VERSION ""

NS_ :

BS_:

BU_: HCM IPMA_ADAS PSCM ABS_ESC PCM ECM_HEV VDM CMR_DSMC SOBDMC_HPCM GWM _delete AWD_DLCM GENERIC TSTR

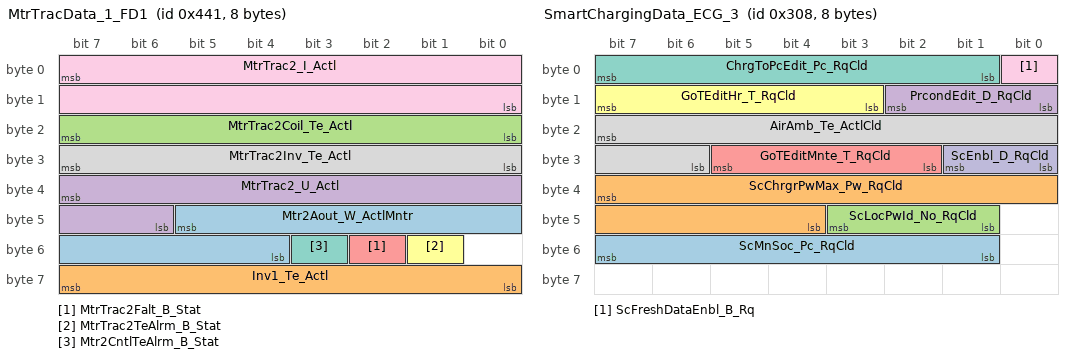
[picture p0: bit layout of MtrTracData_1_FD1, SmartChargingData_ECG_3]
BO_ 1089 MtrTracData_1_FD1: 8 SOBDMC_HPCM
 SG_ Mtr2Aout_W_ActlMntr : 45|10@0+ (6.28,-3209) [-3209|3209.16] "radians/sec"  GWM
 SG_ Inv1_Te_Actl : 63|8@0+ (1,-40) [-40|213] "degC"  GWM
 SG_ MtrTrac2Coil_Te_Actl : 23|8@0+ (1,-40) [-40|213] "degC"  GWM
 SG_ MtrTrac2_U_Actl : 39|10@0+ (1,0) [0|1023] "volt"  GWM
 SG_ MtrTrac2Falt_B_Stat : 50|1@0+ (1,0) [0|1] "SED"  GWM
 SG_ MtrTrac2TeAlrm_B_Stat : 49|1@0+ (1,0) [0|1] "SED"  GWM
 SG_ Mtr2CntlTeAlrm_B_Stat : 51|1@0+ (1,0) [0|1] "SED"  GWM
 SG_ MtrTrac2Inv_Te_Actl : 31|8@0+ (1,-40) [-40|213] "degC"  GWM
 SG_ MtrTrac2_I_Actl : 7|16@0+ (0.1,-1000) [-1000|5553.4] "ampere"  GWM

BO_ 1778 TesterPhysicalReqSODCMC: 64 TSTR
 SG_ TesterPhysicalReqSODCMC : 7|64@0+ (1,0) [0|1.84467E+019] "unitless"  IPMA_ADAS

BO_ 776 SmartChargingData_ECG_3: 8 GWM
 SG_ ScMnSoc_Pc_RqCld : 55|7@0+ (1,0) [0|127] "percent"  SOBDMC_HPCM
 SG_ ScChrgrPwMax_Pw_RqCld : 39|12@0+ (50,0) [0|204700] "watts"  SOBDMC_HPCM
 SG_ ScLocPwId_No_RqCld : 43|3@0+ (1,0) [0|7] "unitless"  SOBDMC_HPCM
 SG_ PrcondEdit_D_RqCld : 10|3@0+ (1,0) [0|7] "SED"  SOBDMC_HPCM
 SG_ GoTEditMnte_T_RqCld : 29|4@0+ (1,0) [0|15] "SED"  SOBDMC_HPCM
 SG_ GoTEditHr_T_RqCld : 15|5@0+ (1,0) [0|29] "SED"  SOBDMC_HPCM
 SG_ ChrgToPcEdit_Pc_RqCld : 7|7@0+ (1,0) [0|125] "percent"  SOBDMC_HPCM
 SG_ AirAmb_Te_ActlCld : 23|10@0+ (0.25,-128) [-128|127.75] "degC"  SOBDMC_HPCM
 SG_ ScFreshDataEnbl_B_Rq : 0|1@0+ (1,0) [0|1] "SED"  SOBDMC_HPCM
 SG_ ScEnbl_D_RqCld : 25|2@0+ (1,0) [0|3] "SED"  SOBDMC_HPCM

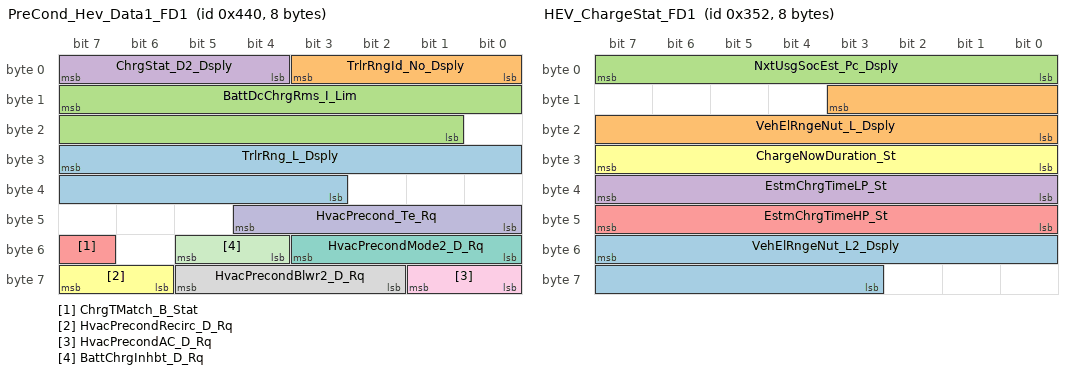
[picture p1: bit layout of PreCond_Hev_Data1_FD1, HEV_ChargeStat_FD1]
BO_ 1088 PreCond_Hev_Data1_FD1: 8 SOBDMC_HPCM
 SG_ TrlrRng_L_Dsply : 31|13@0+ (0.1,0) [0|818.9] "kilometer"  GWM
 SG_ TrlrRngId_No_Dsply : 3|4@0+ (1,0) [0|15] "unitless"  GWM
 SG_ BattDcChrgRms_I_Lim : 15|15@0+ (0.05,0) [0|1638.25] "ampere"  GWM
 SG_ ChrgStat_D2_Dsply : 7|4@0+ (1,0) [0|15] "SED"  GWM
 SG_ ChrgTMatch_B_Stat : 55|1@0+ (1,0) [0|1] "SED"  GWM,GENERIC
 SG_ HvacPrecondRecirc_D_Rq : 63|2@0+ (1,0) [0|3] "SED"  GWM,GENERIC
 SG_ HvacPrecondMode2_D_Rq : 51|4@0+ (1,0) [0|15] "SED"  GWM,GENERIC
 SG_ HvacPrecondBlwr2_D_Rq : 61|4@0+ (1,0) [0|15] "SED"  GWM,GENERIC
 SG_ HvacPrecondAC_D_Rq : 57|2@0+ (1,0) [0|3] "SED"  GWM,GENERIC
 SG_ HvacPrecond_Te_Rq : 44|5@0+ (0.5,14.5) [14.5|30] "deg C"  GWM,GENERIC
 SG_ BattChrgInhbt_D_Rq : 53|2@0+ (1,0) [0|3] "SED"  GWM,GENERIC

BO_ 850 HEV_ChargeStat_FD1: 8 SOBDMC_HPCM
 SG_ VehElRngeNut_L2_Dsply : 55|13@0+ (0.1,0) [0|818.9] "km"  GWM
 SG_ VehElRngeNut_L_Dsply : 11|12@0+ (0.1,0) [0|409.3] "km"  GWM
 SG_ NxtUsgSocEst_Pc_Dsply : 7|8@0+ (0.5,0) [0|126.5] "unitless"  GWM
 SG_ EstmChrgTimeLP_St : 39|8@0+ (0.1,0) [0|25.4] "hour"  GWM
 SG_ EstmChrgTimeHP_St : 47|8@0+ (0.1,0) [0|25.4] "hour"  GWM
 SG_ ChargeNowDuration_St : 31|8@0+ (0.1,0) [0|25.4] "hour"  GWM

BO_ 1795 TesterPhysicalReqAWD: 64 TSTR
 SG_ TesterPhysicalReqAWD : 7|64@0+ (1,0) [0|1.84467E+019] "unitless"  AWD_DLCM

BO_ 1803 TesterPhysicalResAWD: 64 AWD_DLCM
 SG_ TesterPhysicalResAWD : 7|64@0+ (1,0) [0|1.84467E+019] "unitless"  TSTR

BO_ 2611026136 PARSEDPhysGWM_ECGtoSODCMD: 64 GWM
 SG_ PARSEDPhysGWM_ECGtoSODCMD : 7|29@0+ (1,0) [0|536870911] "unitless"  IPMA_ADAS

BO_ 2611175494 PARSEDPhysSODCMDtoGWM_ECG: 64 IPMA_ADAS
 SG_ PARSEDPhysSODCMDtoGWM_ECG : 7|29@0+ (1,0) [0|536870911] "unitless"  GWM

BO_ 2612224070 PARSEDPushSODCMDtoGWM: 8 IPMA_ADAS
 SG_ PARSEDPushSODCMDtoGWM : 7|29@0+ (1,0) [0|536870911] "unitless"  GWM

BO_ 2611054808 PARSEDPhysGWM_ECGtoSODL: 64 GWM
 SG_ PARSEDPhysGWM_ECGtoSODL : 7|29@0+ (1,0) [0|536870911] "unitless"  IPMA_ADAS

BO_ 2611175523 PARSEDPhysSODRtoGWM_ECG: 64 IPMA_ADAS
 SG_ PARSEDPhysSODRtoGWM_ECG : 7|29@0+ (1,0) [0|536870911] "unitless"  GWM

BO_ 2612224099 PARSEDPushSODRtoGWM_ECG: 8 IPMA_ADAS
 SG_ PARSEDPushSODRtoGWM_ECG : 7|29@0+ (1,0) [0|536870911] "unitless"  GWM

BO_ 2611055832 PARSEDPhysGWM_ECGtoSODR: 64 GWM
 SG_ PARSEDPhysGWM_ECGtoSODR : 7|29@0+ (1,0) [0|536870911] "unitless"  IPMA_ADAS

BO_ 2611175522 PARSEDPhysSODLtoGWM_ECG: 64 IPMA_ADAS
 SG_ PARSEDPhysSODLtoGWM_ECG : 7|29@0+ (1,0) [0|536870911] "unitless"  GWM

BO_ 2612224098 PARSEDPushSODLtoGWM_ECG: 8 IPMA_ADAS
 SG_ PARSEDPushSODLtoGWM_ECG : 7|29@0+ (1,0) [0|536870911] "unitless"  GWM

BO_ 2609927384 OTAPhysGWM_ECGtoCCM: 64 GWM
 SG_ OTAPhysGWM_ECGtoCCM : 7|29@0+ (1,0) [0|536870911] "unitless"  IPMA_ADAS

BO_ 2610126869 OTAPhysCCMtoGWM_ECG: 64 IPMA_ADAS
 SG_ OTAPhysCCMtoGWM_ECG : 7|29@0+ (1,0) [0|536870911] "unitless"  GWM

BO_ 2609976536 OTAPhysGWM_ECGtoSODCMC: 64 GWM
 SG_ OTAPhysGWM_ECGtoSODCMC : 7|29@0+ (1,0) [0|536870911] "unitless"  IPMA_ADAS

BO_ 2610126917 OTAPhysSODCMCtoGWM_ECG: 64 IPMA_ADAS
 SG_ OTAPhysSODCMCtoGWM_ECG : 7|29@0+ (1,0) [0|536870911] "unitless"  GWM

BO_ 2609977560 OTAPhysGWM_ECGtoSODCMD: 64 GWM
 SG_ OTAPhysGWM_ECGtoSODCMD : 7|29@0+ (1,0) [0|536870911] "unitless"  IPMA_ADAS

BO_ 2610126918 OTAPhysSODCMDtoGWM_ECG: 64 IPMA_ADAS
 SG_ OTAPhysSODCMDtoGWM_ECG : 7|29@0+ (1,0) [0|536870911] "unitless"  GWM

BO_ 2610007256 OTAPhysGWM_ECGtoSODR: 64 GWM
 SG_ OTAPhysGWM_ECGtoSODR : 7|29@0+ (1,0) [0|536870911] "unitless"  IPMA_ADAS

BO_ 2610126947 OTAPhysSODRtoGWM_ECG: 64 IPMA_ADAS
 SG_ OTAPhysSODRtoGWM_ECG : 7|29@0+ (1,0) [0|536870911] "unitless"  GWM

BO_ 2612224017 PARSEDPushSOBDMCtoGWM_FD1: 8 SOBDMC_HPCM
 SG_ PARSEDPushSOBDMCtoGWM_ECG : 7|29@0+ (1,0) [0|536870911] "unitless"  GWM

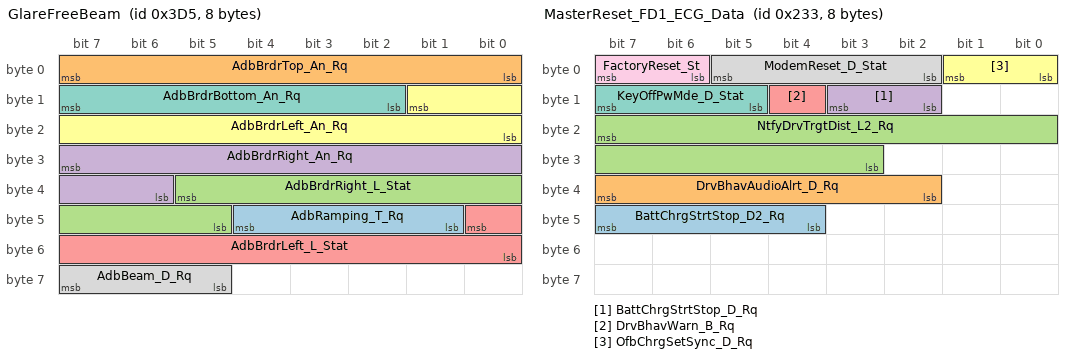
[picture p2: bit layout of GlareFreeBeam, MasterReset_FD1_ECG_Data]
BO_ 981 GlareFreeBeam: 8 IPMA_ADAS
 SG_ AdbRamping_T_Rq : 44|4@0+ (200,0) [0|3000] "millisecond"  HCM,GWM
 SG_ AdbBrdrTop_An_Rq : 7|8@0+ (0.04,-9.54) [-9.54|0.58] "degrees"  HCM,GWM
 SG_ AdbBrdrRight_L_Stat : 37|9@0+ (2,0) [0|1018] "meter"  HCM,GWM
 SG_ AdbBrdrRight_An_Rq : 31|10@0+ (0.04,-20.4) [-20.4|20.44] "degrees"  HCM,GWM
 SG_ AdbBrdrLeft_L_Stat : 40|9@0+ (2,0) [0|1018] "meter"  HCM,GWM
 SG_ AdbBrdrLeft_An_Rq : 9|10@0+ (0.04,-20.4) [-20.4|20.44] "degrees"  HCM,GWM
 SG_ AdbBrdrBottom_An_Rq : 15|6@0+ (0.04,-1.86) [-1.86|0.58] "degrees"  HCM,GWM
 SG_ AdbBeam_D_Rq : 63|3@0+ (1,0) [0|7] "SED"  HCM,GWM

BO_ 810 ECG_Data_FD1: 8 GWM
 SG_ VehHorn_B_RqOccAlrt : 58|1@0+ (1,0) [0|1] "SED"  GENERIC
 SG_ RmtViewMde_B_Rq : 59|1@0+ (1,0) [0|1] "SED"  GENERIC
 SG_ DteCldAcceptData_B_Rq : 60|1@0+ (1,0) [0|1] "SED"  SOBDMC_HPCM
 SG_ DteCldCnclRoute_B_Rq : 61|1@0+ (1,0) [0|1] "SED"  SOBDMC_HPCM
 SG_ NtfyDrvTrgtDist_L_Rq : 23|12@0+ (0.1,0) [0|409.5] "Km"  SOBDMC_HPCM
 SG_ NtfyDrvSocLvl1_Pc_Rq : 39|7@0+ (1,0) [0|127] "%"  SOBDMC_HPCM
 SG_ PtRmtRprt_D_Stat : 27|4@0+ (1,0) [0|15] "SED"  SOBDMC_HPCM
 SG_ ChrgrPncEnbl_D_Rq : 9|2@0+ (1,0) [0|3] "SED"  GENERIC
 SG_ OneTEditActv_B_RqCld : 32|1@0+ (1,0) [0|1] "SED"  SOBDMC_HPCM
 SG_ GoTElementEdit_No_RqCld : 43|4@0+ (1,0) [0|15] "unitless"  SOBDMC_HPCM
 SG_ OBCCSerial_D_Rq : 45|2@0+ (1,0) [0|3] "SED"  GENERIC
 SG_ ExtLghtDsply_B_StatArb : 7|1@0+ (1,0) [0|1] "SED"  GENERIC
 SG_ ExtLghtRight_D_RqOta : 12|3@0+ (1,0) [0|7] "SED"  GENERIC
 SG_ ExtLghtRear_D_RqOta : 15|3@0+ (1,0) [0|7] "SED"  GENERIC
 SG_ ExtLghtLeft_D_RqOta : 3|3@0+ (1,0) [0|7] "SED"  GENERIC
 SG_ ExtLghtFront_D_RqOta : 6|3@0+ (1,0) [0|7] "SED"  GENERIC
 SG_ TlghtTest_D_RqArb : 47|2@0+ (1,0) [0|3] "SED"  GENERIC
 SG_ ChrgrPncSustn_B_Rq : 0|1@0+ (1,0) [0|1] "SED"  GENERIC
 SG_ GoTAirAmb_Te_ActlCld : 55|10@0+ (0.25,-128) [-128|127.75] "degC"  SOBDMC_HPCM

BO_ 563 MasterReset_FD1_ECG_Data: 8 GWM
 SG_ BattChrgStrtStop_D2_Rq : 47|4@0+ (1,0) [0|15] "SED"  SOBDMC_HPCM
 SG_ DrvBhavAudioAlrt_D_Rq : 39|6@0+ (1,0) [0|63] "SED"  GENERIC
 SG_ NtfyDrvTrgtDist_L2_Rq : 23|13@0+ (0.1,0) [0|818.9] "Km" Vector__XXX
 SG_ BattChrgStrtStop_D_Rq : 11|2@0+ (1,0) [0|3] "SED" Vector__XXX
 SG_ DrvBhavWarn_B_Rq : 12|1@0+ (1,0) [0|1] "SED"  GENERIC
 SG_ OfbChrgSetSync_D_Rq : 1|2@0+ (1,0) [0|3] "SED"  SOBDMC_HPCM
 SG_ KeyOffPwMde_D_Stat : 15|3@0+ (1,0) [0|7] "SED"  GENERIC
 SG_ ModemReset_D_Stat : 5|4@0+ (1,0) [0|15] "SED"  GENERIC
 SG_ FactoryReset_St : 7|2@0+ (1,0) [0|3] "SED"  GENERIC

BO_ 2609923288 OTAPhysGWM_ECGtoSOBDMC_FD1: 64 GWM
 SG_ OTAPhysGWM_ECGtoSOBDMC : 7|29@0+ (1,0) [0|536870911] "unitless"  SOBDMC_HPCM

BO_ 2610126865 OTAPhysSOBDMCtoGWM_FD1: 64 SOBDMC_HPCM
 SG_ OTAPhysSOBDMCtoGWM_ECG : 7|29@0+ (1,0) [0|536870911] "unitless"  GWM

BO_ 2610971864 PARSEDPhysGWMtoSOBDMC_FD1: 64 GWM
 SG_ PARSEDPhysGWM_ECGtoSOBDMC : 7|29@0+ (1,0) [0|536870911] "unitless"  SOBDMC_HPCM

BO_ 2611175441 PARSEDPhysSOBDMCtoGWM_FD1: 64 SOBDMC_HPCM
 SG_ PARSEDPhysSOBDMCtoGWM_ECG : 7|29@0+ (1,0) [0|536870911] "unitless"  GWM

BO_ 2610126946 OTAPhysSODLtoGWM_ECG: 64 IPMA_ADAS
 SG_ OTAPhysSODLtoGWM_ECG : 7|29@0+ (1,0) [0|536870911] "unitless"  GWM

BO_ 2610006232 OTAPhysGWM_ECGtoSODL: 64 GWM
 SG_ OTAPhysGWM_ECGtoSODL : 7|29@0+ (1,0) [0|536870911] "unitless"  IPMA_ADAS

BO_ 1993 TesterPhysicalResCMR_DSMC: 64 CMR_DSMC
 SG_ TesterPhysicalResCMR_DSMC : 7|64@0+ (1,0) [0|1.84467E+019] "unitless"  TSTR

BO_ 1985 TesterPhysicalReqCMR_DSMC: 64 TSTR
 SG_ TesterPhysicalReqCMR_DSMC : 7|64@0+ (1,0) [0|1.84467E+019] "unitless"  CMR_DSMC

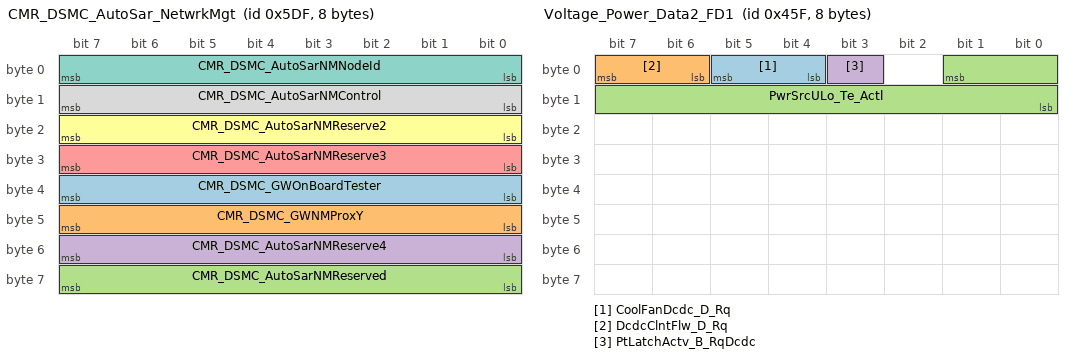
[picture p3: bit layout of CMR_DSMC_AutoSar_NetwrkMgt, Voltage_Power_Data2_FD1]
BO_ 1503 CMR_DSMC_AutoSar_NetwrkMgt: 8 CMR_DSMC
 SG_ CMR_DSMC_GWOnBoardTester : 39|8@0+ (1,0) [0|255] "unitless"  GENERIC
 SG_ CMR_DSMC_GWNMProxY : 47|8@0+ (1,0) [0|255] "unitless"  GENERIC
 SG_ CMR_DSMC_AutoSarNMReserved : 63|8@0+ (1,0) [0|255] "unitless"  GENERIC
 SG_ CMR_DSMC_AutoSarNMReserve4 : 55|8@0+ (1,0) [0|255] "unitless"  GENERIC
 SG_ CMR_DSMC_AutoSarNMReserve3 : 31|8@0+ (1,0) [0|255] "unitless"  GENERIC
 SG_ CMR_DSMC_AutoSarNMReserve2 : 23|8@0+ (1,0) [0|255] "unitless"  GENERIC
 SG_ CMR_DSMC_AutoSarNMNodeId : 7|8@0+ (1,0) [0|255] "unitless"  GENERIC
 SG_ CMR_DSMC_AutoSarNMControl : 15|8@0+ (1,0) [0|255] "unitless"  GENERIC

BO_ 1119 Voltage_Power_Data2_FD1: 8 GWM
 SG_ CoolFanDcdc_D_Rq : 5|2@0+ (1,0) [0|3] "SED"  SOBDMC_HPCM
 SG_ DcdcClntFlw_D_Rq : 7|2@0+ (1,0) [0|3] "SED"  SOBDMC_HPCM
 SG_ PwrSrcULo_Te_Actl : 1|10@0+ (0.5,-50) [-50|460.5] "degC" Vector__XXX
 SG_ PtLatchActv_B_RqDcdc : 3|1@0+ (1,0) [0|1] "SED" Vector__XXX

BO_ 2022 TesterPhysicalReqSOBDMC_FD: 64 TSTR
 SG_ TesterPhysicalReqSOBDMC : 7|64@0+ (1,0) [0|1.84467E+019] "unitless"  SOBDMC_HPCM

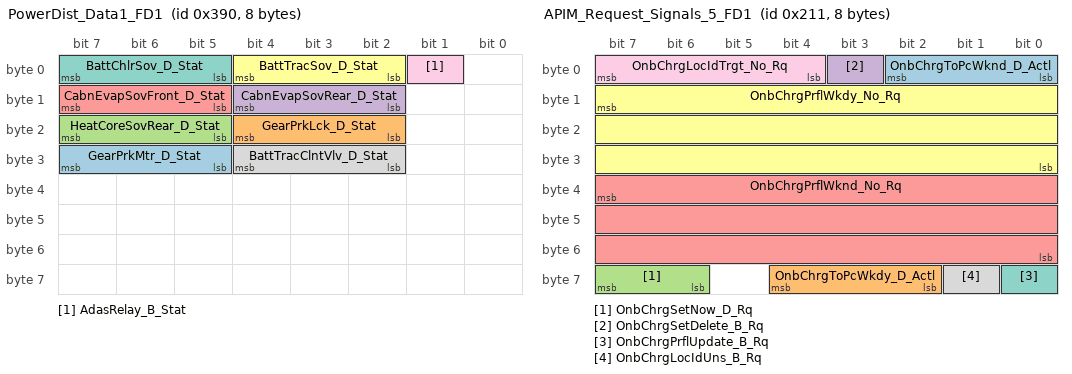
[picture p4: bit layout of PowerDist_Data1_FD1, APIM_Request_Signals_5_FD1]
BO_ 912 PowerDist_Data1_FD1: 8 GWM
 SG_ GearPrkMtr_D_Stat : 31|3@0+ (1,0) [0|7] "SED"  SOBDMC_HPCM
 SG_ GearPrkLck_D_Stat : 20|3@0+ (1,0) [0|7] "SED"  SOBDMC_HPCM
 SG_ HeatCoreSovRear_D_Stat : 23|3@0+ (1,0) [0|7] "SED" Vector__XXX
 SG_ CabnEvapSovRear_D_Stat : 12|3@0+ (1,0) [0|7] "SED" Vector__XXX
 SG_ CabnEvapSovFront_D_Stat : 15|3@0+ (1,0) [0|7] "SED"  SOBDMC_HPCM
 SG_ BattTracSov_D_Stat : 4|3@0+ (1,0) [0|7] "SED" Vector__XXX
 SG_ BattChlrSov_D_Stat : 7|3@0+ (1,0) [0|7] "SED"  SOBDMC_HPCM
 SG_ BattTracClntVlv_D_Stat : 28|3@0+ (1,0) [0|7] "SED"  SOBDMC_HPCM
 SG_ AdasRelay_B_Stat : 1|1@0+ (1,0) [0|1] "SED"  GENERIC

BO_ 651 TCU_Send_Signals_FD1: 8 GWM
 SG_ TelematicsSrvc_D_St : 47|3@0+ (1,0) [0|7] "SED" Vector__XXX
 SG_ EmgcyCallMute_D_Stat : 39|3@0+ (1,0) [0|7] "SED"  GENERIC

BO_ 2609955032 OTAPhysGWM_ECGtoPSCM: 64 GWM
 SG_ OTAPhysGWM_ECGtoPSCM : 7|29@0+ (1,0) [0|536870911] "unitless"  PSCM

BO_ 2610126896 OTAPhysPSCMtoGWM_ECG: 64 PSCM
 SG_ OTAPhysPSCMtoGWM_ECG : 7|29@0+ (1,0) [0|536870911] "unitless"  GWM

BO_ 2611003608 PARSEDPhysGWM_ECGtoPSCM: 64 GWM
 SG_ PARSEDPhysGWM_ECGtoPSCM : 7|29@0+ (1,0) [0|536870911] "unitless"  PSCM

BO_ 2612224048 PARSEDPushPSCMtoGWM_ECG: 8 PSCM
 SG_ PARSEDPushPSCMtoGWM_ECG : 7|29@0+ (1,0) [0|536870911] "unitless"  GWM

BO_ 2611175472 PARSEDPhysPSCMtoGWM_ECG: 64 PSCM
 SG_ PARSEDPhysPSCMtoGWM_ECG : 7|29@0+ (1,0) [0|536870911] "unitless"  GWM

BO_ 1150 LocationServices_Data1_FD1: 8 GWM
 SG_ LocationServices_1 : 7|64@0+ (1,0) [0|1.84467440737096E+019] "unitless"  SOBDMC_HPCM,HCM,IPMA_ADAS

BO_ 2612224033 PARSEDPushIPMAtoGWM_ECG: 8 IPMA_ADAS
 SG_ PARSEDPushIPMAtoGWM_ECG : 7|29@0+ (1,0) [0|536870911] "unitless"  GWM

BO_ 2609939672 OTAPhysGWM_ECGtoIPMA: 64 GWM
 SG_ OTAPhysGWM_ECGtoIPMA : 7|29@0+ (1,0) [0|536870911] "unitless"  IPMA_ADAS

BO_ 2610126881 OTAPhysIPMAtoGWM_ECG: 64 IPMA_ADAS
 SG_ OTAPhysIPMAtoGWM_ECG : 7|29@0+ (1,0) [0|536870911] "unitless"  GWM

BO_ 2612043992 PARSEDPushFcGWM_ECGtoABS: 8 GWM
 SG_ PARSEDPushFcGWM_ECGtoABS : 7|29@0+ (1,0) [0|536870911] "unitless"  ABS_ESC

BO_ 2610995416 PARSEDPhysGWM_ECGtoABS: 64 GWM
 SG_ PARSEDPhysGWM_ECGtoABS : 7|29@0+ (1,0) [0|536870911] "unitless"  ABS_ESC

BO_ 2612224040 PARSEDPushABStoGWM_ECG: 8 ABS_ESC
 SG_ PARSEDPushABStoGWM_ECG : 7|29@0+ (1,0) [0|536870911] "unitless"  GWM

BO_ 2611175464 PARSEDPhysABStoGWM_ECG: 64 ABS_ESC
 SG_ PARSEDPhysABStoGWM_ECG : 7|29@0+ (1,0) [0|536870911] "Unitless"  GWM

BO_ 529 APIM_Request_Signals_5_FD1: 8 GWM
 SG_ OnbChrgToPcWknd_D_Actl : 2|3@0+ (1,0) [0|7] "percent"  SOBDMC_HPCM
 SG_ OnbChrgToPcWkdy_D_Actl : 60|3@0+ (1,0) [0|7] "percent"  SOBDMC_HPCM
 SG_ OnbChrgSetNow_D_Rq : 63|2@0+ (1,0) [0|3] "SED"  SOBDMC_HPCM
 SG_ OnbChrgSetDelete_B_Rq : 3|1@0+ (1,0) [0|1] "SED"  SOBDMC_HPCM
 SG_ OnbChrgPrflWknd_No_Rq : 39|24@0+ (1,0) [0|16777215] "unitless"  SOBDMC_HPCM
 SG_ OnbChrgPrflWkdy_No_Rq : 15|24@0+ (1,0) [0|16777215] "unitless"  SOBDMC_HPCM
 SG_ OnbChrgPrflUpdate_B_Rq : 56|1@0+ (1,0) [0|1] "SED"  SOBDMC_HPCM
 SG_ OnbChrgLocIdUns_B_Rq : 57|1@0+ (1,0) [0|1] "SED"  SOBDMC_HPCM
 SG_ OnbChrgLocIdTrgt_No_Rq : 7|4@0+ (1,0) [0|15] "Unitless"  SOBDMC_HPCM

BO_ 1679 SOBDMC_RapidData_Resp4_FD1: 8 SOBDMC_HPCM
 SG_ UUDTSOBDMCResponse4 : 7|64@0+ (1,0) [0|1.84467440737096E+019] "unitless"  TSTR

BO_ 1678 SOBDMC_RapidData_Resp3_FD1: 8 SOBDMC_HPCM
 SG_ UUDTSOBDMCResponse3 : 7|64@0+ (1,0) [0|1.84467440737096E+019] "unitless"  TSTR

BO_ 1677 SOBDMC_RapidData_Resp2_FD1: 8 SOBDMC_HPCM
 SG_ UUDTSOBDMCResponse2 : 7|64@0+ (1,0) [0|1.84467440737096E+019] "unitless"  TSTR

BO_ 1676 SOBDMC_RapidData_Resp1_FD1: 8 SOBDMC_HPCM
 SG_ UUDTSOBDMCResponse1 : 7|64@0+ (1,0) [0|1.84467440737096E+019] "unitless"  TSTR

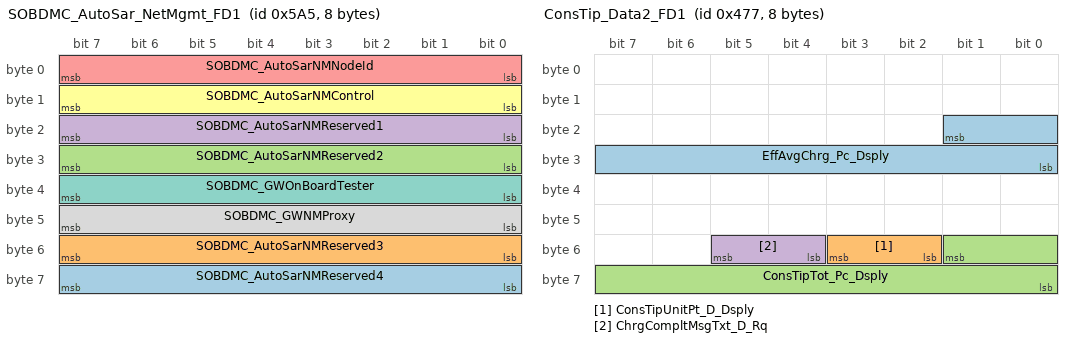
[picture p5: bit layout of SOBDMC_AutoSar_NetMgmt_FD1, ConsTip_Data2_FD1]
BO_ 1445 SOBDMC_AutoSar_NetMgmt_FD1: 8 SOBDMC_HPCM
 SG_ SOBDMC_AutoSarNMReserved4 : 63|8@0+ (1,0) [0|255] "unitless"  GWM,ECM_HEV
 SG_ SOBDMC_AutoSarNMReserved3 : 55|8@0+ (1,0) [0|255] "unitless"  GWM,ECM_HEV
 SG_ SOBDMC_AutoSarNMReserved2 : 31|8@0+ (1,0) [0|255] "unitless"  GWM,ECM_HEV
 SG_ SOBDMC_AutoSarNMReserved1 : 23|8@0+ (1,0) [0|255] "unitless"  GWM,ECM_HEV
 SG_ SOBDMC_AutoSarNMNodeId : 7|8@0+ (1,0) [0|255] "unitless"  GWM,ECM_HEV
 SG_ SOBDMC_AutoSarNMControl : 15|8@0+ (1,0) [0|255] "unitless"  GWM,ECM_HEV
 SG_ SOBDMC_GWOnBoardTester : 39|8@0+ (1,0) [0|255] "unitless"  GWM,ECM_HEV
 SG_ SOBDMC_GWNMProxy : 47|8@0+ (1,0) [0|255] "unitless"  GWM,ECM_HEV

BO_ 1143 ConsTip_Data2_FD1: 8 SOBDMC_HPCM
 SG_ EffAvgChrg_Pc_Dsply : 17|10@0+ (0.1,0) [0|102.3] "percent"  GWM
 SG_ ConsTipUnitPt_D_Dsply : 51|2@0+ (1,0) [0|3] "SED"  GWM
 SG_ ConsTipTot_Pc_Dsply : 49|10@0+ (0.1,0) [0|102.1] "percent"  GWM
 SG_ ChrgCompltMsgTxt_D_Rq : 53|2@0+ (1,0) [0|3] "SED"  GWM

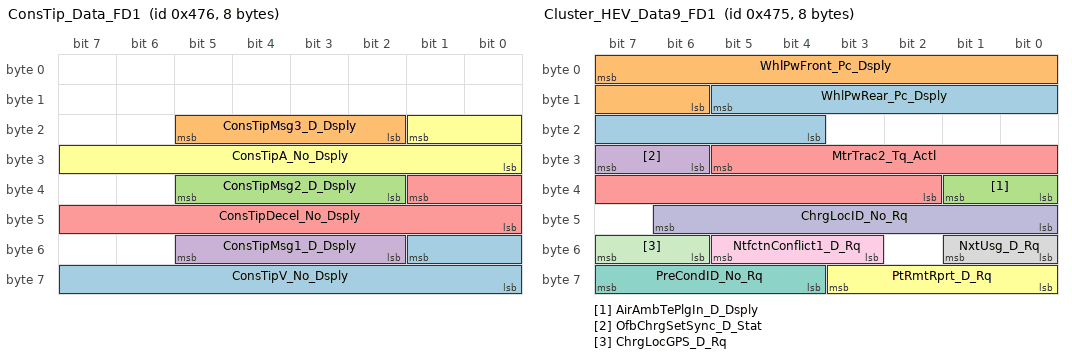
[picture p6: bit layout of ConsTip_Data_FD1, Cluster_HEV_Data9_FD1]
BO_ 1142 ConsTip_Data_FD1: 8 SOBDMC_HPCM
 SG_ ConsTipV_No_Dsply : 49|10@0+ (0.1,0) [0|102.1] "percent"  GWM
 SG_ ConsTipMsg3_D_Dsply : 21|4@0+ (1,0) [0|15] "SED"  GWM
 SG_ ConsTipMsg2_D_Dsply : 37|4@0+ (1,0) [0|15] "SED"  GWM
 SG_ ConsTipMsg1_D_Dsply : 53|4@0+ (1,0) [0|15] "SED"  GWM
 SG_ ConsTipDecel_No_Dsply : 33|10@0+ (0.1,0) [0|102.1] "percent"  GWM
 SG_ ConsTipA_No_Dsply : 17|10@0+ (0.1,0) [0|102.1] "percent"  GWM

BO_ 1141 Cluster_HEV_Data9_FD1: 8 SOBDMC_HPCM
 SG_ WhlPwRear_Pc_Dsply : 13|10@0+ (0.2,-102.2) [-102.2|102.4] "percent"  GWM
 SG_ WhlPwFront_Pc_Dsply : 7|10@0+ (0.2,-102.2) [-102.2|102.4] "percent"  GWM
 SG_ AirAmbTePlgIn_D_Dsply : 33|2@0+ (1,0) [0|3] "SED"  GWM
 SG_ OfbChrgSetSync_D_Stat : 31|2@0+ (1,0) [0|3] "SED"  GWM
 SG_ MtrTrac2_Tq_Actl : 29|12@0+ (1,-2047) [-2047|2048] "Nm"  GWM
 SG_ PtRmtRprt_D_Rq : 59|4@0+ (1,0) [0|15] "SED"  GWM
 SG_ PreCondID_No_Rq : 63|4@0+ (1,0) [0|15] "unitless"  GWM
 SG_ NxtUsg_D_Rq : 49|2@0+ (1,0) [0|3] "SED"  GWM
 SG_ NtfctnConflict1_D_Rq : 53|3@0+ (1,0) [0|7] "SED"  GWM
 SG_ ChrgLocID_No_Rq : 46|7@0+ (1,0) [0|127] "unitless"  GWM
 SG_ ChrgLocGPS_D_Rq : 55|2@0+ (1,0) [0|3] "SED"  GWM

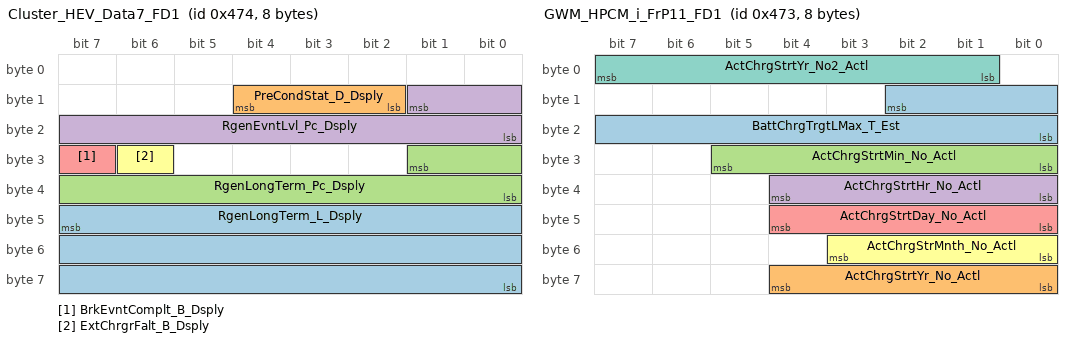
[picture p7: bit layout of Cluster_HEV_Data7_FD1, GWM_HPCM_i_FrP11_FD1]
BO_ 1140 Cluster_HEV_Data7_FD1: 8 SOBDMC_HPCM
 SG_ RgenLongTerm_L_Dsply : 47|24@0+ (0.1,0) [0|1677721.3] "km"  GWM
 SG_ PreCondStat_D_Dsply : 12|3@0+ (1,0) [0|7] "SED"  GWM
 SG_ RgenLongTerm_Pc_Dsply : 25|10@0+ (0.1,0) [0|102.3] "percent"  GWM
 SG_ RgenEvntLvl_Pc_Dsply : 9|10@0+ (0.1,0) [0|102.1] "percent"  GWM
 SG_ BrkEvntComplt_B_Dsply : 31|1@0+ (1,0) [0|1] "SED"  GWM
 SG_ ExtChrgrFalt_B_Dsply : 30|1@0+ (1,0) [0|1] "SED"  GWM

BO_ 1139 GWM_HPCM_i_FrP11_FD1: 8 SOBDMC_HPCM
 SG_ BattChrgTrgtLMax_T_Est : 10|11@0+ (1,0) [0|2045] "minute"  GWM
 SG_ ActChrgStrtYr_No_Actl : 60|5@0+ (1,2010) [2010|2040] "year"  GWM
 SG_ ActChrgStrtMin_No_Actl : 29|6@0+ (1,0) [0|61] "minute"  GWM
 SG_ ActChrgStrtHr_No_Actl : 36|5@0+ (1,0) [0|29] "hour"  GWM
 SG_ ActChrgStrtDay_No_Actl : 44|5@0+ (1,1) [1|31] "days"  GWM
 SG_ ActChrgStrMnth_No_Actl : 51|4@0+ (1,1) [1|15] "month"  GWM
 SG_ ActChrgStrtYr_No2_Actl : 7|7@0+ (1,2017) [2017|2144] "year"  GWM

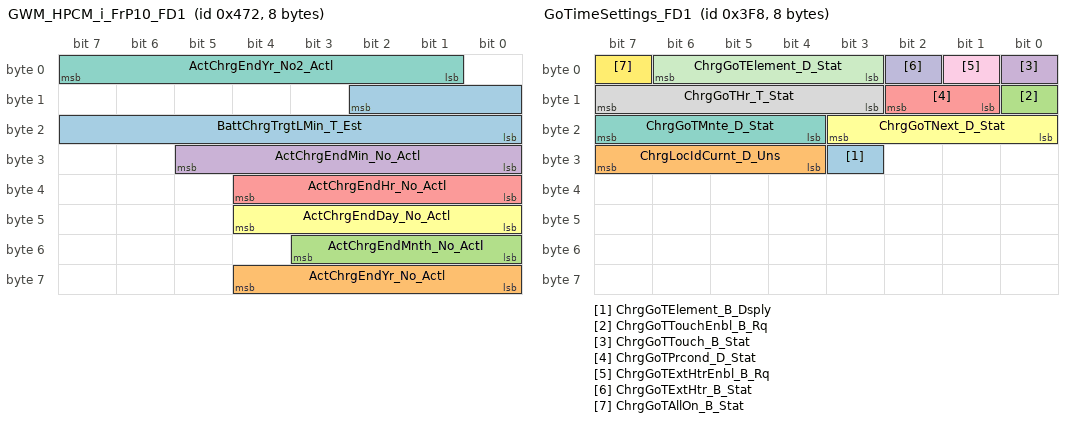
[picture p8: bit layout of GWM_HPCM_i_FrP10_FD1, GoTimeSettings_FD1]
BO_ 1138 GWM_HPCM_i_FrP10_FD1: 8 SOBDMC_HPCM
 SG_ BattChrgTrgtLMin_T_Est : 10|11@0+ (1,0) [0|2045] "minute"  GWM
 SG_ ActChrgEndYr_No_Actl : 60|5@0+ (1,2010) [2010|2040] "year"  GWM
 SG_ ActChrgEndMnth_No_Actl : 51|4@0+ (1,1) [1|15] "month"  GWM
 SG_ ActChrgEndMin_No_Actl : 29|6@0+ (1,0) [0|61] "minute"  GWM
 SG_ ActChrgEndHr_No_Actl : 36|5@0+ (1,0) [0|29] "hour"  GWM
 SG_ ActChrgEndDay_No_Actl : 44|5@0+ (1,1) [1|31] "days"  GWM
 SG_ ActChrgEndYr_No2_Actl : 7|7@0+ (1,2017) [2017|2144] "year"  GWM

BO_ 1016 GoTimeSettings_FD1: 8 SOBDMC_HPCM
 SG_ ChrgGoTElement_B_Dsply : 27|1@0+ (1,0) [0|1] "SED"  GWM
 SG_ ChrgLocIdCurnt_D_Uns : 31|4@0+ (1,0) [0|15] "unitless"  GWM
 SG_ ChrgGoTTouchEnbl_B_Rq : 8|1@0+ (1,0) [0|1] "SED"  GWM
 SG_ ChrgGoTTouch_B_Stat : 0|1@0+ (1,0) [0|1] "SED"  GWM
 SG_ ChrgGoTPrcond_D_Stat : 10|2@0+ (1,0) [0|3] "SED"  GWM
 SG_ ChrgGoTNext_D_Stat : 19|4@0+ (1,0) [0|15] "Unitless"  GWM
 SG_ ChrgGoTMnte_D_Stat : 23|4@0+ (1,0) [0|15] "SED"  GWM
 SG_ ChrgGoTHr_T_Stat : 15|5@0+ (1,0) [0|29] "hour"  GWM
 SG_ ChrgGoTExtHtrEnbl_B_Rq : 1|1@0+ (1,0) [0|1] "SED"  GWM
 SG_ ChrgGoTExtHtr_B_Stat : 2|1@0+ (1,0) [0|1] "SED"  GWM
 SG_ ChrgGoTElement_D_Stat : 6|4@0+ (1,0) [0|15] "Unitless"  GWM
 SG_ ChrgGoTAllOn_B_Stat : 7|1@0+ (1,0) [0|1] "SED"  GWM

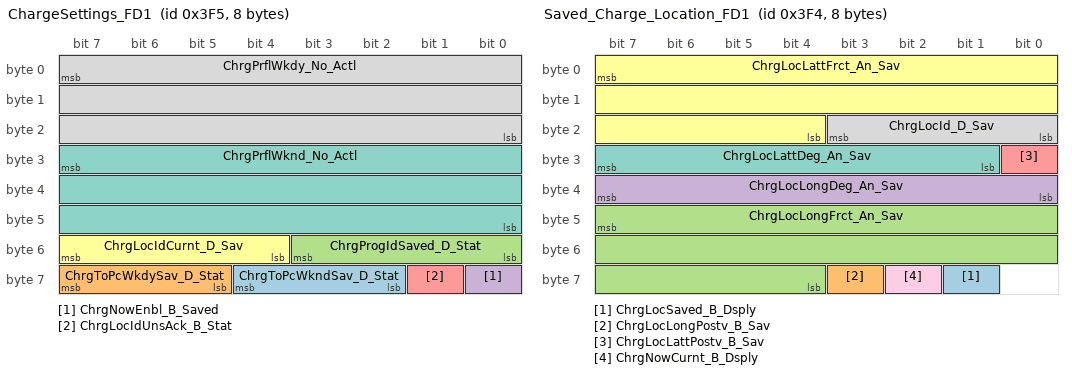
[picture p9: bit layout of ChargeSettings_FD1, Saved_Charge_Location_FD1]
BO_ 1013 ChargeSettings_FD1: 8 SOBDMC_HPCM
 SG_ ChrgToPcWkndSav_D_Stat : 60|3@0+ (1,0) [0|7] "SED"  GWM
 SG_ ChrgToPcWkdySav_D_Stat : 63|3@0+ (1,0) [0|7] "SED"  GWM
 SG_ ChrgProgIdSaved_D_Stat : 51|4@0+ (1,0) [0|15] "Unitless"  GWM
 SG_ ChrgNowEnbl_B_Saved : 56|1@0+ (1,0) [0|1] "SED"  GWM
 SG_ ChrgLocIdUnsAck_B_Stat : 57|1@0+ (1,0) [0|1] "SED"  GWM
 SG_ ChrgLocIdCurnt_D_Sav : 55|4@0+ (1,0) [0|15] "unitless"  GWM
 SG_ ChrgPrflWknd_No_Actl : 31|24@0+ (1,0) [0|16777215] "unitless"  GWM
 SG_ ChrgPrflWkdy_No_Actl : 7|24@0+ (1,0) [0|16777215] "unitless"  GWM

BO_ 1012 Saved_Charge_Location_FD1: 8 SOBDMC_HPCM
 SG_ ChrgLocSaved_B_Dsply : 57|1@0+ (1,0) [0|1] "SED"  GWM
 SG_ ChrgLocLongPostv_B_Sav : 59|1@0+ (1,0) [0|1] "SED"  GWM
 SG_ ChrgLocLongFrct_An_Sav : 47|20@0+ (1E-006,0) [0|1.048575] "degrees"  GWM
 SG_ ChrgLocLongDeg_An_Sav : 39|8@0+ (1,0) [0|255] "degrees"  GWM
 SG_ ChrgLocLattPostv_B_Sav : 24|1@0+ (1,0) [0|1] "SED"  GWM
 SG_ ChrgLocLattFrct_An_Sav : 7|20@0+ (1E-006,0) [0|1.048575] "degrees"  GWM
 SG_ ChrgLocLattDeg_An_Sav : 31|7@0+ (1,0) [0|127] "unitless"  GWM
 SG_ ChrgLocId_D_Sav : 19|4@0+ (1,0) [0|15] "unitless"  GWM
 SG_ ChrgNowCurnt_B_Dsply : 58|1@0+ (1,0) [0|1] "SED"  GWM

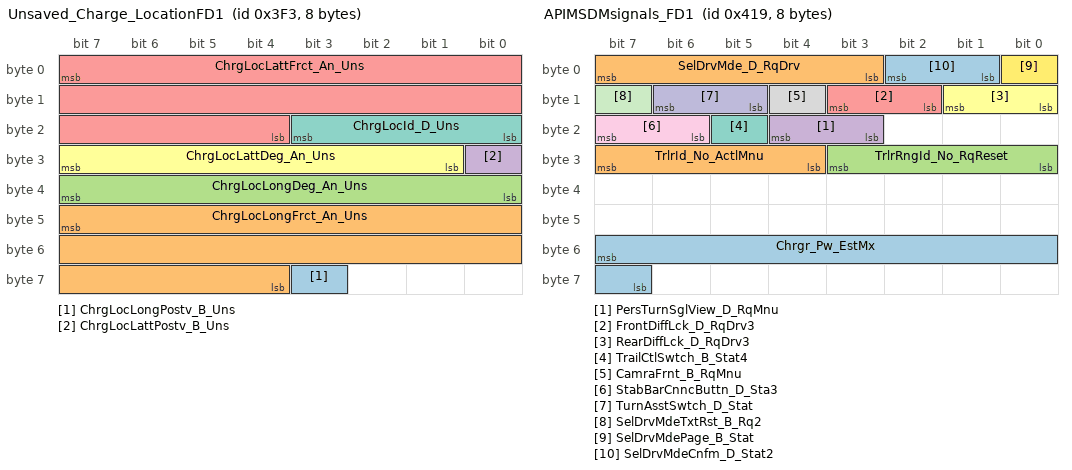
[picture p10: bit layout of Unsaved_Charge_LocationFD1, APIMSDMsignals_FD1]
BO_ 1011 Unsaved_Charge_LocationFD1: 8 SOBDMC_HPCM
 SG_ ChrgLocLongPostv_B_Uns : 59|1@0+ (1,0) [0|1] "SED"  GWM
 SG_ ChrgLocLongFrct_An_Uns : 47|20@0+ (1E-006,0) [0|1.048575] "degrees"  GWM
 SG_ ChrgLocLongDeg_An_Uns : 39|8@0+ (1,0) [0|255] "degrees"  GWM
 SG_ ChrgLocLattPostv_B_Uns : 24|1@0+ (1,0) [0|1] "SED"  GWM
 SG_ ChrgLocLattFrct_An_Uns : 7|20@0+ (1E-006,0) [0|1.048575] "degrees"  GWM
 SG_ ChrgLocLattDeg_An_Uns : 31|7@0+ (1,0) [0|127] "unitless"  GWM
 SG_ ChrgLocId_D_Uns : 19|4@0+ (1,0) [0|15] "unitless"  GWM

BO_ 1049 APIMSDMsignals_FD1: 8 GWM
 SG_ Chrgr_Pw_EstMx : 55|9@0+ (2,0) [0|1018] "kilowatt"  SOBDMC_HPCM
 SG_ TrlrId_No_ActlMnu : 31|4@0+ (1,0) [0|15] "unitless" Vector__XXX
 SG_ TrlrRngId_No_RqReset : 27|4@0+ (1,0) [0|15] "unitless" Vector__XXX
 SG_ PersTurnSglView_D_RqMnu : 20|2@0+ (1,0) [0|3] "SED"  IPMA_ADAS
 SG_ FrontDiffLck_D_RqDrv3 : 11|2@0+ (1,0) [0|3] "SED"  GENERIC
 SG_ RearDiffLck_D_RqDrv3 : 9|2@0+ (1,0) [0|3] "SED" Vector__XXX
 SG_ TrailCtlSwtch_B_Stat4 : 21|1@0+ (1,0) [0|1] "SED" Vector__XXX
 SG_ CamraFrnt_B_RqMnu : 12|1@0+ (1,0) [0|1] "SED"  IPMA_ADAS
 SG_ StabBarCnncButtn_D_Sta3 : 23|2@0+ (1,0) [0|3] "SED"  GENERIC
 SG_ TurnAsstSwtch_D_Stat : 14|2@0+ (1,0) [0|3] "SED" Vector__XXX
 SG_ SelDrvMdeTxtRst_B_Rq2 : 15|1@0+ (1,0) [0|1] "SED"  ABS_ESC
 SG_ SelDrvMdePage_B_Stat : 0|1@0+ (1,0) [0|1] "SED"  ABS_ESC
 SG_ SelDrvMdeCnfm_D_Stat2 : 2|2@0+ (1,0) [0|3] "SED"  ABS_ESC
 SG_ SelDrvMde_D_RqDrv : 7|5@0+ (1,0) [0|31] "SED"  ABS_ESC

BO_ 2611175457 PARSEDPhysIPMAtoGWM_ECG: 64 IPMA_ADAS
 SG_ PARSEDPhysIPMAtoGWM_ECG : 7|29@0+ (1,0) [0|536870911] "unitless"  GWM

BO_ 2609946840 OTAPhysGWM_ECGtoABS: 64 GWM
 SG_ OTAPhysGWM_ECGtoABS : 7|29@0+ (1,0) [0|536870911] "unitless"  ABS_ESC

BO_ 2610126888 OTAPhysABStoGWM_ECG: 64 ABS_ESC
 SG_ OTAPhysABStoGWM_ECG : 7|29@0+ (1,0) [0|536870911] "unitless"  GWM

BO_ 2611175440 PARSEDPhysPCMtoGWM_ECG: 64 PCM
 SG_ PARSEDPhysPCMtoGWM_ECG : 7|29@0+ (1,0) [0|536870911] "unitless"  GWM

BO_ 2609922264 OTAPhysGWM_ECGtoPCM: 64 GWM
 SG_ OTAPhysGWM_ECGtoPCM : 7|29@0+ (1,0) [0|536870911] "unitless"  ECM_HEV,PCM

BO_ 2610953432 OTAFuncGWM_ECG_FD1: 64 GWM
 SG_ OTAFuncGWM_ECG : 7|29@0+ (1,0) [0|536870911] "unitless"  SOBDMC_HPCM,VDM,ABS_ESC,IPMA_ADAS,PSCM,ECM_HEV,PCM,CMR_DSMC

BO_ 2610126864 OTAPhysPCMtoGWM_ECG: 64 PCM
 SG_ OTAPhysPCMtoGWM_ECG : 7|29@0+ (1,0) [0|536870911] "unitless"  GWM

BO_ 2612002008 PARSEDFuncGWM_ECG_FD1: 64 GWM
 SG_ PARSEDFuncGWM_ECG : 7|29@0+ (1,0) [0|536870911] "unitless"  SOBDMC_HPCM,VDM,ABS_ESC,IPMA_ADAS,PSCM,ECM_HEV,PCM,CMR_DSMC

BO_ 2610970840 PARSEDPhysGWM_ECGtoPCM: 64 GWM
 SG_ PARSEDPhysGWM_ECGtoPCM : 7|29@0+ (1,0) [0|536870911] "unitless"  ECM_HEV,PCM

BO_ 2612224016 PARSEDPushPCMtoGWM_ECG: 8 PCM
 SG_ PARSEDPushPCMtoGWM_ECG : 7|29@0+ (1,0) [0|536870911] "unitless"  GWM

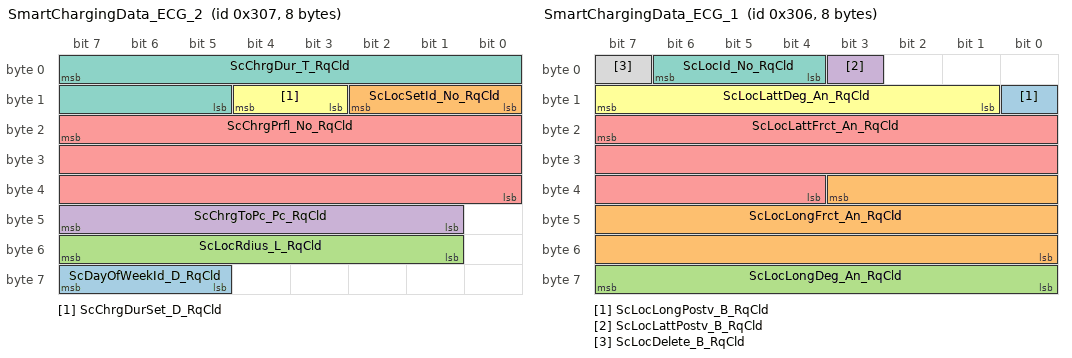
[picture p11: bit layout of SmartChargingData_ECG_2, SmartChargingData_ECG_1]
BO_ 775 SmartChargingData_ECG_2: 8 GWM
 SG_ ScDayOfWeekId_D_RqCld : 63|3@0+ (1,0) [0|7] "SED"  SOBDMC_HPCM
 SG_ ScLocSetId_No_RqCld : 10|3@0+ (1,0) [0|7] "unitless"  SOBDMC_HPCM
 SG_ ScLocRdius_L_RqCld : 55|7@0+ (100,0) [0|12700] "meter"  SOBDMC_HPCM
 SG_ ScChrgToPc_Pc_RqCld : 47|7@0+ (1,0) [0|127] "percent"  SOBDMC_HPCM
 SG_ ScChrgPrfl_No_RqCld : 23|24@0+ (1,0) [0|16777215] "unitless"  SOBDMC_HPCM
 SG_ ScChrgDurSet_D_RqCld : 12|2@0+ (1,0) [0|3] "SED"  SOBDMC_HPCM
 SG_ ScChrgDur_T_RqCld : 7|11@0+ (1,0) [0|2045] "minute"  SOBDMC_HPCM

BO_ 774 SmartChargingData_ECG_1: 8 GWM
 SG_ ScLocLongPostv_B_RqCld : 8|1@0+ (1,0) [0|1] "SED"  SOBDMC_HPCM
 SG_ ScLocLongFrct_An_RqCld : 35|20@0+ (1E-006,0) [0|1.048575] "degrees"  SOBDMC_HPCM
 SG_ ScLocLongDeg_An_RqCld : 63|8@0+ (1,0) [0|255] "degrees"  SOBDMC_HPCM
 SG_ ScLocLattPostv_B_RqCld : 3|1@0+ (1,0) [0|1] "SED"  SOBDMC_HPCM
 SG_ ScLocLattFrct_An_RqCld : 23|20@0+ (1E-006,0) [0|1.048575] "degrees"  SOBDMC_HPCM
 SG_ ScLocLattDeg_An_RqCld : 15|7@0+ (1,0) [0|127] "percent"  SOBDMC_HPCM
 SG_ ScLocId_No_RqCld : 6|3@0+ (1,0) [0|7] "unitless"  SOBDMC_HPCM
 SG_ ScLocDelete_B_RqCld : 7|1@0+ (1,0) [0|1] "SED"  SOBDMC_HPCM

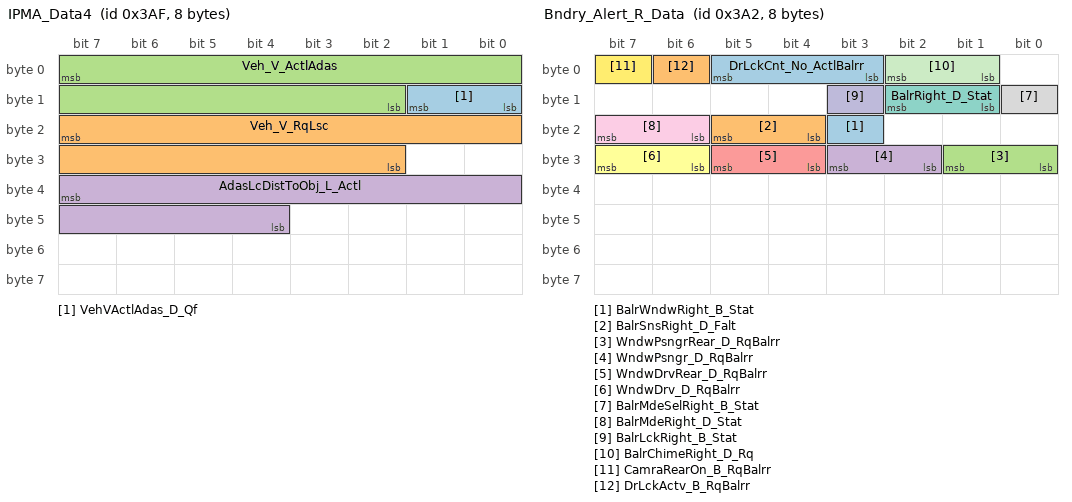
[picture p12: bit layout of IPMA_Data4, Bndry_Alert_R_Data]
BO_ 943 IPMA_Data4: 8 IPMA_ADAS
 SG_ VehVActlAdas_D_Qf : 9|2@0+ (1,0) [0|3] "SED"  ECM_HEV,PCM
 SG_ Veh_V_RqLsc : 23|14@0+ (0.01,0) [0|163.83] "kph"  ECM_HEV,PCM
 SG_ Veh_V_ActlAdas : 7|14@0+ (0.01,0) [0|163.83] "kph"  ECM_HEV,PCM
 SG_ AdasLcDistToObj_L_Actl : 39|12@0+ (0.002,0) [0|8.186] "meter"  ECM_HEV,PCM

BO_ 930 Bndry_Alert_R_Data: 8 IPMA_ADAS
 SG_ BalrWndwRight_B_Stat : 19|1@0+ (1,0) [0|1] "SED"  GWM
 SG_ BalrSnsRight_D_Falt : 21|2@0+ (1,0) [0|3] "SED"  GWM
 SG_ WndwPsngrRear_D_RqBalrr : 25|2@0+ (1,0) [0|3] "SED"  GWM
 SG_ WndwPsngr_D_RqBalrr : 27|2@0+ (1,0) [0|3] "SED"  GWM
 SG_ WndwDrvRear_D_RqBalrr : 29|2@0+ (1,0) [0|3] "SED"  GWM
 SG_ WndwDrv_D_RqBalrr : 31|2@0+ (1,0) [0|3] "SED"  GWM
 SG_ BalrRight_D_Stat : 10|2@0+ (1,0) [0|3] "SED"  GWM
 SG_ BalrMdeSelRight_B_Stat : 8|1@0+ (1,0) [0|1] "SED"  GWM
 SG_ BalrMdeRight_D_Stat : 23|2@0+ (1,0) [0|3] "SED"  GWM
 SG_ BalrLckRight_B_Stat : 11|1@0+ (1,0) [0|1] "SED"  GWM
 SG_ BalrChimeRight_D_Rq : 2|2@0+ (1,0) [0|3] "SED"  GWM
 SG_ CamraRearOn_B_RqBalrr : 7|1@0+ (1,0) [0|1] "SED"  GWM
 SG_ DrLckCnt_No_ActlBalrr : 5|3@0+ (1,0) [0|7] "unitless"  GWM
 SG_ DrLckActv_B_RqBalrr : 6|1@0+ (1,0) [0|1] "SED"  GWM

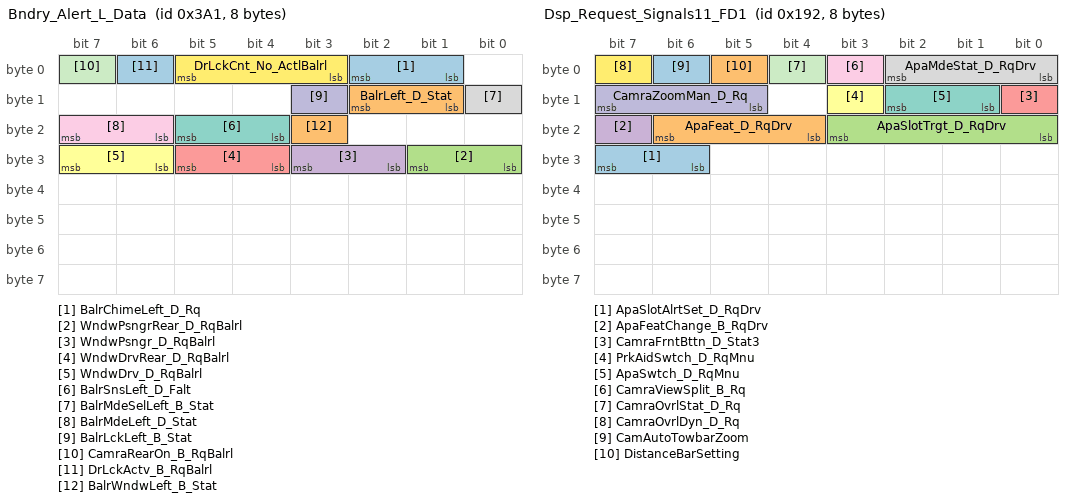
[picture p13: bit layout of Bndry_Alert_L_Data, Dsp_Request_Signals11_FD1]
BO_ 929 Bndry_Alert_L_Data: 8 IPMA_ADAS
 SG_ BalrChimeLeft_D_Rq : 2|2@0+ (1,0) [0|3] "SED"  GWM
 SG_ BalrLeft_D_Stat : 10|2@0+ (1,0) [0|3] "SED"  GWM
 SG_ WndwPsngrRear_D_RqBalrl : 25|2@0+ (1,0) [0|3] "SED"  GWM
 SG_ WndwPsngr_D_RqBalrl : 27|2@0+ (1,0) [0|3] "SED"  GWM
 SG_ WndwDrvRear_D_RqBalrl : 29|2@0+ (1,0) [0|3] "SED"  GWM
 SG_ WndwDrv_D_RqBalrl : 31|2@0+ (1,0) [0|3] "SED"  GWM
 SG_ BalrSnsLeft_D_Falt : 21|2@0+ (1,0) [0|3] "SED"  GWM
 SG_ BalrMdeSelLeft_B_Stat : 8|1@0+ (1,0) [0|1] "SED"  GWM
 SG_ BalrMdeLeft_D_Stat : 23|2@0+ (1,0) [0|3] "SED"  GWM
 SG_ BalrLckLeft_B_Stat : 11|1@0+ (1,0) [0|1] "SED"  GWM
 SG_ CamraRearOn_B_RqBalrl : 7|1@0+ (1,0) [0|1] "SED"  GWM
 SG_ DrLckCnt_No_ActlBalrl : 5|3@0+ (1,0) [0|7] "unitless"  GWM
 SG_ DrLckActv_B_RqBalrl : 6|1@0+ (1,0) [0|1] "SED"  GWM
 SG_ BalrWndwLeft_B_Stat : 19|1@0+ (1,0) [0|1] "SED"  GWM

BO_ 1783 TesterPhysicalReqLDCMB: 64 TSTR
 SG_ TesterPhysicalReqLDCMB : 7|64@0+ (1,0) [0|1.84467E+019] "unitless"  HCM

BO_ 2612194520 PARSEDPushFcGWM_ECGtoCMR: 8 GWM
 SG_ PARSEDPushFcGWM_ECGtoCMR : 7|29@0+ (1,0) [0|536870911] "unitless"  CMR_DSMC

BO_ 2610127035 OTAPhysCMRtoGWM_ECG: 64 CMR_DSMC
 SG_ OTAPhysCMRtoGWM_ECG : 7|29@0+ (1,0) [0|536870911] "unitless"  GWM

BO_ 2610097368 OTAPhysGWM_ECGtoCMR: 64 GWM
 SG_ OTAPhysGWM_ECGtoCMR : 7|29@0+ (1,0) [0|536870911] "unitless"  CMR_DSMC

BO_ 402 Dsp_Request_Signals11_FD1: 8 GWM
 SG_ ApaSlotAlrtSet_D_RqDrv : 31|2@0+ (1,0) [0|3] "SED"  IPMA_ADAS
 SG_ ApaFeat_D_RqDrv : 22|3@0+ (1,0) [0|7] "SED"  IPMA_ADAS
 SG_ ApaSlotTrgt_D_RqDrv : 19|4@0+ (1,0) [0|15] "SED"  IPMA_ADAS
 SG_ ApaFeatChange_B_RqDrv : 23|1@0+ (1,0) [0|1] "SED"  IPMA_ADAS
 SG_ CamraFrntBttn_D_Stat3 : 8|1@0+ (1,0) [0|1] "SED"  IPMA_ADAS
 SG_ PrkAidSwtch_D_RqMnu : 11|1@0+ (1,0) [0|1] "SED"  IPMA_ADAS
 SG_ ApaSwtch_D_RqMnu : 10|2@0+ (1,0) [0|3] "SED"  IPMA_ADAS
 SG_ ApaMdeStat_D_RqDrv : 2|3@0+ (1,0) [0|7] "SED"  IPMA_ADAS
 SG_ CamraViewSplit_B_Rq : 3|1@0+ (1,0) [0|1] "SED"  GENERIC
 SG_ CamraZoomMan_D_Rq : 15|3@0+ (1,0) [0|7] "SED"  GENERIC
 SG_ CamraOvrlStat_D_Rq : 4|1@0+ (1,0) [0|1] "SED"  GENERIC
 SG_ CamraOvrlDyn_D_Rq : 7|1@0+ (1,0) [0|1] "SED"  GENERIC
 SG_ CamAutoTowbarZoom : 6|1@0+ (1,0) [0|1] "SED"  GENERIC
 SG_ DistanceBarSetting : 5|1@0+ (1,0) [0|1] "SED"  GENERIC

BO_ 2611145944 PARSEDPhyGWM_ECGtoCMR: 64 GWM
 SG_ PARSEDPhysGWM_ECGtoCMR : 7|29@0+ (1,0) [0|536870911] "unitless"  CMR_DSMC

BO_ 2611175611 PARSEDPhysCMRtoGWM_ECG: 64 CMR_DSMC
 SG_ PARSEDPhysCMRtoGWM_ECG : 7|29@0+ (1,0) [0|536870911] "unitless"  GWM

BO_ 1782 TesterPhysicalReqLDCMA: 64 TSTR
 SG_ TesterPhysicalReqLDCMA : 7|64@0+ (1,0) [0|1.84467E+019] "unitless"  HCM

BO_ 1791 TesterPhysicalResLDCMB: 64 HCM
 SG_ TesterPhysicalResLDCMB : 7|64@0+ (1,0) [0|1.84467E+019] "unitless"  TSTR

BO_ 1790 TesterPhysicalResLDCMA: 64 HCM
 SG_ TesterPhysicalResLDCMA : 7|64@0+ (1,0) [0|1.84467E+019] "unitless"  TSTR

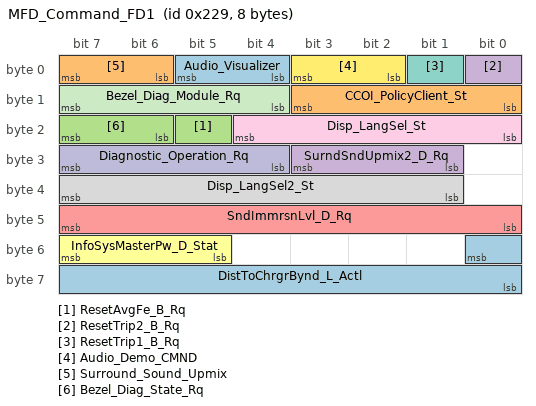
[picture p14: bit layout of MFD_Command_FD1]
BO_ 553 MFD_Command_FD1: 8 GWM
 SG_ DistToChrgrBynd_L_Actl : 48|9@0+ (1,0) [0|509] "kilometer"  SOBDMC_HPCM
 SG_ CCOI_PolicyClient_St : 11|4@0+ (1,0) [0|15] "SED"  GENERIC
 SG_ ResetAvgFe_B_Rq : 21|1@0+ (1,0) [0|1] "SED"  GENERIC
 SG_ ResetTrip2_B_Rq : 0|1@0+ (1,0) [0|1] "SED"  SOBDMC_HPCM,ECM_HEV,PCM
 SG_ SndImmrsnLvl_D_Rq : 47|8@0+ (1,0) [0|255] "SED"  GENERIC
 SG_ InfoSysMasterPw_D_Stat : 55|3@0+ (1,0) [0|7] "SED"  GENERIC
 SG_ ResetTrip1_B_Rq : 1|1@0+ (1,0) [0|1] "SED"  SOBDMC_HPCM,ECM_HEV,PCM
 SG_ Disp_LangSel2_St : 39|7@0+ (1,0) [0|127] "SED"  GENERIC
 SG_ Disp_LangSel_St : 20|5@0+ (1,0) [0|31] "SED"  GENERIC
 SG_ Diagnostic_Operation_Rq : 31|4@0+ (1,0) [0|15] "SED"  GENERIC
 SG_ Bezel_Diag_Module_Rq : 15|4@0+ (1,0) [0|15] "SED"  GENERIC
 SG_ Audio_Demo_CMND : 3|2@0+ (1,0) [0|3] "SED"  GENERIC
 SG_ Audio_Visualizer : 5|2@0+ (1,0) [0|3] "SED"  GENERIC
 SG_ Surround_Sound_Upmix : 7|2@0+ (1,0) [0|3] "SED"  GENERIC
 SG_ Bezel_Diag_State_Rq : 23|2@0+ (1,0) [0|3] "SED"  GENERIC
 SG_ SurndSndUpmix2_D_Rq : 27|3@0+ (1,0) [0|7] "SED"  GENERIC

BO_ 1998 TesterPhysicalResSODR: 64 IPMA_ADAS
 SG_ TesterPhysicalResSODR : 7|64@0+ (1,0) [0|1.84467E+019] "unitless"  TSTR

BO_ 1990 TesterPhysicalReqSODR: 64 TSTR
 SG_ TesterPhysicalReqSODR : 7|64@0+ (1,0) [0|1.84467E+019] "unitless"  IPMA_ADAS

BO_ 1996 TesterPhysicalResSODL: 64 IPMA_ADAS
 SG_ TesterPhysicalResSODL : 7|64@0+ (1,0) [0|1.84467E+019] "unitless"  TSTR

BO_ 1988 TesterPhysicalReqSODL: 64 TSTR
 SG_ TesterPhysicalReqSODL : 7|64@0+ (1,0) [0|1.84467E+019] "unitless"  IPMA_ADAS

BO_TX_BU_ 2611175440 : ECM_HEV,PCM;
BO_TX_BU_ 2610126864 : ECM_HEV,PCM;
BO_TX_BU_ 2612224016 : ECM_HEV,PCM;
CM_ SG_ 1088 HvacPrecondMode2_D_Rq "Signal not transmitted on vehicles that do not have the Fuel operated heater feature.";
CM_ SG_ 1088 HvacPrecondBlwr2_D_Rq "Signal not transmitted on vehicles that do not have the Fuel operated heater feature.";
CM_ SG_ 810 NtfyDrvTrgtDist_L_Rq "Object.SetTripRangeAlert_Rq
This signal is meant to provide the customer settings for the target distance remote notification";
CM_ SG_ 810 NtfyDrvSocLvl1_Pc_Rq "Object.SetCustomerLevelAlert_Rq
This signal is meant to provide the customer settings for the SOC remote notification.";
CM_ SG_ 810 PtRmtRprt_D_Stat "Object.RemoteDataReport_St
";
CM_ SG_ 563 NtfyDrvTrgtDist_L2_Rq "Object.SetTripRangeAlert_Rq
This signal is meant to provide the customer settings for the target distance remote notification";
CM_ BO_ 651 "TCU CPPM Tx";
CM_ SG_ 1150 LocationServices_1 "Tx by HS3 APIM";
CM_ SG_ 1445 SOBDMC_AutoSarNMReserved4 "Signal not transmitted on gas and diesel variants.";
CM_ SG_ 1445 SOBDMC_AutoSarNMReserved3 "Signal not transmitted on gas and diesel variants.";
CM_ SG_ 1445 SOBDMC_AutoSarNMReserved2 "Signal not transmitted on gas and diesel variants.";
CM_ SG_ 1445 SOBDMC_AutoSarNMReserved1 "Signal not transmitted on gas and diesel variants.";
CM_ SG_ 1445 SOBDMC_AutoSarNMNodeId "Signal not transmitted on gas and diesel variants.";
CM_ SG_ 1445 SOBDMC_AutoSarNMControl "Signal not transmitted on gas and diesel variants.";
CM_ BO_ 402 "FCDIM,APIM Tx";
CM_ BO_ 553 "FCDIM, APIM Tx";
CM_ SG_ 553 SndImmrsnLvl_D_Rq "ImmersionLevel_D_Rq";
CM_ SG_ 553 Disp_LangSel2_St "Reference GSDB for encoding: 009522/B;2-ZZ_LangSel";
CM_ SG_ 553 Disp_LangSel_St "Object.VehicleSettings.Disp_LangSel.St.Language";
CM_ SG_ 553 Diagnostic_Operation_Rq "Object:BezelDiagnostics.MFD_Bezel_Diagnostic.St";
CM_ SG_ 553 Bezel_Diag_Module_Rq "Object:BezelDiagnostics.MFD_Bezel_Diagnostic.St";
CM_ SG_ 553 Audio_Demo_CMND "Object. AudioSettings.Audio Demo_CMND";
CM_ SG_ 553 Audio_Visualizer "Object.AudioSettings.Audio_Visualizer
";
CM_ SG_ 553 Surround_Sound_Upmix "Object.AudioSettings.Surround_Sound_Upmix

";
CM_ SG_ 553 Bezel_Diag_State_Rq "Object:BezelDiagnostics.MFD_Bezel_Diagnostic.Rq";
CM_ SG_ 553 SurndSndUpmix2_D_Rq "Object:Surround_Sound_Upmix2_Rq";
BA_DEF_ SG_  "U_CDX706_MY2023_Tx" ENUM  "No","Yes";
BA_DEF_ SG_  "U_CDX706_MY2023_Rx" ENUM  "No","Yes";
BA_DEF_ BO_  "AuthFreshnessCounterSyncAttempt" INT 0 2;
BA_DEF_ BO_  "VFrameFormat" ENUM  "StandardCAN","ExtendedCAN","reserved","reserved","reserved","reserved","reserved","reserved","reserved","reserved","reserved","reserved","reserved","reserved","StandardCAN_FD","ExtendedCAN_FD";
BA_DEF_ SG_  "GenSigSendType" ENUM  "Cyclic","OnWrite","vector_leerstring","OnChange","vector_leerstring","IfActive","vector_leerstring","NoSigSendType";
BA_DEF_ SG_  "GenSigInactiveValue" INT 0 100000;
BA_DEF_ SG_  "WakeupSignal" ENUM  "No","Yes";
BA_DEF_ SG_  "UsedOnPgmDBC" ENUM  "No","Yes";
BA_DEF_ SG_  "GenSigStartValueInteger" INT 0 1000000000;
BA_DEF_ SG_  "ContentDependant" ENUM  "No","Yes";
BA_DEF_ SG_  "MetaData" ENUM  "No","Yes";
BA_DEF_ SG_  "GenSigStartValue" HEX 0 268435455;
BA_DEF_ SG_  "U_CX727_MY2021_Rx" ENUM  "No","Yes";
BA_DEF_ SG_  "U_P702_MY2021_Rx" ENUM  "No","Yes";
BA_DEF_ SG_  "U_T6_MCA_MY2020_Rx" ENUM  "No","Yes";
BA_DEF_ SG_  "ECGUsedRxSignal" ENUM  "No","Yes";
BA_DEF_ SG_  "U_CD542_MY2021_Rx" ENUM  "No","Yes";
BA_DEF_ SG_  "U_U55X_MY2022_Rx" ENUM  "No","Yes";
BA_DEF_ SG_  "U_CD764_MY2022_Rx" ENUM  "No","Yes";
BA_DEF_ SG_  "U_CX727_MY2021_Tx" ENUM  "No","Yes";
BA_DEF_ SG_  "U_P702_MY2021_Tx" ENUM  "No","Yes";
BA_DEF_ SG_  "U_T6_MCA_MY2020_Tx" ENUM  "No","Yes";
BA_DEF_ SG_  "ECGUsedTxSignal" ENUM  "No","Yes";
BA_DEF_ SG_  "U_CD542_MY2021_Tx" ENUM  "No","Yes";
BA_DEF_ SG_  "U_U55X_MY2022_Tx" ENUM  "No","Yes";
BA_DEF_ SG_  "U_CD764_MY2022_Tx" ENUM  "No","Yes";
BA_DEF_ BO_  "GenMsgILSupport" ENUM  "No","Yes";
BA_DEF_ BO_  "DiagResponse" ENUM  "No","Yes";
BA_DEF_ BO_  "DiagRequest" ENUM  "No","Yes";
BA_DEF_ BO_  "TpTxIndex" INT 0 536870911;
BA_DEF_ BO_  "DiagState" ENUM  "No","Yes";
BA_DEF_ BO_  "TpApplType" STRING ;
BA_DEF_ BO_  "NmAsrMessage" ENUM  "No","Yes";
BA_DEF_ BO_  "SCP_AuthInfoTxLength" INT 0 512;
BA_DEF_ BO_  "SCP_FreshnessValueTxLength" INT 0 512;
BA_DEF_ BO_  "SCP_FreshnessValueLength" INT 0 512;
BA_DEF_ BO_  "OvtpPushApplication" ENUM  "FALSE","TRUE";
BA_DEF_ BO_  "GenMsgSendType" ENUM  "FixedPeriodic","Event","EnabledPeriodic","NotUsed","NotUsed","EventPeriodic","NotUsed","NotUsed","NoMsgSendType";
BA_DEF_ BO_  "GenMsgCycleTime" INT 0 100000;
BA_DEF_ BO_  "GenMsgDelayTime" INT 0 1000;
BA_DEF_ BO_  "GenMsgNrOfRepetition" INT 0 100;
BA_DEF_ BO_  "GenMsgStartDelayTime" INT 0 10000;
BA_DEF_ BO_  "EventRateOfChange" INT 10 10000;
BA_DEF_ BO_  "FrameGatewayId" HEX 0 1407;
BA_DEF_ BO_  "NetworkInitialization" ENUM  "No","Yes";
BA_DEF_ BO_  "FrameGatewayNetwork" STRING ;
BA_DEF_ BO_  "FrameRouting" STRING ;
BA_DEF_DEF_  "U_CDX706_MY2023_Tx" "No";
BA_DEF_DEF_  "U_CDX706_MY2023_Rx" "No";
BA_DEF_DEF_  "AuthFreshnessCounterSyncAttempt" 2;
BA_DEF_DEF_  "VFrameFormat" "ExtendedCAN_FD";
BA_DEF_DEF_  "GenSigSendType" "NoSigSendType";
BA_DEF_DEF_  "GenSigInactiveValue" 0;
BA_DEF_DEF_  "WakeupSignal" "No";
BA_DEF_DEF_  "UsedOnPgmDBC" "Yes";
BA_DEF_DEF_  "GenSigStartValueInteger" 0;
BA_DEF_DEF_  "ContentDependant" "No";
BA_DEF_DEF_  "MetaData" "No";
BA_DEF_DEF_  "GenSigStartValue" 0;
BA_DEF_DEF_  "U_CX727_MY2021_Rx" "No";
BA_DEF_DEF_  "U_P702_MY2021_Rx" "No";
BA_DEF_DEF_  "U_T6_MCA_MY2020_Rx" "No";
BA_DEF_DEF_  "ECGUsedRxSignal" "No";
BA_DEF_DEF_  "U_CD542_MY2021_Rx" "No";
BA_DEF_DEF_  "U_U55X_MY2022_Rx" "No";
BA_DEF_DEF_  "U_CD764_MY2022_Rx" "No";
BA_DEF_DEF_  "U_CX727_MY2021_Tx" "No";
BA_DEF_DEF_  "U_P702_MY2021_Tx" "No";
BA_DEF_DEF_  "U_T6_MCA_MY2020_Tx" "No";
BA_DEF_DEF_  "ECGUsedTxSignal" "No";
BA_DEF_DEF_  "U_CD542_MY2021_Tx" "No";
BA_DEF_DEF_  "U_U55X_MY2022_Tx" "No";
BA_DEF_DEF_  "U_CD764_MY2022_Tx" "No";
BA_DEF_DEF_  "GenMsgILSupport" "Yes";
BA_DEF_DEF_  "DiagResponse" "No";
BA_DEF_DEF_  "DiagRequest" "No";
BA_DEF_DEF_  "TpTxIndex" 0;
BA_DEF_DEF_  "DiagState" "No";
BA_DEF_DEF_  "TpApplType" "";
BA_DEF_DEF_  "NmAsrMessage" "No";
BA_DEF_DEF_  "SCP_AuthInfoTxLength" 53;
BA_DEF_DEF_  "SCP_FreshnessValueTxLength" 11;
BA_DEF_DEF_  "SCP_FreshnessValueLength" 64;
BA_DEF_DEF_  "OvtpPushApplication" "FALSE";
BA_DEF_DEF_  "GenMsgSendType" "NoMsgSendType";
BA_DEF_DEF_  "GenMsgCycleTime" 0;
BA_DEF_DEF_  "GenMsgDelayTime" 20;
BA_DEF_DEF_  "GenMsgNrOfRepetition" 1;
BA_DEF_DEF_  "GenMsgStartDelayTime" 0;
BA_DEF_DEF_  "EventRateOfChange" 10000;
BA_DEF_DEF_  "FrameGatewayId" 0;
BA_DEF_DEF_  "NetworkInitialization" "Yes";
BA_DEF_DEF_  "FrameGatewayNetwork" "NONE";
BA_DEF_DEF_  "FrameRouting" "";
BA_ "GenMsgSendType" BO_ 1089 0;
BA_ "GenMsgCycleTime" BO_ 1089 1000;
BA_ "VFrameFormat" BO_ 1089 14;
BA_ "GenMsgILSupport" BO_ 1778 0;
BA_ "DiagRequest" BO_ 1778 1;
BA_ "GenMsgSendType" BO_ 1778 1;
BA_ "GenMsgDelayTime" BO_ 1778 0;
BA_ "NetworkInitialization" BO_ 1778 0;
BA_ "VFrameFormat" BO_ 1778 14;
BA_ "GenMsgSendType" BO_ 776 5;
BA_ "GenMsgCycleTime" BO_ 776 1000;
BA_ "VFrameFormat" BO_ 776 14;
BA_ "GenMsgSendType" BO_ 1088 0;
BA_ "GenMsgCycleTime" BO_ 1088 1000;
BA_ "VFrameFormat" BO_ 1088 14;
BA_ "GenMsgSendType" BO_ 850 0;
BA_ "GenMsgCycleTime" BO_ 850 150;
BA_ "VFrameFormat" BO_ 850 14;
BA_ "GenMsgILSupport" BO_ 1795 0;
BA_ "DiagRequest" BO_ 1795 1;
BA_ "GenMsgSendType" BO_ 1795 1;
BA_ "GenMsgDelayTime" BO_ 1795 0;
BA_ "NetworkInitialization" BO_ 1795 0;
BA_ "VFrameFormat" BO_ 1795 14;
BA_ "GenMsgILSupport" BO_ 1803 0;
BA_ "DiagResponse" BO_ 1803 1;
BA_ "GenMsgSendType" BO_ 1803 1;
BA_ "GenMsgDelayTime" BO_ 1803 0;
BA_ "NetworkInitialization" BO_ 1803 0;
BA_ "VFrameFormat" BO_ 1803 14;
BA_ "TpTxIndex" BO_ 2611026136 463542488;
BA_ "GenMsgSendType" BO_ 2611026136 1;
BA_ "GenMsgDelayTime" BO_ 2611026136 0;
BA_ "NetworkInitialization" BO_ 2611026136 0;
BA_ "TpTxIndex" BO_ 2611175494 463542488;
BA_ "GenMsgSendType" BO_ 2611175494 1;
BA_ "GenMsgDelayTime" BO_ 2611175494 0;
BA_ "NetworkInitialization" BO_ 2611175494 0;
BA_ "TpTxIndex" BO_ 2612224070 464591064;
BA_ "OvtpPushApplication" BO_ 2612224070 1;
BA_ "GenMsgSendType" BO_ 2612224070 1;
BA_ "GenMsgDelayTime" BO_ 2612224070 0;
BA_ "NetworkInitialization" BO_ 2612224070 0;
BA_ "TpTxIndex" BO_ 2611054808 463571160;
BA_ "GenMsgSendType" BO_ 2611054808 1;
BA_ "GenMsgDelayTime" BO_ 2611054808 0;
BA_ "NetworkInitialization" BO_ 2611054808 0;
BA_ "TpTxIndex" BO_ 2611175523 463572184;
BA_ "GenMsgSendType" BO_ 2611175523 1;
BA_ "GenMsgDelayTime" BO_ 2611175523 0;
BA_ "NetworkInitialization" BO_ 2611175523 0;
BA_ "TpTxIndex" BO_ 2612224099 464620760;
BA_ "OvtpPushApplication" BO_ 2612224099 1;
BA_ "GenMsgSendType" BO_ 2612224099 1;
BA_ "GenMsgDelayTime" BO_ 2612224099 0;
BA_ "NetworkInitialization" BO_ 2612224099 0;
BA_ "TpTxIndex" BO_ 2611055832 463572184;
BA_ "GenMsgSendType" BO_ 2611055832 1;
BA_ "GenMsgDelayTime" BO_ 2611055832 0;
BA_ "NetworkInitialization" BO_ 2611055832 0;
BA_ "TpTxIndex" BO_ 2611175522 463571160;
BA_ "GenMsgSendType" BO_ 2611175522 1;
BA_ "GenMsgDelayTime" BO_ 2611175522 0;
BA_ "NetworkInitialization" BO_ 2611175522 0;
BA_ "TpTxIndex" BO_ 2612224098 464619736;
BA_ "OvtpPushApplication" BO_ 2612224098 1;
BA_ "GenMsgSendType" BO_ 2612224098 1;
BA_ "GenMsgDelayTime" BO_ 2612224098 0;
BA_ "NetworkInitialization" BO_ 2612224098 0;
BA_ "TpTxIndex" BO_ 2609927384 462443736;
BA_ "GenMsgSendType" BO_ 2609927384 1;
BA_ "GenMsgDelayTime" BO_ 2609927384 0;
BA_ "NetworkInitialization" BO_ 2609927384 0;
BA_ "TpTxIndex" BO_ 2610126869 462443736;
BA_ "GenMsgSendType" BO_ 2610126869 1;
BA_ "GenMsgDelayTime" BO_ 2610126869 0;
BA_ "NetworkInitialization" BO_ 2610126869 0;
BA_ "TpTxIndex" BO_ 2609976536 462492888;
BA_ "GenMsgSendType" BO_ 2609976536 1;
BA_ "GenMsgDelayTime" BO_ 2609976536 0;
BA_ "NetworkInitialization" BO_ 2609976536 0;
BA_ "TpTxIndex" BO_ 2610126917 462492888;
BA_ "GenMsgSendType" BO_ 2610126917 1;
BA_ "GenMsgDelayTime" BO_ 2610126917 0;
BA_ "NetworkInitialization" BO_ 2610126917 0;
BA_ "TpTxIndex" BO_ 2609977560 462493912;
BA_ "GenMsgSendType" BO_ 2609977560 1;
BA_ "GenMsgDelayTime" BO_ 2609977560 0;
BA_ "NetworkInitialization" BO_ 2609977560 0;
BA_ "TpTxIndex" BO_ 2610126918 462493912;
BA_ "GenMsgSendType" BO_ 2610126918 1;
BA_ "GenMsgDelayTime" BO_ 2610126918 0;
BA_ "NetworkInitialization" BO_ 2610126918 0;
BA_ "TpTxIndex" BO_ 2610007256 462523608;
BA_ "GenMsgSendType" BO_ 2610007256 1;
BA_ "GenMsgDelayTime" BO_ 2610007256 0;
BA_ "NetworkInitialization" BO_ 2610007256 0;
BA_ "TpTxIndex" BO_ 2610126947 462523608;
BA_ "GenMsgSendType" BO_ 2610126947 1;
BA_ "GenMsgDelayTime" BO_ 2610126947 0;
BA_ "NetworkInitialization" BO_ 2610126947 0;
BA_ "TpTxIndex" BO_ 2612224017 464536792;
BA_ "OvtpPushApplication" BO_ 2612224017 1;
BA_ "GenMsgSendType" BO_ 2612224017 1;
BA_ "GenMsgDelayTime" BO_ 2612224017 0;
BA_ "NetworkInitialization" BO_ 2612224017 0;
BA_ "GenMsgSendType" BO_ 981 0;
BA_ "GenMsgCycleTime" BO_ 981 20;
BA_ "GenMsgDelayTime" BO_ 981 10;
BA_ "VFrameFormat" BO_ 981 14;
BA_ "GenMsgSendType" BO_ 810 5;
BA_ "GenMsgCycleTime" BO_ 810 1000;
BA_ "VFrameFormat" BO_ 810 14;
BA_ "GenMsgSendType" BO_ 563 5;
BA_ "GenMsgCycleTime" BO_ 563 1000;
BA_ "VFrameFormat" BO_ 563 14;
BA_ "TpTxIndex" BO_ 2609923288 462439640;
BA_ "GenMsgSendType" BO_ 2609923288 1;
BA_ "GenMsgDelayTime" BO_ 2609923288 0;
BA_ "NetworkInitialization" BO_ 2609923288 0;
BA_ "TpTxIndex" BO_ 2610126865 462439640;
BA_ "GenMsgSendType" BO_ 2610126865 1;
BA_ "GenMsgDelayTime" BO_ 2610126865 0;
BA_ "NetworkInitialization" BO_ 2610126865 0;
BA_ "TpTxIndex" BO_ 2610971864 463488216;
BA_ "GenMsgSendType" BO_ 2610971864 1;
BA_ "GenMsgDelayTime" BO_ 2610971864 0;
BA_ "NetworkInitialization" BO_ 2610971864 0;
BA_ "TpTxIndex" BO_ 2611175441 463488216;
BA_ "GenMsgSendType" BO_ 2611175441 1;
BA_ "GenMsgDelayTime" BO_ 2611175441 0;
BA_ "NetworkInitialization" BO_ 2611175441 0;
BA_ "TpTxIndex" BO_ 2610126946 462522584;
BA_ "GenMsgSendType" BO_ 2610126946 1;
BA_ "GenMsgDelayTime" BO_ 2610126946 0;
BA_ "NetworkInitialization" BO_ 2610126946 0;
BA_ "TpTxIndex" BO_ 2610006232 462522584;
BA_ "GenMsgSendType" BO_ 2610006232 1;
BA_ "GenMsgDelayTime" BO_ 2610006232 0;
BA_ "NetworkInitialization" BO_ 2610006232 0;
BA_ "GenMsgILSupport" BO_ 1993 0;
BA_ "DiagResponse" BO_ 1993 1;
BA_ "GenMsgSendType" BO_ 1993 1;
BA_ "GenMsgDelayTime" BO_ 1993 0;
BA_ "NetworkInitialization" BO_ 1993 0;
BA_ "VFrameFormat" BO_ 1993 14;
BA_ "GenMsgILSupport" BO_ 1985 0;
BA_ "DiagRequest" BO_ 1985 1;
BA_ "GenMsgSendType" BO_ 1985 1;
BA_ "GenMsgDelayTime" BO_ 1985 0;
BA_ "NetworkInitialization" BO_ 1985 0;
BA_ "VFrameFormat" BO_ 1985 14;
BA_ "GenMsgILSupport" BO_ 1503 0;
BA_ "NmAsrMessage" BO_ 1503 1;
BA_ "GenMsgSendType" BO_ 1503 0;
BA_ "GenMsgCycleTime" BO_ 1503 1000;
BA_ "NetworkInitialization" BO_ 1503 0;
BA_ "VFrameFormat" BO_ 1503 14;
BA_ "FrameGatewayId" BO_ 1119 1119;
BA_ "FrameGatewayNetwork" BO_ 1119 "HS1_CAN";
BA_ "FrameRouting" BO_ 1119 "HS1_CAN,0x45F;";
BA_ "VFrameFormat" BO_ 1119 14;
BA_ "GenMsgILSupport" BO_ 2022 0;
BA_ "DiagRequest" BO_ 2022 1;
BA_ "GenMsgSendType" BO_ 2022 1;
BA_ "GenMsgDelayTime" BO_ 2022 0;
BA_ "NetworkInitialization" BO_ 2022 0;
BA_ "VFrameFormat" BO_ 2022 14;
BA_ "FrameGatewayId" BO_ 912 912;
BA_ "FrameGatewayNetwork" BO_ 912 "HS1_CAN";
BA_ "FrameRouting" BO_ 912 "HS1_CAN,0x390;";
BA_ "VFrameFormat" BO_ 912 14;
BA_ "FrameGatewayId" BO_ 651 651;
BA_ "FrameGatewayNetwork" BO_ 651 "HS4_CAN";
BA_ "FrameRouting" BO_ 651 "HS4_CAN,0x28B;";
BA_ "VFrameFormat" BO_ 651 14;
BA_ "TpTxIndex" BO_ 2609955032 462471384;
BA_ "GenMsgSendType" BO_ 2609955032 1;
BA_ "GenMsgDelayTime" BO_ 2609955032 0;
BA_ "NetworkInitialization" BO_ 2609955032 0;
BA_ "TpTxIndex" BO_ 2610126896 462471384;
BA_ "GenMsgSendType" BO_ 2610126896 1;
BA_ "GenMsgDelayTime" BO_ 2610126896 0;
BA_ "NetworkInitialization" BO_ 2610126896 0;
BA_ "TpTxIndex" BO_ 2611003608 463519960;
BA_ "GenMsgSendType" BO_ 2611003608 1;
BA_ "GenMsgDelayTime" BO_ 2611003608 0;
BA_ "NetworkInitialization" BO_ 2611003608 0;
BA_ "TpTxIndex" BO_ 2612224048 464568536;
BA_ "OvtpPushApplication" BO_ 2612224048 1;
BA_ "GenMsgSendType" BO_ 2612224048 1;
BA_ "GenMsgDelayTime" BO_ 2612224048 0;
BA_ "NetworkInitialization" BO_ 2612224048 0;
BA_ "TpTxIndex" BO_ 2611175472 463519960;
BA_ "GenMsgSendType" BO_ 2611175472 1;
BA_ "GenMsgDelayTime" BO_ 2611175472 0;
BA_ "NetworkInitialization" BO_ 2611175472 0;
BA_ "FrameGatewayId" BO_ 1150 1118;
BA_ "FrameGatewayNetwork" BO_ 1150 "HS3_CAN";
BA_ "FrameRouting" BO_ 1150 "HS3_CAN,0x45E;";
BA_ "VFrameFormat" BO_ 1150 14;
BA_ "TpTxIndex" BO_ 2612224033 464553176;
BA_ "OvtpPushApplication" BO_ 2612224033 1;
BA_ "GenMsgSendType" BO_ 2612224033 1;
BA_ "GenMsgDelayTime" BO_ 2612224033 0;
BA_ "NetworkInitialization" BO_ 2612224033 0;
BA_ "TpTxIndex" BO_ 2609939672 462456024;
BA_ "GenMsgSendType" BO_ 2609939672 1;
BA_ "GenMsgDelayTime" BO_ 2609939672 0;
BA_ "NetworkInitialization" BO_ 2609939672 0;
BA_ "TpTxIndex" BO_ 2610126881 462456024;
BA_ "GenMsgSendType" BO_ 2610126881 1;
BA_ "GenMsgDelayTime" BO_ 2610126881 0;
BA_ "NetworkInitialization" BO_ 2610126881 0;
BA_ "TpTxIndex" BO_ 2612043992 464560344;
BA_ "OvtpPushApplication" BO_ 2612043992 1;
BA_ "GenMsgSendType" BO_ 2612043992 1;
BA_ "GenMsgDelayTime" BO_ 2612043992 0;
BA_ "NetworkInitialization" BO_ 2612043992 0;
BA_ "TpTxIndex" BO_ 2610995416 463511768;
BA_ "GenMsgSendType" BO_ 2610995416 1;
BA_ "GenMsgDelayTime" BO_ 2610995416 0;
BA_ "NetworkInitialization" BO_ 2610995416 0;
BA_ "TpTxIndex" BO_ 2612224040 464560344;
BA_ "OvtpPushApplication" BO_ 2612224040 1;
BA_ "GenMsgSendType" BO_ 2612224040 1;
BA_ "GenMsgDelayTime" BO_ 2612224040 0;
BA_ "NetworkInitialization" BO_ 2612224040 0;
BA_ "TpTxIndex" BO_ 2611175464 463511768;
BA_ "GenMsgSendType" BO_ 2611175464 1;
BA_ "GenMsgDelayTime" BO_ 2611175464 0;
BA_ "NetworkInitialization" BO_ 2611175464 0;
BA_ "FrameGatewayId" BO_ 529 529;
BA_ "FrameGatewayNetwork" BO_ 529 "HS3_CAN";
BA_ "FrameRouting" BO_ 529 "HS3_CAN,0x211;";
BA_ "VFrameFormat" BO_ 529 14;
BA_ "GenMsgILSupport" BO_ 1679 0;
BA_ "TpApplType" BO_ 1679 "DiagUUDTResponse";
BA_ "GenMsgSendType" BO_ 1679 1;
BA_ "NetworkInitialization" BO_ 1679 0;
BA_ "VFrameFormat" BO_ 1679 14;
BA_ "GenMsgILSupport" BO_ 1678 0;
BA_ "TpApplType" BO_ 1678 "DiagUUDTResponse";
BA_ "GenMsgSendType" BO_ 1678 1;
BA_ "NetworkInitialization" BO_ 1678 0;
BA_ "VFrameFormat" BO_ 1678 14;
BA_ "GenMsgILSupport" BO_ 1677 0;
BA_ "TpApplType" BO_ 1677 "DiagUUDTResponse";
BA_ "GenMsgSendType" BO_ 1677 1;
BA_ "NetworkInitialization" BO_ 1677 0;
BA_ "VFrameFormat" BO_ 1677 14;
BA_ "GenMsgILSupport" BO_ 1676 0;
BA_ "TpApplType" BO_ 1676 "DiagUUDTResponse";
BA_ "GenMsgSendType" BO_ 1676 1;
BA_ "NetworkInitialization" BO_ 1676 0;
BA_ "VFrameFormat" BO_ 1676 14;
BA_ "GenMsgILSupport" BO_ 1445 0;
BA_ "NmAsrMessage" BO_ 1445 1;
BA_ "GenMsgSendType" BO_ 1445 0;
BA_ "GenMsgCycleTime" BO_ 1445 1000;
BA_ "NetworkInitialization" BO_ 1445 0;
BA_ "VFrameFormat" BO_ 1445 14;
BA_ "GenMsgSendType" BO_ 1143 0;
BA_ "GenMsgCycleTime" BO_ 1143 500;
BA_ "VFrameFormat" BO_ 1143 14;
BA_ "GenMsgSendType" BO_ 1142 0;
BA_ "GenMsgCycleTime" BO_ 1142 500;
BA_ "VFrameFormat" BO_ 1142 14;
BA_ "GenMsgSendType" BO_ 1141 0;
BA_ "GenMsgCycleTime" BO_ 1141 100;
BA_ "VFrameFormat" BO_ 1141 14;
BA_ "GenMsgSendType" BO_ 1140 0;
BA_ "GenMsgCycleTime" BO_ 1140 1000;
BA_ "VFrameFormat" BO_ 1140 14;
BA_ "GenMsgSendType" BO_ 1139 0;
BA_ "GenMsgCycleTime" BO_ 1139 1500;
BA_ "VFrameFormat" BO_ 1139 14;
BA_ "GenMsgSendType" BO_ 1138 0;
BA_ "GenMsgCycleTime" BO_ 1138 1500;
BA_ "VFrameFormat" BO_ 1138 14;
BA_ "GenMsgSendType" BO_ 1016 5;
BA_ "GenMsgCycleTime" BO_ 1016 1000;
BA_ "VFrameFormat" BO_ 1016 14;
BA_ "GenMsgSendType" BO_ 1013 5;
BA_ "GenMsgCycleTime" BO_ 1013 1000;
BA_ "VFrameFormat" BO_ 1013 14;
BA_ "GenMsgSendType" BO_ 1012 5;
BA_ "GenMsgCycleTime" BO_ 1012 1000;
BA_ "VFrameFormat" BO_ 1012 14;
BA_ "GenMsgSendType" BO_ 1011 5;
BA_ "GenMsgCycleTime" BO_ 1011 1000;
BA_ "VFrameFormat" BO_ 1011 14;
BA_ "FrameGatewayId" BO_ 1049 1049;
BA_ "FrameGatewayNetwork" BO_ 1049 "HS3_CAN";
BA_ "FrameRouting" BO_ 1049 "HS3_CAN,0x419;";
BA_ "VFrameFormat" BO_ 1049 14;
BA_ "TpTxIndex" BO_ 2611175457 463504600;
BA_ "GenMsgSendType" BO_ 2611175457 1;
BA_ "GenMsgDelayTime" BO_ 2611175457 0;
BA_ "NetworkInitialization" BO_ 2611175457 0;
BA_ "TpTxIndex" BO_ 2609946840 462463192;
BA_ "GenMsgSendType" BO_ 2609946840 1;
BA_ "GenMsgDelayTime" BO_ 2609946840 0;
BA_ "NetworkInitialization" BO_ 2609946840 0;
BA_ "TpTxIndex" BO_ 2610126888 462463192;
BA_ "GenMsgSendType" BO_ 2610126888 1;
BA_ "GenMsgDelayTime" BO_ 2610126888 0;
BA_ "NetworkInitialization" BO_ 2610126888 0;
BA_ "TpTxIndex" BO_ 2611175440 463487192;
BA_ "GenMsgSendType" BO_ 2611175440 1;
BA_ "GenMsgDelayTime" BO_ 2611175440 0;
BA_ "NetworkInitialization" BO_ 2611175440 0;
BA_ "TpTxIndex" BO_ 2609922264 462438616;
BA_ "GenMsgSendType" BO_ 2609922264 1;
BA_ "GenMsgDelayTime" BO_ 2609922264 0;
BA_ "NetworkInitialization" BO_ 2609922264 0;
BA_ "TpTxIndex" BO_ 2610953432 463469784;
BA_ "GenMsgSendType" BO_ 2610953432 1;
BA_ "GenMsgDelayTime" BO_ 2610953432 0;
BA_ "NetworkInitialization" BO_ 2610953432 0;
BA_ "TpTxIndex" BO_ 2610126864 462438616;
BA_ "GenMsgSendType" BO_ 2610126864 1;
BA_ "GenMsgDelayTime" BO_ 2610126864 0;
BA_ "NetworkInitialization" BO_ 2610126864 0;
BA_ "TpTxIndex" BO_ 2612002008 464518360;
BA_ "GenMsgSendType" BO_ 2612002008 1;
BA_ "GenMsgDelayTime" BO_ 2612002008 0;
BA_ "NetworkInitialization" BO_ 2612002008 0;
BA_ "TpTxIndex" BO_ 2610970840 463487192;
BA_ "GenMsgSendType" BO_ 2610970840 1;
BA_ "GenMsgDelayTime" BO_ 2610970840 0;
BA_ "NetworkInitialization" BO_ 2610970840 0;
BA_ "TpTxIndex" BO_ 2612224016 464535768;
BA_ "OvtpPushApplication" BO_ 2612224016 1;
BA_ "GenMsgSendType" BO_ 2612224016 1;
BA_ "GenMsgDelayTime" BO_ 2612224016 0;
BA_ "NetworkInitialization" BO_ 2612224016 0;
BA_ "GenMsgSendType" BO_ 775 5;
BA_ "GenMsgCycleTime" BO_ 775 1000;
BA_ "VFrameFormat" BO_ 775 14;
BA_ "GenMsgSendType" BO_ 774 5;
BA_ "GenMsgCycleTime" BO_ 774 1000;
BA_ "VFrameFormat" BO_ 774 14;
BA_ "GenMsgSendType" BO_ 943 0;
BA_ "GenMsgCycleTime" BO_ 943 20;
BA_ "GenMsgDelayTime" BO_ 943 10;
BA_ "VFrameFormat" BO_ 943 14;
BA_ "GenMsgSendType" BO_ 930 5;
BA_ "GenMsgCycleTime" BO_ 930 1000;
BA_ "VFrameFormat" BO_ 930 14;
BA_ "GenMsgSendType" BO_ 929 5;
BA_ "GenMsgCycleTime" BO_ 929 1000;
BA_ "VFrameFormat" BO_ 929 14;
BA_ "GenMsgILSupport" BO_ 1783 0;
BA_ "DiagRequest" BO_ 1783 1;
BA_ "GenMsgSendType" BO_ 1783 1;
BA_ "GenMsgDelayTime" BO_ 1783 0;
BA_ "VFrameFormat" BO_ 1783 14;
BA_ "TpTxIndex" BO_ 2612194520 464710872;
BA_ "OvtpPushApplication" BO_ 2612194520 1;
BA_ "GenMsgSendType" BO_ 2612194520 1;
BA_ "GenMsgDelayTime" BO_ 2612194520 0;
BA_ "NetworkInitialization" BO_ 2612194520 0;
BA_ "TpTxIndex" BO_ 2610127035 462613720;
BA_ "GenMsgSendType" BO_ 2610127035 1;
BA_ "GenMsgDelayTime" BO_ 2610127035 0;
BA_ "NetworkInitialization" BO_ 2610127035 0;
BA_ "TpTxIndex" BO_ 2610097368 462613720;
BA_ "GenMsgSendType" BO_ 2610097368 1;
BA_ "GenMsgDelayTime" BO_ 2610097368 0;
BA_ "NetworkInitialization" BO_ 2610097368 0;
BA_ "FrameGatewayId" BO_ 402 402;
BA_ "FrameGatewayNetwork" BO_ 402 "HS3_CAN";
BA_ "FrameRouting" BO_ 402 "HS3_CAN,0x192;";
BA_ "VFrameFormat" BO_ 402 14;
BA_ "TpTxIndex" BO_ 2611145944 463662296;
BA_ "GenMsgSendType" BO_ 2611145944 1;
BA_ "GenMsgDelayTime" BO_ 2611145944 0;
BA_ "NetworkInitialization" BO_ 2611145944 0;
BA_ "TpTxIndex" BO_ 2611175611 463662296;
BA_ "GenMsgSendType" BO_ 2611175611 1;
BA_ "GenMsgDelayTime" BO_ 2611175611 0;
BA_ "NetworkInitialization" BO_ 2611175611 0;
BA_ "GenMsgILSupport" BO_ 1782 0;
BA_ "DiagRequest" BO_ 1782 1;
BA_ "GenMsgSendType" BO_ 1782 1;
BA_ "GenMsgDelayTime" BO_ 1782 0;
BA_ "VFrameFormat" BO_ 1782 14;
BA_ "GenMsgILSupport" BO_ 1791 0;
BA_ "DiagResponse" BO_ 1791 1;
BA_ "GenMsgSendType" BO_ 1791 1;
BA_ "GenMsgDelayTime" BO_ 1791 0;
BA_ "VFrameFormat" BO_ 1791 14;
BA_ "GenMsgILSupport" BO_ 1790 0;
BA_ "DiagResponse" BO_ 1790 1;
BA_ "GenMsgSendType" BO_ 1790 1;
BA_ "GenMsgDelayTime" BO_ 1790 0;
BA_ "VFrameFormat" BO_ 1790 14;
BA_ "FrameGatewayId" BO_ 553 553;
BA_ "FrameGatewayNetwork" BO_ 553 "HS3_CAN";
BA_ "FrameRouting" BO_ 553 "HS3_CAN,0x229;";
BA_ "VFrameFormat" BO_ 553 14;
BA_ "GenMsgILSupport" BO_ 1998 0;
BA_ "DiagResponse" BO_ 1998 1;
BA_ "GenMsgSendType" BO_ 1998 1;
BA_ "GenMsgDelayTime" BO_ 1998 0;
BA_ "NetworkInitialization" BO_ 1998 0;
BA_ "VFrameFormat" BO_ 1998 14;
BA_ "GenMsgILSupport" BO_ 1990 0;
BA_ "DiagRequest" BO_ 1990 1;
BA_ "GenMsgSendType" BO_ 1990 1;
BA_ "GenMsgDelayTime" BO_ 1990 0;
BA_ "NetworkInitialization" BO_ 1990 0;
BA_ "VFrameFormat" BO_ 1990 14;
BA_ "GenMsgILSupport" BO_ 1996 0;
BA_ "DiagResponse" BO_ 1996 1;
BA_ "GenMsgSendType" BO_ 1996 1;
BA_ "GenMsgDelayTime" BO_ 1996 0;
BA_ "NetworkInitialization" BO_ 1996 0;
BA_ "VFrameFormat" BO_ 1996 14;
BA_ "GenMsgILSupport" BO_ 1988 0;
BA_ "DiagRequest" BO_ 1988 1;
BA_ "GenMsgSendType" BO_ 1988 1;
BA_ "GenMsgDelayTime" BO_ 1988 0;
BA_ "NetworkInitialization" BO_ 1988 0;
BA_ "VFrameFormat" BO_ 1988 14;
BA_ "GenSigStartValueInteger" SG_ 1089 Mtr2Aout_W_ActlMntr 1023;
BA_ "GenSigStartValue" SG_ 1089 Mtr2Aout_W_ActlMntr 1023;
BA_ "ECGUsedRxSignal" SG_ 1089 Mtr2Aout_W_ActlMntr 1;
BA_ "U_CD542_MY2021_Rx" SG_ 1089 Mtr2Aout_W_ActlMntr 1;
BA_ "U_U55X_MY2022_Rx" SG_ 1089 Mtr2Aout_W_ActlMntr 1;
BA_ "U_CX727_MY2021_Tx" SG_ 1089 Mtr2Aout_W_ActlMntr 1;
BA_ "U_P702_MY2021_Tx" SG_ 1089 Mtr2Aout_W_ActlMntr 1;
BA_ "U_CD542_MY2021_Tx" SG_ 1089 Mtr2Aout_W_ActlMntr 1;
BA_ "GenSigStartValueInteger" SG_ 1089 Inv1_Te_Actl 254;
BA_ "GenSigStartValue" SG_ 1089 Inv1_Te_Actl 254;
BA_ "U_CX727_MY2021_Tx" SG_ 1089 Inv1_Te_Actl 1;
BA_ "U_P702_MY2021_Tx" SG_ 1089 Inv1_Te_Actl 1;
BA_ "U_CD542_MY2021_Tx" SG_ 1089 Inv1_Te_Actl 1;
BA_ "GenSigStartValueInteger" SG_ 1089 MtrTrac2Coil_Te_Actl 254;
BA_ "GenSigStartValue" SG_ 1089 MtrTrac2Coil_Te_Actl 254;
BA_ "ECGUsedRxSignal" SG_ 1089 MtrTrac2Coil_Te_Actl 1;
BA_ "U_CD542_MY2021_Rx" SG_ 1089 MtrTrac2Coil_Te_Actl 1;
BA_ "U_U55X_MY2022_Rx" SG_ 1089 MtrTrac2Coil_Te_Actl 1;
BA_ "U_CX727_MY2021_Tx" SG_ 1089 MtrTrac2Coil_Te_Actl 1;
BA_ "U_P702_MY2021_Tx" SG_ 1089 MtrTrac2Coil_Te_Actl 1;
BA_ "U_CD542_MY2021_Tx" SG_ 1089 MtrTrac2Coil_Te_Actl 1;
BA_ "GenSigStartValueInteger" SG_ 1089 MtrTrac2_U_Actl 1023;
BA_ "GenSigStartValue" SG_ 1089 MtrTrac2_U_Actl 1023;
BA_ "U_CX727_MY2021_Tx" SG_ 1089 MtrTrac2_U_Actl 1;
BA_ "U_P702_MY2021_Tx" SG_ 1089 MtrTrac2_U_Actl 1;
BA_ "U_CD542_MY2021_Tx" SG_ 1089 MtrTrac2_U_Actl 1;
BA_ "U_CX727_MY2021_Tx" SG_ 1089 MtrTrac2Falt_B_Stat 1;
BA_ "U_P702_MY2021_Tx" SG_ 1089 MtrTrac2Falt_B_Stat 1;
BA_ "U_CD542_MY2021_Tx" SG_ 1089 MtrTrac2Falt_B_Stat 1;
BA_ "ECGUsedRxSignal" SG_ 1089 MtrTrac2TeAlrm_B_Stat 1;
BA_ "U_CD542_MY2021_Rx" SG_ 1089 MtrTrac2TeAlrm_B_Stat 1;
BA_ "U_U55X_MY2022_Rx" SG_ 1089 MtrTrac2TeAlrm_B_Stat 1;
BA_ "U_CX727_MY2021_Tx" SG_ 1089 MtrTrac2TeAlrm_B_Stat 1;
BA_ "U_P702_MY2021_Tx" SG_ 1089 MtrTrac2TeAlrm_B_Stat 1;
BA_ "U_CD542_MY2021_Tx" SG_ 1089 MtrTrac2TeAlrm_B_Stat 1;
BA_ "ECGUsedRxSignal" SG_ 1089 Mtr2CntlTeAlrm_B_Stat 1;
BA_ "U_CD542_MY2021_Rx" SG_ 1089 Mtr2CntlTeAlrm_B_Stat 1;
BA_ "U_U55X_MY2022_Rx" SG_ 1089 Mtr2CntlTeAlrm_B_Stat 1;
BA_ "U_CX727_MY2021_Tx" SG_ 1089 Mtr2CntlTeAlrm_B_Stat 1;
BA_ "U_P702_MY2021_Tx" SG_ 1089 Mtr2CntlTeAlrm_B_Stat 1;
BA_ "U_CD542_MY2021_Tx" SG_ 1089 Mtr2CntlTeAlrm_B_Stat 1;
BA_ "GenSigStartValueInteger" SG_ 1089 MtrTrac2Inv_Te_Actl 214;
BA_ "GenSigStartValue" SG_ 1089 MtrTrac2Inv_Te_Actl 214;
BA_ "ECGUsedRxSignal" SG_ 1089 MtrTrac2Inv_Te_Actl 1;
BA_ "U_CD542_MY2021_Rx" SG_ 1089 MtrTrac2Inv_Te_Actl 1;
BA_ "U_U55X_MY2022_Rx" SG_ 1089 MtrTrac2Inv_Te_Actl 1;
BA_ "U_CX727_MY2021_Tx" SG_ 1089 MtrTrac2Inv_Te_Actl 1;
BA_ "U_P702_MY2021_Tx" SG_ 1089 MtrTrac2Inv_Te_Actl 1;
BA_ "U_CD542_MY2021_Tx" SG_ 1089 MtrTrac2Inv_Te_Actl 1;
BA_ "GenSigStartValueInteger" SG_ 1089 MtrTrac2_I_Actl 10000;
BA_ "U_CX727_MY2021_Tx" SG_ 1089 MtrTrac2_I_Actl 1;
BA_ "U_P702_MY2021_Tx" SG_ 1089 MtrTrac2_I_Actl 1;
BA_ "U_CD542_MY2021_Tx" SG_ 1089 MtrTrac2_I_Actl 1;
BA_ "GenSigSendType" SG_ 1778 TesterPhysicalReqSODCMC 3;
BA_ "U_T6_MCA_MY2020_Rx" SG_ 1778 TesterPhysicalReqSODCMC 1;
BA_ "U_CD542_MY2021_Rx" SG_ 1778 TesterPhysicalReqSODCMC 1;
BA_ "U_U55X_MY2022_Rx" SG_ 1778 TesterPhysicalReqSODCMC 1;
BA_ "U_CD764_MY2022_Rx" SG_ 1778 TesterPhysicalReqSODCMC 1;
BA_ "GenSigSendType" SG_ 776 ScMnSoc_Pc_RqCld 3;
BA_ "GenSigStartValue" SG_ 776 ScMnSoc_Pc_RqCld 100;
BA_ "ECGUsedTxSignal" SG_ 776 ScMnSoc_Pc_RqCld 1;
BA_ "U_CD542_MY2021_Tx" SG_ 776 ScMnSoc_Pc_RqCld 1;
BA_ "U_U55X_MY2022_Tx" SG_ 776 ScMnSoc_Pc_RqCld 1;
BA_ "ECGUsedTxSignal" SG_ 776 ScChrgrPwMax_Pw_RqCld 1;
BA_ "U_CD542_MY2021_Tx" SG_ 776 ScChrgrPwMax_Pw_RqCld 1;
BA_ "U_U55X_MY2022_Tx" SG_ 776 ScChrgrPwMax_Pw_RqCld 1;
BA_ "GenSigSendType" SG_ 776 ScLocPwId_No_RqCld 3;
BA_ "ECGUsedTxSignal" SG_ 776 ScLocPwId_No_RqCld 1;
BA_ "U_CD542_MY2021_Tx" SG_ 776 ScLocPwId_No_RqCld 1;
BA_ "U_U55X_MY2022_Tx" SG_ 776 ScLocPwId_No_RqCld 1;
BA_ "GenSigSendType" SG_ 776 PrcondEdit_D_RqCld 3;
BA_ "ECGUsedTxSignal" SG_ 776 PrcondEdit_D_RqCld 1;
BA_ "U_CD542_MY2021_Tx" SG_ 776 PrcondEdit_D_RqCld 1;
BA_ "U_U55X_MY2022_Tx" SG_ 776 PrcondEdit_D_RqCld 1;
BA_ "GenSigSendType" SG_ 776 GoTEditMnte_T_RqCld 3;
BA_ "GenSigStartValue" SG_ 776 GoTEditMnte_T_RqCld 14;
BA_ "ECGUsedTxSignal" SG_ 776 GoTEditMnte_T_RqCld 1;
BA_ "U_CD542_MY2021_Tx" SG_ 776 GoTEditMnte_T_RqCld 1;
BA_ "U_U55X_MY2022_Tx" SG_ 776 GoTEditMnte_T_RqCld 1;
BA_ "GenSigSendType" SG_ 776 GoTEditHr_T_RqCld 3;
BA_ "GenSigStartValue" SG_ 776 GoTEditHr_T_RqCld 30;
BA_ "ECGUsedTxSignal" SG_ 776 GoTEditHr_T_RqCld 1;
BA_ "U_CD542_MY2021_Tx" SG_ 776 GoTEditHr_T_RqCld 1;
BA_ "U_U55X_MY2022_Tx" SG_ 776 GoTEditHr_T_RqCld 1;
BA_ "GenSigSendType" SG_ 776 ChrgToPcEdit_Pc_RqCld 3;
BA_ "GenSigStartValue" SG_ 776 ChrgToPcEdit_Pc_RqCld 126;
BA_ "ECGUsedTxSignal" SG_ 776 ChrgToPcEdit_Pc_RqCld 1;
BA_ "U_CD542_MY2021_Tx" SG_ 776 ChrgToPcEdit_Pc_RqCld 1;
BA_ "U_U55X_MY2022_Tx" SG_ 776 ChrgToPcEdit_Pc_RqCld 1;
BA_ "GenSigSendType" SG_ 776 AirAmb_Te_ActlCld 3;
BA_ "GenSigStartValueInteger" SG_ 776 AirAmb_Te_ActlCld 512;
BA_ "ECGUsedTxSignal" SG_ 776 AirAmb_Te_ActlCld 1;
BA_ "U_CD542_MY2021_Tx" SG_ 776 AirAmb_Te_ActlCld 1;
BA_ "U_U55X_MY2022_Tx" SG_ 776 AirAmb_Te_ActlCld 1;
BA_ "GenSigSendType" SG_ 776 ScFreshDataEnbl_B_Rq 3;
BA_ "ECGUsedTxSignal" SG_ 776 ScFreshDataEnbl_B_Rq 1;
BA_ "U_CD542_MY2021_Tx" SG_ 776 ScFreshDataEnbl_B_Rq 1;
BA_ "U_U55X_MY2022_Tx" SG_ 776 ScFreshDataEnbl_B_Rq 1;
BA_ "GenSigSendType" SG_ 776 ScEnbl_D_RqCld 3;
BA_ "GenSigStartValue" SG_ 776 ScEnbl_D_RqCld 1;
BA_ "ECGUsedTxSignal" SG_ 776 ScEnbl_D_RqCld 1;
BA_ "U_CD542_MY2021_Tx" SG_ 776 ScEnbl_D_RqCld 1;
BA_ "U_U55X_MY2022_Tx" SG_ 776 ScEnbl_D_RqCld 1;
BA_ "GenSigStartValue" SG_ 1088 TrlrRng_L_Dsply 8190;
BA_ "GenSigStartValue" SG_ 1088 BattDcChrgRms_I_Lim 32766;
BA_ "WakeupSignal" SG_ 1088 ChrgStat_D2_Dsply 1;
BA_ "ECGUsedRxSignal" SG_ 1088 ChrgStat_D2_Dsply 1;
BA_ "U_CD542_MY2021_Rx" SG_ 1088 ChrgStat_D2_Dsply 1;
BA_ "U_U55X_MY2022_Rx" SG_ 1088 ChrgStat_D2_Dsply 1;
BA_ "U_CD764_MY2022_Rx" SG_ 1088 ChrgStat_D2_Dsply 1;
BA_ "U_CX727_MY2021_Tx" SG_ 1088 ChrgStat_D2_Dsply 1;
BA_ "U_P702_MY2021_Tx" SG_ 1088 ChrgStat_D2_Dsply 1;
BA_ "U_CD542_MY2021_Tx" SG_ 1088 ChrgStat_D2_Dsply 1;
BA_ "U_CX727_MY2021_Tx" SG_ 1088 ChrgTMatch_B_Stat 1;
BA_ "U_CD542_MY2021_Tx" SG_ 1088 ChrgTMatch_B_Stat 1;
BA_ "U_CX727_MY2021_Tx" SG_ 1088 HvacPrecondRecirc_D_Rq 1;
BA_ "U_P702_MY2021_Tx" SG_ 1088 HvacPrecondRecirc_D_Rq 1;
BA_ "U_CD542_MY2021_Tx" SG_ 1088 HvacPrecondRecirc_D_Rq 1;
BA_ "WakeupSignal" SG_ 1088 HvacPrecondMode2_D_Rq 1;
BA_ "ContentDependant" SG_ 1088 HvacPrecondMode2_D_Rq 1;
BA_ "U_CX727_MY2021_Tx" SG_ 1088 HvacPrecondMode2_D_Rq 1;
BA_ "U_P702_MY2021_Tx" SG_ 1088 HvacPrecondMode2_D_Rq 1;
BA_ "U_CD542_MY2021_Tx" SG_ 1088 HvacPrecondMode2_D_Rq 1;
BA_ "WakeupSignal" SG_ 1088 HvacPrecondBlwr2_D_Rq 1;
BA_ "ContentDependant" SG_ 1088 HvacPrecondBlwr2_D_Rq 1;
BA_ "U_CX727_MY2021_Tx" SG_ 1088 HvacPrecondBlwr2_D_Rq 1;
BA_ "U_P702_MY2021_Tx" SG_ 1088 HvacPrecondBlwr2_D_Rq 1;
BA_ "U_CD542_MY2021_Tx" SG_ 1088 HvacPrecondBlwr2_D_Rq 1;
BA_ "U_CX727_MY2021_Tx" SG_ 1088 HvacPrecondAC_D_Rq 1;
BA_ "U_P702_MY2021_Tx" SG_ 1088 HvacPrecondAC_D_Rq 1;
BA_ "U_CD542_MY2021_Tx" SG_ 1088 HvacPrecondAC_D_Rq 1;
BA_ "GenSigStartValueInteger" SG_ 1088 HvacPrecond_Te_Rq 2;
BA_ "GenSigStartValue" SG_ 1088 HvacPrecond_Te_Rq 2;
BA_ "U_CX727_MY2021_Tx" SG_ 1088 HvacPrecond_Te_Rq 1;
BA_ "U_P702_MY2021_Tx" SG_ 1088 HvacPrecond_Te_Rq 1;
BA_ "U_CD542_MY2021_Tx" SG_ 1088 HvacPrecond_Te_Rq 1;
BA_ "U_CX727_MY2021_Tx" SG_ 1088 BattChrgInhbt_D_Rq 1;
BA_ "U_P702_MY2021_Tx" SG_ 1088 BattChrgInhbt_D_Rq 1;
BA_ "U_CD542_MY2021_Tx" SG_ 1088 BattChrgInhbt_D_Rq 1;
BA_ "GenSigStartValue" SG_ 850 VehElRngeNut_L2_Dsply 8190;
BA_ "U_CX727_MY2021_Tx" SG_ 850 VehElRngeNut_L_Dsply 1;
BA_ "U_CD542_MY2021_Tx" SG_ 850 VehElRngeNut_L_Dsply 1;
BA_ "U_CX727_MY2021_Tx" SG_ 850 NxtUsgSocEst_Pc_Dsply 1;
BA_ "U_CD542_MY2021_Tx" SG_ 850 NxtUsgSocEst_Pc_Dsply 1;
BA_ "ECGUsedRxSignal" SG_ 850 EstmChrgTimeLP_St 1;
BA_ "U_CD542_MY2021_Rx" SG_ 850 EstmChrgTimeLP_St 1;
BA_ "U_U55X_MY2022_Rx" SG_ 850 EstmChrgTimeLP_St 1;
BA_ "U_CX727_MY2021_Tx" SG_ 850 EstmChrgTimeLP_St 1;
BA_ "U_CD542_MY2021_Tx" SG_ 850 EstmChrgTimeLP_St 1;
BA_ "ECGUsedRxSignal" SG_ 850 EstmChrgTimeHP_St 1;
BA_ "U_CD542_MY2021_Rx" SG_ 850 EstmChrgTimeHP_St 1;
BA_ "U_U55X_MY2022_Rx" SG_ 850 EstmChrgTimeHP_St 1;
BA_ "U_CX727_MY2021_Tx" SG_ 850 EstmChrgTimeHP_St 1;
BA_ "U_CD542_MY2021_Tx" SG_ 850 EstmChrgTimeHP_St 1;
BA_ "ECGUsedRxSignal" SG_ 850 ChargeNowDuration_St 1;
BA_ "U_CD542_MY2021_Rx" SG_ 850 ChargeNowDuration_St 1;
BA_ "U_U55X_MY2022_Rx" SG_ 850 ChargeNowDuration_St 1;
BA_ "U_CX727_MY2021_Tx" SG_ 850 ChargeNowDuration_St 1;
BA_ "U_CD542_MY2021_Tx" SG_ 850 ChargeNowDuration_St 1;
BA_ "GenSigSendType" SG_ 1795 TesterPhysicalReqAWD 3;
BA_ "U_T6_MCA_MY2020_Rx" SG_ 1795 TesterPhysicalReqAWD 1;
BA_ "GenSigSendType" SG_ 1803 TesterPhysicalResAWD 3;
BA_ "U_T6_MCA_MY2020_Tx" SG_ 1803 TesterPhysicalResAWD 1;
BA_ "GenSigSendType" SG_ 2611026136 PARSEDPhysGWM_ECGtoSODCMD 3;
BA_ "U_T6_MCA_MY2020_Rx" SG_ 2611026136 PARSEDPhysGWM_ECGtoSODCMD 1;
BA_ "U_CD542_MY2021_Rx" SG_ 2611026136 PARSEDPhysGWM_ECGtoSODCMD 1;
BA_ "U_U55X_MY2022_Rx" SG_ 2611026136 PARSEDPhysGWM_ECGtoSODCMD 1;
BA_ "U_CD764_MY2022_Rx" SG_ 2611026136 PARSEDPhysGWM_ECGtoSODCMD 1;
BA_ "U_T6_MCA_MY2020_Tx" SG_ 2611026136 PARSEDPhysGWM_ECGtoSODCMD 1;
BA_ "ECGUsedTxSignal" SG_ 2611026136 PARSEDPhysGWM_ECGtoSODCMD 1;
BA_ "U_CD542_MY2021_Tx" SG_ 2611026136 PARSEDPhysGWM_ECGtoSODCMD 1;
BA_ "U_U55X_MY2022_Tx" SG_ 2611026136 PARSEDPhysGWM_ECGtoSODCMD 1;
BA_ "GenSigSendType" SG_ 2611175494 PARSEDPhysSODCMDtoGWM_ECG 3;
BA_ "U_T6_MCA_MY2020_Rx" SG_ 2611175494 PARSEDPhysSODCMDtoGWM_ECG 1;
BA_ "ECGUsedRxSignal" SG_ 2611175494 PARSEDPhysSODCMDtoGWM_ECG 1;
BA_ "U_CD542_MY2021_Rx" SG_ 2611175494 PARSEDPhysSODCMDtoGWM_ECG 1;
BA_ "U_U55X_MY2022_Rx" SG_ 2611175494 PARSEDPhysSODCMDtoGWM_ECG 1;
BA_ "U_T6_MCA_MY2020_Tx" SG_ 2611175494 PARSEDPhysSODCMDtoGWM_ECG 1;
BA_ "U_CD542_MY2021_Tx" SG_ 2611175494 PARSEDPhysSODCMDtoGWM_ECG 1;
BA_ "U_U55X_MY2022_Tx" SG_ 2611175494 PARSEDPhysSODCMDtoGWM_ECG 1;
BA_ "U_CD764_MY2022_Tx" SG_ 2611175494 PARSEDPhysSODCMDtoGWM_ECG 1;
BA_ "GenSigSendType" SG_ 2612224070 PARSEDPushSODCMDtoGWM 3;
BA_ "U_T6_MCA_MY2020_Rx" SG_ 2612224070 PARSEDPushSODCMDtoGWM 1;
BA_ "ECGUsedRxSignal" SG_ 2612224070 PARSEDPushSODCMDtoGWM 1;
BA_ "U_CD542_MY2021_Rx" SG_ 2612224070 PARSEDPushSODCMDtoGWM 1;
BA_ "U_U55X_MY2022_Rx" SG_ 2612224070 PARSEDPushSODCMDtoGWM 1;
BA_ "U_T6_MCA_MY2020_Tx" SG_ 2612224070 PARSEDPushSODCMDtoGWM 1;
BA_ "U_CD542_MY2021_Tx" SG_ 2612224070 PARSEDPushSODCMDtoGWM 1;
BA_ "U_U55X_MY2022_Tx" SG_ 2612224070 PARSEDPushSODCMDtoGWM 1;
BA_ "U_CD764_MY2022_Tx" SG_ 2612224070 PARSEDPushSODCMDtoGWM 1;
BA_ "GenSigSendType" SG_ 2611054808 PARSEDPhysGWM_ECGtoSODL 3;
BA_ "U_T6_MCA_MY2020_Rx" SG_ 2611054808 PARSEDPhysGWM_ECGtoSODL 1;
BA_ "U_CD542_MY2021_Rx" SG_ 2611054808 PARSEDPhysGWM_ECGtoSODL 1;
BA_ "U_U55X_MY2022_Rx" SG_ 2611054808 PARSEDPhysGWM_ECGtoSODL 1;
BA_ "U_CD764_MY2022_Rx" SG_ 2611054808 PARSEDPhysGWM_ECGtoSODL 1;
BA_ "U_T6_MCA_MY2020_Tx" SG_ 2611054808 PARSEDPhysGWM_ECGtoSODL 1;
BA_ "ECGUsedTxSignal" SG_ 2611054808 PARSEDPhysGWM_ECGtoSODL 1;
BA_ "U_CD542_MY2021_Tx" SG_ 2611054808 PARSEDPhysGWM_ECGtoSODL 1;
BA_ "U_U55X_MY2022_Tx" SG_ 2611054808 PARSEDPhysGWM_ECGtoSODL 1;
BA_ "GenSigSendType" SG_ 2611175523 PARSEDPhysSODRtoGWM_ECG 3;
BA_ "U_T6_MCA_MY2020_Rx" SG_ 2611175523 PARSEDPhysSODRtoGWM_ECG 1;
BA_ "ECGUsedRxSignal" SG_ 2611175523 PARSEDPhysSODRtoGWM_ECG 1;
BA_ "U_CD542_MY2021_Rx" SG_ 2611175523 PARSEDPhysSODRtoGWM_ECG 1;
BA_ "U_U55X_MY2022_Rx" SG_ 2611175523 PARSEDPhysSODRtoGWM_ECG 1;
BA_ "U_T6_MCA_MY2020_Tx" SG_ 2611175523 PARSEDPhysSODRtoGWM_ECG 1;
BA_ "U_CD542_MY2021_Tx" SG_ 2611175523 PARSEDPhysSODRtoGWM_ECG 1;
BA_ "U_U55X_MY2022_Tx" SG_ 2611175523 PARSEDPhysSODRtoGWM_ECG 1;
BA_ "U_CD764_MY2022_Tx" SG_ 2611175523 PARSEDPhysSODRtoGWM_ECG 1;
BA_ "GenSigSendType" SG_ 2612224099 PARSEDPushSODRtoGWM_ECG 3;
BA_ "U_T6_MCA_MY2020_Rx" SG_ 2612224099 PARSEDPushSODRtoGWM_ECG 1;
BA_ "ECGUsedRxSignal" SG_ 2612224099 PARSEDPushSODRtoGWM_ECG 1;
BA_ "U_CD542_MY2021_Rx" SG_ 2612224099 PARSEDPushSODRtoGWM_ECG 1;
BA_ "U_U55X_MY2022_Rx" SG_ 2612224099 PARSEDPushSODRtoGWM_ECG 1;
BA_ "U_T6_MCA_MY2020_Tx" SG_ 2612224099 PARSEDPushSODRtoGWM_ECG 1;
BA_ "U_CD542_MY2021_Tx" SG_ 2612224099 PARSEDPushSODRtoGWM_ECG 1;
BA_ "U_U55X_MY2022_Tx" SG_ 2612224099 PARSEDPushSODRtoGWM_ECG 1;
BA_ "U_CD764_MY2022_Tx" SG_ 2612224099 PARSEDPushSODRtoGWM_ECG 1;
BA_ "GenSigSendType" SG_ 2611055832 PARSEDPhysGWM_ECGtoSODR 3;
BA_ "U_T6_MCA_MY2020_Rx" SG_ 2611055832 PARSEDPhysGWM_ECGtoSODR 1;
BA_ "U_CD542_MY2021_Rx" SG_ 2611055832 PARSEDPhysGWM_ECGtoSODR 1;
BA_ "U_U55X_MY2022_Rx" SG_ 2611055832 PARSEDPhysGWM_ECGtoSODR 1;
BA_ "U_CD764_MY2022_Rx" SG_ 2611055832 PARSEDPhysGWM_ECGtoSODR 1;
BA_ "U_T6_MCA_MY2020_Tx" SG_ 2611055832 PARSEDPhysGWM_ECGtoSODR 1;
BA_ "ECGUsedTxSignal" SG_ 2611055832 PARSEDPhysGWM_ECGtoSODR 1;
BA_ "U_CD542_MY2021_Tx" SG_ 2611055832 PARSEDPhysGWM_ECGtoSODR 1;
BA_ "U_U55X_MY2022_Tx" SG_ 2611055832 PARSEDPhysGWM_ECGtoSODR 1;
BA_ "GenSigSendType" SG_ 2611175522 PARSEDPhysSODLtoGWM_ECG 3;
BA_ "U_T6_MCA_MY2020_Rx" SG_ 2611175522 PARSEDPhysSODLtoGWM_ECG 1;
BA_ "ECGUsedRxSignal" SG_ 2611175522 PARSEDPhysSODLtoGWM_ECG 1;
BA_ "U_CD542_MY2021_Rx" SG_ 2611175522 PARSEDPhysSODLtoGWM_ECG 1;
BA_ "U_U55X_MY2022_Rx" SG_ 2611175522 PARSEDPhysSODLtoGWM_ECG 1;
BA_ "U_T6_MCA_MY2020_Tx" SG_ 2611175522 PARSEDPhysSODLtoGWM_ECG 1;
BA_ "U_CD542_MY2021_Tx" SG_ 2611175522 PARSEDPhysSODLtoGWM_ECG 1;
BA_ "U_U55X_MY2022_Tx" SG_ 2611175522 PARSEDPhysSODLtoGWM_ECG 1;
BA_ "U_CD764_MY2022_Tx" SG_ 2611175522 PARSEDPhysSODLtoGWM_ECG 1;
BA_ "GenSigSendType" SG_ 2612224098 PARSEDPushSODLtoGWM_ECG 3;
BA_ "U_T6_MCA_MY2020_Rx" SG_ 2612224098 PARSEDPushSODLtoGWM_ECG 1;
BA_ "ECGUsedRxSignal" SG_ 2612224098 PARSEDPushSODLtoGWM_ECG 1;
BA_ "U_CD542_MY2021_Rx" SG_ 2612224098 PARSEDPushSODLtoGWM_ECG 1;
BA_ "U_U55X_MY2022_Rx" SG_ 2612224098 PARSEDPushSODLtoGWM_ECG 1;
BA_ "U_T6_MCA_MY2020_Tx" SG_ 2612224098 PARSEDPushSODLtoGWM_ECG 1;
BA_ "U_CD542_MY2021_Tx" SG_ 2612224098 PARSEDPushSODLtoGWM_ECG 1;
BA_ "U_U55X_MY2022_Tx" SG_ 2612224098 PARSEDPushSODLtoGWM_ECG 1;
BA_ "U_CD764_MY2022_Tx" SG_ 2612224098 PARSEDPushSODLtoGWM_ECG 1;
BA_ "GenSigSendType" SG_ 2609927384 OTAPhysGWM_ECGtoCCM 3;
BA_ "U_T6_MCA_MY2020_Rx" SG_ 2609927384 OTAPhysGWM_ECGtoCCM 1;
BA_ "U_CD542_MY2021_Rx" SG_ 2609927384 OTAPhysGWM_ECGtoCCM 1;
BA_ "U_U55X_MY2022_Rx" SG_ 2609927384 OTAPhysGWM_ECGtoCCM 1;
BA_ "U_CD764_MY2022_Rx" SG_ 2609927384 OTAPhysGWM_ECGtoCCM 1;
BA_ "U_T6_MCA_MY2020_Tx" SG_ 2609927384 OTAPhysGWM_ECGtoCCM 1;
BA_ "ECGUsedTxSignal" SG_ 2609927384 OTAPhysGWM_ECGtoCCM 1;
BA_ "U_CD542_MY2021_Tx" SG_ 2609927384 OTAPhysGWM_ECGtoCCM 1;
BA_ "U_U55X_MY2022_Tx" SG_ 2609927384 OTAPhysGWM_ECGtoCCM 1;
BA_ "GenSigSendType" SG_ 2610126869 OTAPhysCCMtoGWM_ECG 3;
BA_ "U_T6_MCA_MY2020_Rx" SG_ 2610126869 OTAPhysCCMtoGWM_ECG 1;
BA_ "ECGUsedRxSignal" SG_ 2610126869 OTAPhysCCMtoGWM_ECG 1;
BA_ "U_CD542_MY2021_Rx" SG_ 2610126869 OTAPhysCCMtoGWM_ECG 1;
BA_ "U_U55X_MY2022_Rx" SG_ 2610126869 OTAPhysCCMtoGWM_ECG 1;
BA_ "U_T6_MCA_MY2020_Tx" SG_ 2610126869 OTAPhysCCMtoGWM_ECG 1;
BA_ "U_CD542_MY2021_Tx" SG_ 2610126869 OTAPhysCCMtoGWM_ECG 1;
BA_ "U_U55X_MY2022_Tx" SG_ 2610126869 OTAPhysCCMtoGWM_ECG 1;
BA_ "U_CD764_MY2022_Tx" SG_ 2610126869 OTAPhysCCMtoGWM_ECG 1;
BA_ "GenSigSendType" SG_ 2609976536 OTAPhysGWM_ECGtoSODCMC 3;
BA_ "U_T6_MCA_MY2020_Rx" SG_ 2609976536 OTAPhysGWM_ECGtoSODCMC 1;
BA_ "U_CD542_MY2021_Rx" SG_ 2609976536 OTAPhysGWM_ECGtoSODCMC 1;
BA_ "U_U55X_MY2022_Rx" SG_ 2609976536 OTAPhysGWM_ECGtoSODCMC 1;
BA_ "U_CD764_MY2022_Rx" SG_ 2609976536 OTAPhysGWM_ECGtoSODCMC 1;
BA_ "U_T6_MCA_MY2020_Tx" SG_ 2609976536 OTAPhysGWM_ECGtoSODCMC 1;
BA_ "ECGUsedTxSignal" SG_ 2609976536 OTAPhysGWM_ECGtoSODCMC 1;
BA_ "U_CD542_MY2021_Tx" SG_ 2609976536 OTAPhysGWM_ECGtoSODCMC 1;
BA_ "U_U55X_MY2022_Tx" SG_ 2609976536 OTAPhysGWM_ECGtoSODCMC 1;
BA_ "GenSigSendType" SG_ 2610126917 OTAPhysSODCMCtoGWM_ECG 3;
BA_ "U_T6_MCA_MY2020_Rx" SG_ 2610126917 OTAPhysSODCMCtoGWM_ECG 1;
BA_ "ECGUsedRxSignal" SG_ 2610126917 OTAPhysSODCMCtoGWM_ECG 1;
BA_ "U_CD542_MY2021_Rx" SG_ 2610126917 OTAPhysSODCMCtoGWM_ECG 1;
BA_ "U_U55X_MY2022_Rx" SG_ 2610126917 OTAPhysSODCMCtoGWM_ECG 1;
BA_ "U_T6_MCA_MY2020_Tx" SG_ 2610126917 OTAPhysSODCMCtoGWM_ECG 1;
BA_ "U_CD542_MY2021_Tx" SG_ 2610126917 OTAPhysSODCMCtoGWM_ECG 1;
BA_ "U_U55X_MY2022_Tx" SG_ 2610126917 OTAPhysSODCMCtoGWM_ECG 1;
BA_ "U_CD764_MY2022_Tx" SG_ 2610126917 OTAPhysSODCMCtoGWM_ECG 1;
BA_ "GenSigSendType" SG_ 2609977560 OTAPhysGWM_ECGtoSODCMD 3;
BA_ "U_T6_MCA_MY2020_Rx" SG_ 2609977560 OTAPhysGWM_ECGtoSODCMD 1;
BA_ "U_CD542_MY2021_Rx" SG_ 2609977560 OTAPhysGWM_ECGtoSODCMD 1;
BA_ "U_U55X_MY2022_Rx" SG_ 2609977560 OTAPhysGWM_ECGtoSODCMD 1;
BA_ "U_CD764_MY2022_Rx" SG_ 2609977560 OTAPhysGWM_ECGtoSODCMD 1;
BA_ "U_T6_MCA_MY2020_Tx" SG_ 2609977560 OTAPhysGWM_ECGtoSODCMD 1;
BA_ "ECGUsedTxSignal" SG_ 2609977560 OTAPhysGWM_ECGtoSODCMD 1;
BA_ "U_CD542_MY2021_Tx" SG_ 2609977560 OTAPhysGWM_ECGtoSODCMD 1;
BA_ "U_U55X_MY2022_Tx" SG_ 2609977560 OTAPhysGWM_ECGtoSODCMD 1;
BA_ "GenSigSendType" SG_ 2610126918 OTAPhysSODCMDtoGWM_ECG 3;
BA_ "U_T6_MCA_MY2020_Rx" SG_ 2610126918 OTAPhysSODCMDtoGWM_ECG 1;
BA_ "ECGUsedRxSignal" SG_ 2610126918 OTAPhysSODCMDtoGWM_ECG 1;
BA_ "U_CD542_MY2021_Rx" SG_ 2610126918 OTAPhysSODCMDtoGWM_ECG 1;
BA_ "U_U55X_MY2022_Rx" SG_ 2610126918 OTAPhysSODCMDtoGWM_ECG 1;
BA_ "U_T6_MCA_MY2020_Tx" SG_ 2610126918 OTAPhysSODCMDtoGWM_ECG 1;
BA_ "U_CD542_MY2021_Tx" SG_ 2610126918 OTAPhysSODCMDtoGWM_ECG 1;
BA_ "U_U55X_MY2022_Tx" SG_ 2610126918 OTAPhysSODCMDtoGWM_ECG 1;
BA_ "U_CD764_MY2022_Tx" SG_ 2610126918 OTAPhysSODCMDtoGWM_ECG 1;
BA_ "GenSigSendType" SG_ 2610007256 OTAPhysGWM_ECGtoSODR 3;
BA_ "U_T6_MCA_MY2020_Rx" SG_ 2610007256 OTAPhysGWM_ECGtoSODR 1;
BA_ "U_CD542_MY2021_Rx" SG_ 2610007256 OTAPhysGWM_ECGtoSODR 1;
BA_ "U_U55X_MY2022_Rx" SG_ 2610007256 OTAPhysGWM_ECGtoSODR 1;
BA_ "U_CD764_MY2022_Rx" SG_ 2610007256 OTAPhysGWM_ECGtoSODR 1;
BA_ "U_T6_MCA_MY2020_Tx" SG_ 2610007256 OTAPhysGWM_ECGtoSODR 1;
BA_ "ECGUsedTxSignal" SG_ 2610007256 OTAPhysGWM_ECGtoSODR 1;
BA_ "U_CD542_MY2021_Tx" SG_ 2610007256 OTAPhysGWM_ECGtoSODR 1;
BA_ "U_U55X_MY2022_Tx" SG_ 2610007256 OTAPhysGWM_ECGtoSODR 1;
BA_ "GenSigSendType" SG_ 2610126947 OTAPhysSODRtoGWM_ECG 3;
BA_ "U_T6_MCA_MY2020_Rx" SG_ 2610126947 OTAPhysSODRtoGWM_ECG 1;
BA_ "ECGUsedRxSignal" SG_ 2610126947 OTAPhysSODRtoGWM_ECG 1;
BA_ "U_CD542_MY2021_Rx" SG_ 2610126947 OTAPhysSODRtoGWM_ECG 1;
BA_ "U_U55X_MY2022_Rx" SG_ 2610126947 OTAPhysSODRtoGWM_ECG 1;
BA_ "U_T6_MCA_MY2020_Tx" SG_ 2610126947 OTAPhysSODRtoGWM_ECG 1;
BA_ "U_CD542_MY2021_Tx" SG_ 2610126947 OTAPhysSODRtoGWM_ECG 1;
BA_ "U_U55X_MY2022_Tx" SG_ 2610126947 OTAPhysSODRtoGWM_ECG 1;
BA_ "U_CD764_MY2022_Tx" SG_ 2610126947 OTAPhysSODRtoGWM_ECG 1;
BA_ "GenSigSendType" SG_ 2612224017 PARSEDPushSOBDMCtoGWM_ECG 3;
BA_ "ECGUsedRxSignal" SG_ 2612224017 PARSEDPushSOBDMCtoGWM_ECG 1;
BA_ "U_CD542_MY2021_Rx" SG_ 2612224017 PARSEDPushSOBDMCtoGWM_ECG 1;
BA_ "U_U55X_MY2022_Rx" SG_ 2612224017 PARSEDPushSOBDMCtoGWM_ECG 1;
BA_ "U_T6_MCA_MY2020_Tx" SG_ 981 AdbRamping_T_Rq 1;
BA_ "U_CD542_MY2021_Tx" SG_ 981 AdbRamping_T_Rq 1;
BA_ "U_U55X_MY2022_Tx" SG_ 981 AdbRamping_T_Rq 1;
BA_ "U_CD764_MY2022_Tx" SG_ 981 AdbRamping_T_Rq 1;
BA_ "GenSigStartValue" SG_ 981 AdbBrdrTop_An_Rq 254;
BA_ "U_T6_MCA_MY2020_Tx" SG_ 981 AdbBrdrTop_An_Rq 1;
BA_ "U_CD542_MY2021_Tx" SG_ 981 AdbBrdrTop_An_Rq 1;
BA_ "U_U55X_MY2022_Tx" SG_ 981 AdbBrdrTop_An_Rq 1;
BA_ "U_CD764_MY2022_Tx" SG_ 981 AdbBrdrTop_An_Rq 1;
BA_ "GenSigStartValue" SG_ 981 AdbBrdrRight_L_Stat 510;
BA_ "U_T6_MCA_MY2020_Tx" SG_ 981 AdbBrdrRight_L_Stat 1;
BA_ "U_CD542_MY2021_Tx" SG_ 981 AdbBrdrRight_L_Stat 1;
BA_ "U_U55X_MY2022_Tx" SG_ 981 AdbBrdrRight_L_Stat 1;
BA_ "U_CD764_MY2022_Tx" SG_ 981 AdbBrdrRight_L_Stat 1;
BA_ "GenSigStartValue" SG_ 981 AdbBrdrRight_An_Rq 1022;
BA_ "U_T6_MCA_MY2020_Tx" SG_ 981 AdbBrdrRight_An_Rq 1;
BA_ "U_CD542_MY2021_Tx" SG_ 981 AdbBrdrRight_An_Rq 1;
BA_ "U_U55X_MY2022_Tx" SG_ 981 AdbBrdrRight_An_Rq 1;
BA_ "U_CD764_MY2022_Tx" SG_ 981 AdbBrdrRight_An_Rq 1;
BA_ "GenSigStartValue" SG_ 981 AdbBrdrLeft_L_Stat 510;
BA_ "U_T6_MCA_MY2020_Tx" SG_ 981 AdbBrdrLeft_L_Stat 1;
BA_ "U_CD542_MY2021_Tx" SG_ 981 AdbBrdrLeft_L_Stat 1;
BA_ "U_U55X_MY2022_Tx" SG_ 981 AdbBrdrLeft_L_Stat 1;
BA_ "U_CD764_MY2022_Tx" SG_ 981 AdbBrdrLeft_L_Stat 1;
BA_ "GenSigStartValue" SG_ 981 AdbBrdrLeft_An_Rq 1022;
BA_ "U_T6_MCA_MY2020_Tx" SG_ 981 AdbBrdrLeft_An_Rq 1;
BA_ "U_CD542_MY2021_Tx" SG_ 981 AdbBrdrLeft_An_Rq 1;
BA_ "U_U55X_MY2022_Tx" SG_ 981 AdbBrdrLeft_An_Rq 1;
BA_ "U_CD764_MY2022_Tx" SG_ 981 AdbBrdrLeft_An_Rq 1;
BA_ "GenSigStartValue" SG_ 981 AdbBrdrBottom_An_Rq 62;
BA_ "U_T6_MCA_MY2020_Tx" SG_ 981 AdbBrdrBottom_An_Rq 1;
BA_ "U_CD542_MY2021_Tx" SG_ 981 AdbBrdrBottom_An_Rq 1;
BA_ "U_U55X_MY2022_Tx" SG_ 981 AdbBrdrBottom_An_Rq 1;
BA_ "U_CD764_MY2022_Tx" SG_ 981 AdbBrdrBottom_An_Rq 1;
BA_ "U_T6_MCA_MY2020_Tx" SG_ 981 AdbBeam_D_Rq 1;
BA_ "U_CD542_MY2021_Tx" SG_ 981 AdbBeam_D_Rq 1;
BA_ "U_U55X_MY2022_Tx" SG_ 981 AdbBeam_D_Rq 1;
BA_ "U_CD764_MY2022_Tx" SG_ 981 AdbBeam_D_Rq 1;
BA_ "GenSigSendType" SG_ 810 VehHorn_B_RqOccAlrt 3;
BA_ "WakeupSignal" SG_ 810 VehHorn_B_RqOccAlrt 1;
BA_ "ECGUsedTxSignal" SG_ 810 VehHorn_B_RqOccAlrt 1;
BA_ "GenSigSendType" SG_ 810 RmtViewMde_B_Rq 3;
BA_ "ECGUsedTxSignal" SG_ 810 RmtViewMde_B_Rq 1;
BA_ "U_CD542_MY2021_Tx" SG_ 810 RmtViewMde_B_Rq 1;
BA_ "GenSigSendType" SG_ 810 DteCldAcceptData_B_Rq 3;
BA_ "ECGUsedTxSignal" SG_ 810 DteCldAcceptData_B_Rq 1;
BA_ "U_CD542_MY2021_Tx" SG_ 810 DteCldAcceptData_B_Rq 1;
BA_ "U_CD764_MY2022_Tx" SG_ 810 DteCldAcceptData_B_Rq 1;
BA_ "GenSigSendType" SG_ 810 DteCldCnclRoute_B_Rq 3;
BA_ "ECGUsedTxSignal" SG_ 810 DteCldCnclRoute_B_Rq 1;
BA_ "U_CD542_MY2021_Tx" SG_ 810 DteCldCnclRoute_B_Rq 1;
BA_ "U_U55X_MY2022_Tx" SG_ 810 DteCldCnclRoute_B_Rq 1;
BA_ "U_CD764_MY2022_Tx" SG_ 810 DteCldCnclRoute_B_Rq 1;
BA_ "GenSigSendType" SG_ 810 NtfyDrvTrgtDist_L_Rq 3;
BA_ "WakeupSignal" SG_ 810 NtfyDrvTrgtDist_L_Rq 1;
BA_ "GenSigStartValueInteger" SG_ 810 NtfyDrvTrgtDist_L_Rq 1;
BA_ "GenSigStartValue" SG_ 810 NtfyDrvTrgtDist_L_Rq 4095;
BA_ "ECGUsedTxSignal" SG_ 810 NtfyDrvTrgtDist_L_Rq 1;
BA_ "U_CD542_MY2021_Tx" SG_ 810 NtfyDrvTrgtDist_L_Rq 1;
BA_ "U_U55X_MY2022_Tx" SG_ 810 NtfyDrvTrgtDist_L_Rq 1;
BA_ "GenSigSendType" SG_ 810 NtfyDrvSocLvl1_Pc_Rq 3;
BA_ "WakeupSignal" SG_ 810 NtfyDrvSocLvl1_Pc_Rq 1;
BA_ "GenSigStartValueInteger" SG_ 810 NtfyDrvSocLvl1_Pc_Rq 1;
BA_ "GenSigStartValue" SG_ 810 NtfyDrvSocLvl1_Pc_Rq 127;
BA_ "ECGUsedTxSignal" SG_ 810 NtfyDrvSocLvl1_Pc_Rq 1;
BA_ "U_CD542_MY2021_Tx" SG_ 810 NtfyDrvSocLvl1_Pc_Rq 1;
BA_ "U_U55X_MY2022_Tx" SG_ 810 NtfyDrvSocLvl1_Pc_Rq 1;
BA_ "GenSigSendType" SG_ 810 PtRmtRprt_D_Stat 3;
BA_ "WakeupSignal" SG_ 810 PtRmtRprt_D_Stat 1;
BA_ "ECGUsedTxSignal" SG_ 810 PtRmtRprt_D_Stat 1;
BA_ "U_CD542_MY2021_Tx" SG_ 810 PtRmtRprt_D_Stat 1;
BA_ "U_U55X_MY2022_Tx" SG_ 810 PtRmtRprt_D_Stat 1;
BA_ "GenSigSendType" SG_ 810 ChrgrPncEnbl_D_Rq 3;
BA_ "GenSigStartValueInteger" SG_ 810 ChrgrPncEnbl_D_Rq 3;
BA_ "GenSigStartValue" SG_ 810 ChrgrPncEnbl_D_Rq 3;
BA_ "ECGUsedTxSignal" SG_ 810 ChrgrPncEnbl_D_Rq 1;
BA_ "U_CD542_MY2021_Tx" SG_ 810 ChrgrPncEnbl_D_Rq 1;
BA_ "U_U55X_MY2022_Tx" SG_ 810 ChrgrPncEnbl_D_Rq 1;
BA_ "U_CD764_MY2022_Tx" SG_ 810 ChrgrPncEnbl_D_Rq 1;
BA_ "GenSigSendType" SG_ 810 OneTEditActv_B_RqCld 3;
BA_ "ECGUsedTxSignal" SG_ 810 OneTEditActv_B_RqCld 1;
BA_ "U_CD542_MY2021_Tx" SG_ 810 OneTEditActv_B_RqCld 1;
BA_ "U_U55X_MY2022_Tx" SG_ 810 OneTEditActv_B_RqCld 1;
BA_ "GenSigSendType" SG_ 810 GoTElementEdit_No_RqCld 3;
BA_ "ECGUsedTxSignal" SG_ 810 GoTElementEdit_No_RqCld 1;
BA_ "U_CD542_MY2021_Tx" SG_ 810 GoTElementEdit_No_RqCld 1;
BA_ "U_U55X_MY2022_Tx" SG_ 810 GoTElementEdit_No_RqCld 1;
BA_ "U_CD764_MY2022_Tx" SG_ 810 GoTElementEdit_No_RqCld 1;
BA_ "GenSigSendType" SG_ 810 OBCCSerial_D_Rq 3;
BA_ "ECGUsedTxSignal" SG_ 810 OBCCSerial_D_Rq 1;
BA_ "U_CD542_MY2021_Tx" SG_ 810 OBCCSerial_D_Rq 1;
BA_ "U_U55X_MY2022_Tx" SG_ 810 OBCCSerial_D_Rq 1;
BA_ "GenSigSendType" SG_ 810 ExtLghtDsply_B_StatArb 3;
BA_ "WakeupSignal" SG_ 810 ExtLghtDsply_B_StatArb 1;
BA_ "U_T6_MCA_MY2020_Tx" SG_ 810 ExtLghtDsply_B_StatArb 1;
BA_ "ECGUsedTxSignal" SG_ 810 ExtLghtDsply_B_StatArb 1;
BA_ "U_CD542_MY2021_Tx" SG_ 810 ExtLghtDsply_B_StatArb 1;
BA_ "U_U55X_MY2022_Tx" SG_ 810 ExtLghtDsply_B_StatArb 1;
BA_ "U_CD764_MY2022_Tx" SG_ 810 ExtLghtDsply_B_StatArb 1;
BA_ "GenSigSendType" SG_ 810 ExtLghtRight_D_RqOta 3;
BA_ "WakeupSignal" SG_ 810 ExtLghtRight_D_RqOta 1;
BA_ "U_T6_MCA_MY2020_Tx" SG_ 810 ExtLghtRight_D_RqOta 1;
BA_ "ECGUsedTxSignal" SG_ 810 ExtLghtRight_D_RqOta 1;
BA_ "U_CD542_MY2021_Tx" SG_ 810 ExtLghtRight_D_RqOta 1;
BA_ "U_U55X_MY2022_Tx" SG_ 810 ExtLghtRight_D_RqOta 1;
BA_ "U_CD764_MY2022_Tx" SG_ 810 ExtLghtRight_D_RqOta 1;
BA_ "GenSigSendType" SG_ 810 ExtLghtRear_D_RqOta 3;
BA_ "WakeupSignal" SG_ 810 ExtLghtRear_D_RqOta 1;
BA_ "U_T6_MCA_MY2020_Tx" SG_ 810 ExtLghtRear_D_RqOta 1;
BA_ "ECGUsedTxSignal" SG_ 810 ExtLghtRear_D_RqOta 1;
BA_ "U_CD542_MY2021_Tx" SG_ 810 ExtLghtRear_D_RqOta 1;
BA_ "U_U55X_MY2022_Tx" SG_ 810 ExtLghtRear_D_RqOta 1;
BA_ "U_CD764_MY2022_Tx" SG_ 810 ExtLghtRear_D_RqOta 1;
BA_ "GenSigSendType" SG_ 810 ExtLghtLeft_D_RqOta 3;
BA_ "WakeupSignal" SG_ 810 ExtLghtLeft_D_RqOta 1;
BA_ "U_T6_MCA_MY2020_Tx" SG_ 810 ExtLghtLeft_D_RqOta 1;
BA_ "ECGUsedTxSignal" SG_ 810 ExtLghtLeft_D_RqOta 1;
BA_ "U_CD542_MY2021_Tx" SG_ 810 ExtLghtLeft_D_RqOta 1;
BA_ "U_U55X_MY2022_Tx" SG_ 810 ExtLghtLeft_D_RqOta 1;
BA_ "U_CD764_MY2022_Tx" SG_ 810 ExtLghtLeft_D_RqOta 1;
BA_ "GenSigSendType" SG_ 810 ExtLghtFront_D_RqOta 3;
BA_ "WakeupSignal" SG_ 810 ExtLghtFront_D_RqOta 1;
BA_ "U_T6_MCA_MY2020_Tx" SG_ 810 ExtLghtFront_D_RqOta 1;
BA_ "ECGUsedTxSignal" SG_ 810 ExtLghtFront_D_RqOta 1;
BA_ "U_CD542_MY2021_Tx" SG_ 810 ExtLghtFront_D_RqOta 1;
BA_ "U_U55X_MY2022_Tx" SG_ 810 ExtLghtFront_D_RqOta 1;
BA_ "U_CD764_MY2022_Tx" SG_ 810 ExtLghtFront_D_RqOta 1;
BA_ "GenSigSendType" SG_ 810 TlghtTest_D_RqArb 3;
BA_ "U_T6_MCA_MY2020_Tx" SG_ 810 TlghtTest_D_RqArb 1;
BA_ "ECGUsedTxSignal" SG_ 810 TlghtTest_D_RqArb 1;
BA_ "U_CD542_MY2021_Tx" SG_ 810 TlghtTest_D_RqArb 1;
BA_ "U_U55X_MY2022_Tx" SG_ 810 TlghtTest_D_RqArb 1;
BA_ "GenSigSendType" SG_ 810 ChrgrPncSustn_B_Rq 3;
BA_ "GenSigStartValueInteger" SG_ 810 ChrgrPncSustn_B_Rq 3;
BA_ "ECGUsedTxSignal" SG_ 810 ChrgrPncSustn_B_Rq 1;
BA_ "U_CD542_MY2021_Tx" SG_ 810 ChrgrPncSustn_B_Rq 1;
BA_ "U_U55X_MY2022_Tx" SG_ 810 ChrgrPncSustn_B_Rq 1;
BA_ "U_CD764_MY2022_Tx" SG_ 810 ChrgrPncSustn_B_Rq 1;
BA_ "GenSigSendType" SG_ 810 GoTAirAmb_Te_ActlCld 3;
BA_ "GenSigStartValue" SG_ 810 GoTAirAmb_Te_ActlCld 512;
BA_ "ECGUsedTxSignal" SG_ 810 GoTAirAmb_Te_ActlCld 1;
BA_ "U_CD542_MY2021_Tx" SG_ 810 GoTAirAmb_Te_ActlCld 1;
BA_ "U_U55X_MY2022_Tx" SG_ 810 GoTAirAmb_Te_ActlCld 1;
BA_ "U_CD764_MY2022_Tx" SG_ 810 GoTAirAmb_Te_ActlCld 1;
BA_ "GenSigSendType" SG_ 563 BattChrgStrtStop_D2_Rq 3;
BA_ "ECGUsedTxSignal" SG_ 563 BattChrgStrtStop_D2_Rq 1;
BA_ "GenSigSendType" SG_ 563 DrvBhavAudioAlrt_D_Rq 3;
BA_ "ECGUsedTxSignal" SG_ 563 DrvBhavAudioAlrt_D_Rq 1;
BA_ "GenSigSendType" SG_ 563 NtfyDrvTrgtDist_L2_Rq 3;
BA_ "WakeupSignal" SG_ 563 NtfyDrvTrgtDist_L2_Rq 1;
BA_ "GenSigStartValueInteger" SG_ 563 NtfyDrvTrgtDist_L2_Rq 1;
BA_ "GenSigStartValue" SG_ 563 NtfyDrvTrgtDist_L2_Rq 8190;
BA_ "ECGUsedTxSignal" SG_ 563 NtfyDrvTrgtDist_L2_Rq 1;
BA_ "U_CD542_MY2021_Tx" SG_ 563 NtfyDrvTrgtDist_L2_Rq 1;
BA_ "GenSigSendType" SG_ 563 BattChrgStrtStop_D_Rq 3;
BA_ "U_T6_MCA_MY2020_Tx" SG_ 563 BattChrgStrtStop_D_Rq 1;
BA_ "ECGUsedTxSignal" SG_ 563 BattChrgStrtStop_D_Rq 1;
BA_ "U_CD542_MY2021_Tx" SG_ 563 BattChrgStrtStop_D_Rq 1;
BA_ "U_U55X_MY2022_Tx" SG_ 563 BattChrgStrtStop_D_Rq 1;
BA_ "GenSigSendType" SG_ 563 DrvBhavWarn_B_Rq 3;
BA_ "U_T6_MCA_MY2020_Tx" SG_ 563 DrvBhavWarn_B_Rq 1;
BA_ "ECGUsedTxSignal" SG_ 563 DrvBhavWarn_B_Rq 1;
BA_ "U_CD542_MY2021_Tx" SG_ 563 DrvBhavWarn_B_Rq 1;
BA_ "U_U55X_MY2022_Tx" SG_ 563 DrvBhavWarn_B_Rq 1;
BA_ "GenSigSendType" SG_ 563 OfbChrgSetSync_D_Rq 3;
BA_ "ECGUsedTxSignal" SG_ 563 OfbChrgSetSync_D_Rq 1;
BA_ "U_CD542_MY2021_Tx" SG_ 563 OfbChrgSetSync_D_Rq 1;
BA_ "U_U55X_MY2022_Tx" SG_ 563 OfbChrgSetSync_D_Rq 1;
BA_ "GenSigSendType" SG_ 563 KeyOffPwMde_D_Stat 3;
BA_ "U_T6_MCA_MY2020_Tx" SG_ 563 KeyOffPwMde_D_Stat 1;
BA_ "ECGUsedTxSignal" SG_ 563 KeyOffPwMde_D_Stat 1;
BA_ "U_CD542_MY2021_Tx" SG_ 563 KeyOffPwMde_D_Stat 1;
BA_ "U_U55X_MY2022_Tx" SG_ 563 KeyOffPwMde_D_Stat 1;
BA_ "GenSigSendType" SG_ 563 ModemReset_D_Stat 3;
BA_ "U_T6_MCA_MY2020_Tx" SG_ 563 ModemReset_D_Stat 1;
BA_ "ECGUsedTxSignal" SG_ 563 ModemReset_D_Stat 1;
BA_ "U_CD542_MY2021_Tx" SG_ 563 ModemReset_D_Stat 1;
BA_ "U_U55X_MY2022_Tx" SG_ 563 ModemReset_D_Stat 1;
BA_ "GenSigSendType" SG_ 563 FactoryReset_St 3;
BA_ "U_T6_MCA_MY2020_Tx" SG_ 563 FactoryReset_St 1;
BA_ "ECGUsedTxSignal" SG_ 563 FactoryReset_St 1;
BA_ "U_CD542_MY2021_Tx" SG_ 563 FactoryReset_St 1;
BA_ "U_U55X_MY2022_Tx" SG_ 563 FactoryReset_St 1;
BA_ "GenSigSendType" SG_ 2609923288 OTAPhysGWM_ECGtoSOBDMC 3;
BA_ "U_CX727_MY2021_Rx" SG_ 2609923288 OTAPhysGWM_ECGtoSOBDMC 1;
BA_ "U_P702_MY2021_Rx" SG_ 2609923288 OTAPhysGWM_ECGtoSOBDMC 1;
BA_ "U_CD542_MY2021_Rx" SG_ 2609923288 OTAPhysGWM_ECGtoSOBDMC 1;
BA_ "ECGUsedTxSignal" SG_ 2609923288 OTAPhysGWM_ECGtoSOBDMC 1;
BA_ "U_CD542_MY2021_Tx" SG_ 2609923288 OTAPhysGWM_ECGtoSOBDMC 1;
BA_ "U_U55X_MY2022_Tx" SG_ 2609923288 OTAPhysGWM_ECGtoSOBDMC 1;
BA_ "GenSigSendType" SG_ 2610126865 OTAPhysSOBDMCtoGWM_ECG 3;
BA_ "ECGUsedRxSignal" SG_ 2610126865 OTAPhysSOBDMCtoGWM_ECG 1;
BA_ "U_CD542_MY2021_Rx" SG_ 2610126865 OTAPhysSOBDMCtoGWM_ECG 1;
BA_ "U_U55X_MY2022_Rx" SG_ 2610126865 OTAPhysSOBDMCtoGWM_ECG 1;
BA_ "U_P702_MY2021_Tx" SG_ 2610126865 OTAPhysSOBDMCtoGWM_ECG 1;
BA_ "U_CD542_MY2021_Tx" SG_ 2610126865 OTAPhysSOBDMCtoGWM_ECG 1;
BA_ "GenSigSendType" SG_ 2610971864 PARSEDPhysGWM_ECGtoSOBDMC 3;
BA_ "U_P702_MY2021_Rx" SG_ 2610971864 PARSEDPhysGWM_ECGtoSOBDMC 1;
BA_ "U_CD542_MY2021_Rx" SG_ 2610971864 PARSEDPhysGWM_ECGtoSOBDMC 1;
BA_ "ECGUsedTxSignal" SG_ 2610971864 PARSEDPhysGWM_ECGtoSOBDMC 1;
BA_ "U_CD542_MY2021_Tx" SG_ 2610971864 PARSEDPhysGWM_ECGtoSOBDMC 1;
BA_ "U_U55X_MY2022_Tx" SG_ 2610971864 PARSEDPhysGWM_ECGtoSOBDMC 1;
BA_ "GenSigSendType" SG_ 2611175441 PARSEDPhysSOBDMCtoGWM_ECG 3;
BA_ "ECGUsedRxSignal" SG_ 2611175441 PARSEDPhysSOBDMCtoGWM_ECG 1;
BA_ "U_CD542_MY2021_Rx" SG_ 2611175441 PARSEDPhysSOBDMCtoGWM_ECG 1;
BA_ "U_U55X_MY2022_Rx" SG_ 2611175441 PARSEDPhysSOBDMCtoGWM_ECG 1;
BA_ "U_CD542_MY2021_Tx" SG_ 2611175441 PARSEDPhysSOBDMCtoGWM_ECG 1;
BA_ "GenSigSendType" SG_ 2610126946 OTAPhysSODLtoGWM_ECG 3;
BA_ "U_T6_MCA_MY2020_Rx" SG_ 2610126946 OTAPhysSODLtoGWM_ECG 1;
BA_ "ECGUsedRxSignal" SG_ 2610126946 OTAPhysSODLtoGWM_ECG 1;
BA_ "U_CD542_MY2021_Rx" SG_ 2610126946 OTAPhysSODLtoGWM_ECG 1;
BA_ "U_U55X_MY2022_Rx" SG_ 2610126946 OTAPhysSODLtoGWM_ECG 1;
BA_ "U_T6_MCA_MY2020_Tx" SG_ 2610126946 OTAPhysSODLtoGWM_ECG 1;
BA_ "U_CD542_MY2021_Tx" SG_ 2610126946 OTAPhysSODLtoGWM_ECG 1;
BA_ "U_U55X_MY2022_Tx" SG_ 2610126946 OTAPhysSODLtoGWM_ECG 1;
BA_ "U_CD764_MY2022_Tx" SG_ 2610126946 OTAPhysSODLtoGWM_ECG 1;
BA_ "GenSigSendType" SG_ 2610006232 OTAPhysGWM_ECGtoSODL 3;
BA_ "U_T6_MCA_MY2020_Rx" SG_ 2610006232 OTAPhysGWM_ECGtoSODL 1;
BA_ "U_CD542_MY2021_Rx" SG_ 2610006232 OTAPhysGWM_ECGtoSODL 1;
BA_ "U_U55X_MY2022_Rx" SG_ 2610006232 OTAPhysGWM_ECGtoSODL 1;
BA_ "U_CD764_MY2022_Rx" SG_ 2610006232 OTAPhysGWM_ECGtoSODL 1;
BA_ "U_T6_MCA_MY2020_Tx" SG_ 2610006232 OTAPhysGWM_ECGtoSODL 1;
BA_ "ECGUsedTxSignal" SG_ 2610006232 OTAPhysGWM_ECGtoSODL 1;
BA_ "U_CD542_MY2021_Tx" SG_ 2610006232 OTAPhysGWM_ECGtoSODL 1;
BA_ "U_U55X_MY2022_Tx" SG_ 2610006232 OTAPhysGWM_ECGtoSODL 1;
BA_ "GenSigSendType" SG_ 1993 TesterPhysicalResCMR_DSMC 3;
BA_ "U_T6_MCA_MY2020_Tx" SG_ 1993 TesterPhysicalResCMR_DSMC 1;
BA_ "U_CD542_MY2021_Tx" SG_ 1993 TesterPhysicalResCMR_DSMC 1;
BA_ "U_U55X_MY2022_Tx" SG_ 1993 TesterPhysicalResCMR_DSMC 1;
BA_ "U_CD764_MY2022_Tx" SG_ 1993 TesterPhysicalResCMR_DSMC 1;
BA_ "GenSigSendType" SG_ 1985 TesterPhysicalReqCMR_DSMC 3;
BA_ "U_T6_MCA_MY2020_Rx" SG_ 1985 TesterPhysicalReqCMR_DSMC 1;
BA_ "U_CD542_MY2021_Rx" SG_ 1985 TesterPhysicalReqCMR_DSMC 1;
BA_ "U_U55X_MY2022_Rx" SG_ 1985 TesterPhysicalReqCMR_DSMC 1;
BA_ "U_CD764_MY2022_Rx" SG_ 1985 TesterPhysicalReqCMR_DSMC 1;
BA_ "GenSigStartValueInteger" SG_ 1503 CMR_DSMC_GWOnBoardTester 255;
BA_ "ContentDependant" SG_ 1503 CMR_DSMC_GWOnBoardTester 1;
BA_ "GenSigStartValue" SG_ 1503 CMR_DSMC_GWOnBoardTester 255;
BA_ "U_T6_MCA_MY2020_Tx" SG_ 1503 CMR_DSMC_GWOnBoardTester 1;
BA_ "U_CD542_MY2021_Tx" SG_ 1503 CMR_DSMC_GWOnBoardTester 1;
BA_ "U_U55X_MY2022_Tx" SG_ 1503 CMR_DSMC_GWOnBoardTester 1;
BA_ "U_CD764_MY2022_Tx" SG_ 1503 CMR_DSMC_GWOnBoardTester 1;
BA_ "GenSigStartValueInteger" SG_ 1503 CMR_DSMC_GWNMProxY 255;
BA_ "ContentDependant" SG_ 1503 CMR_DSMC_GWNMProxY 1;
BA_ "GenSigStartValue" SG_ 1503 CMR_DSMC_GWNMProxY 255;
BA_ "U_T6_MCA_MY2020_Tx" SG_ 1503 CMR_DSMC_GWNMProxY 1;
BA_ "U_CD542_MY2021_Tx" SG_ 1503 CMR_DSMC_GWNMProxY 1;
BA_ "U_U55X_MY2022_Tx" SG_ 1503 CMR_DSMC_GWNMProxY 1;
BA_ "U_CD764_MY2022_Tx" SG_ 1503 CMR_DSMC_GWNMProxY 1;
BA_ "GenSigStartValueInteger" SG_ 1503 CMR_DSMC_AutoSarNMReserved 255;
BA_ "ContentDependant" SG_ 1503 CMR_DSMC_AutoSarNMReserved 1;
BA_ "GenSigStartValue" SG_ 1503 CMR_DSMC_AutoSarNMReserved 255;
BA_ "U_T6_MCA_MY2020_Tx" SG_ 1503 CMR_DSMC_AutoSarNMReserved 1;
BA_ "U_CD542_MY2021_Tx" SG_ 1503 CMR_DSMC_AutoSarNMReserved 1;
BA_ "U_U55X_MY2022_Tx" SG_ 1503 CMR_DSMC_AutoSarNMReserved 1;
BA_ "U_CD764_MY2022_Tx" SG_ 1503 CMR_DSMC_AutoSarNMReserved 1;
BA_ "GenSigStartValueInteger" SG_ 1503 CMR_DSMC_AutoSarNMReserve4 255;
BA_ "ContentDependant" SG_ 1503 CMR_DSMC_AutoSarNMReserve4 1;
BA_ "GenSigStartValue" SG_ 1503 CMR_DSMC_AutoSarNMReserve4 255;
BA_ "U_T6_MCA_MY2020_Tx" SG_ 1503 CMR_DSMC_AutoSarNMReserve4 1;
BA_ "U_CD542_MY2021_Tx" SG_ 1503 CMR_DSMC_AutoSarNMReserve4 1;
BA_ "U_U55X_MY2022_Tx" SG_ 1503 CMR_DSMC_AutoSarNMReserve4 1;
BA_ "U_CD764_MY2022_Tx" SG_ 1503 CMR_DSMC_AutoSarNMReserve4 1;
BA_ "GenSigStartValueInteger" SG_ 1503 CMR_DSMC_AutoSarNMReserve3 255;
BA_ "ContentDependant" SG_ 1503 CMR_DSMC_AutoSarNMReserve3 1;
BA_ "GenSigStartValue" SG_ 1503 CMR_DSMC_AutoSarNMReserve3 255;
BA_ "U_T6_MCA_MY2020_Tx" SG_ 1503 CMR_DSMC_AutoSarNMReserve3 1;
BA_ "U_CD542_MY2021_Tx" SG_ 1503 CMR_DSMC_AutoSarNMReserve3 1;
BA_ "U_U55X_MY2022_Tx" SG_ 1503 CMR_DSMC_AutoSarNMReserve3 1;
BA_ "U_CD764_MY2022_Tx" SG_ 1503 CMR_DSMC_AutoSarNMReserve3 1;
BA_ "GenSigStartValueInteger" SG_ 1503 CMR_DSMC_AutoSarNMReserve2 255;
BA_ "ContentDependant" SG_ 1503 CMR_DSMC_AutoSarNMReserve2 1;
BA_ "GenSigStartValue" SG_ 1503 CMR_DSMC_AutoSarNMReserve2 255;
BA_ "U_T6_MCA_MY2020_Tx" SG_ 1503 CMR_DSMC_AutoSarNMReserve2 1;
BA_ "U_CD542_MY2021_Tx" SG_ 1503 CMR_DSMC_AutoSarNMReserve2 1;
BA_ "U_U55X_MY2022_Tx" SG_ 1503 CMR_DSMC_AutoSarNMReserve2 1;
BA_ "U_CD764_MY2022_Tx" SG_ 1503 CMR_DSMC_AutoSarNMReserve2 1;
BA_ "GenSigStartValueInteger" SG_ 1503 CMR_DSMC_AutoSarNMNodeId 222;
BA_ "ContentDependant" SG_ 1503 CMR_DSMC_AutoSarNMNodeId 1;
BA_ "GenSigStartValue" SG_ 1503 CMR_DSMC_AutoSarNMNodeId 223;
BA_ "U_T6_MCA_MY2020_Tx" SG_ 1503 CMR_DSMC_AutoSarNMNodeId 1;
BA_ "U_CD542_MY2021_Tx" SG_ 1503 CMR_DSMC_AutoSarNMNodeId 1;
BA_ "U_U55X_MY2022_Tx" SG_ 1503 CMR_DSMC_AutoSarNMNodeId 1;
BA_ "U_CD764_MY2022_Tx" SG_ 1503 CMR_DSMC_AutoSarNMNodeId 1;
BA_ "ContentDependant" SG_ 1503 CMR_DSMC_AutoSarNMControl 1;
BA_ "U_T6_MCA_MY2020_Tx" SG_ 1503 CMR_DSMC_AutoSarNMControl 1;
BA_ "U_CD542_MY2021_Tx" SG_ 1503 CMR_DSMC_AutoSarNMControl 1;
BA_ "U_U55X_MY2022_Tx" SG_ 1503 CMR_DSMC_AutoSarNMControl 1;
BA_ "U_CD764_MY2022_Tx" SG_ 1503 CMR_DSMC_AutoSarNMControl 1;
BA_ "U_CX727_MY2021_Rx" SG_ 1119 CoolFanDcdc_D_Rq 1;
BA_ "U_P702_MY2021_Rx" SG_ 1119 CoolFanDcdc_D_Rq 1;
BA_ "U_CD542_MY2021_Rx" SG_ 1119 CoolFanDcdc_D_Rq 1;
BA_ "U_CX727_MY2021_Rx" SG_ 1119 DcdcClntFlw_D_Rq 1;
BA_ "U_P702_MY2021_Rx" SG_ 1119 DcdcClntFlw_D_Rq 1;
BA_ "U_CD542_MY2021_Rx" SG_ 1119 DcdcClntFlw_D_Rq 1;
BA_ "GenSigStartValue" SG_ 1119 PwrSrcULo_Te_Actl 1022;
BA_ "GenSigSendType" SG_ 2022 TesterPhysicalReqSOBDMC 3;
BA_ "U_CX727_MY2021_Rx" SG_ 2022 TesterPhysicalReqSOBDMC 1;
BA_ "U_P702_MY2021_Rx" SG_ 2022 TesterPhysicalReqSOBDMC 1;
BA_ "U_CD542_MY2021_Rx" SG_ 2022 TesterPhysicalReqSOBDMC 1;
BA_ "U_CX727_MY2021_Rx" SG_ 912 GearPrkMtr_D_Stat 1;
BA_ "U_CD542_MY2021_Rx" SG_ 912 GearPrkMtr_D_Stat 1;
BA_ "U_CX727_MY2021_Rx" SG_ 912 GearPrkLck_D_Stat 1;
BA_ "U_CD542_MY2021_Rx" SG_ 912 GearPrkLck_D_Stat 1;
BA_ "U_CX727_MY2021_Rx" SG_ 912 CabnEvapSovFront_D_Stat 1;
BA_ "U_P702_MY2021_Rx" SG_ 912 CabnEvapSovFront_D_Stat 1;
BA_ "U_CD542_MY2021_Rx" SG_ 912 CabnEvapSovFront_D_Stat 1;
BA_ "U_P702_MY2021_Rx" SG_ 912 BattChlrSov_D_Stat 1;
BA_ "U_CD542_MY2021_Rx" SG_ 912 BattChlrSov_D_Stat 1;
BA_ "U_P702_MY2021_Rx" SG_ 912 BattTracClntVlv_D_Stat 1;
BA_ "U_CD542_MY2021_Rx" SG_ 912 BattTracClntVlv_D_Stat 1;
BA_ "U_CX727_MY2021_Rx" SG_ 651 TelematicsSrvc_D_St 1;
BA_ "U_P702_MY2021_Rx" SG_ 651 TelematicsSrvc_D_St 1;
BA_ "GenSigSendType" SG_ 2609955032 OTAPhysGWM_ECGtoPSCM 3;
BA_ "U_CD542_MY2021_Rx" SG_ 2609955032 OTAPhysGWM_ECGtoPSCM 1;
BA_ "U_U55X_MY2022_Rx" SG_ 2609955032 OTAPhysGWM_ECGtoPSCM 1;
BA_ "U_CD764_MY2022_Rx" SG_ 2609955032 OTAPhysGWM_ECGtoPSCM 1;
BA_ "ECGUsedTxSignal" SG_ 2609955032 OTAPhysGWM_ECGtoPSCM 1;
BA_ "U_CD542_MY2021_Tx" SG_ 2609955032 OTAPhysGWM_ECGtoPSCM 1;
BA_ "U_U55X_MY2022_Tx" SG_ 2609955032 OTAPhysGWM_ECGtoPSCM 1;
BA_ "U_CD764_MY2022_Tx" SG_ 2609955032 OTAPhysGWM_ECGtoPSCM 1;
BA_ "GenSigSendType" SG_ 2610126896 OTAPhysPSCMtoGWM_ECG 3;
BA_ "ECGUsedRxSignal" SG_ 2610126896 OTAPhysPSCMtoGWM_ECG 1;
BA_ "U_CD542_MY2021_Rx" SG_ 2610126896 OTAPhysPSCMtoGWM_ECG 1;
BA_ "U_U55X_MY2022_Rx" SG_ 2610126896 OTAPhysPSCMtoGWM_ECG 1;
BA_ "U_CD764_MY2022_Rx" SG_ 2610126896 OTAPhysPSCMtoGWM_ECG 1;
BA_ "U_CD542_MY2021_Tx" SG_ 2610126896 OTAPhysPSCMtoGWM_ECG 1;
BA_ "U_U55X_MY2022_Tx" SG_ 2610126896 OTAPhysPSCMtoGWM_ECG 1;
BA_ "U_CD764_MY2022_Tx" SG_ 2610126896 OTAPhysPSCMtoGWM_ECG 1;
BA_ "GenSigSendType" SG_ 2611003608 PARSEDPhysGWM_ECGtoPSCM 3;
BA_ "U_CD542_MY2021_Rx" SG_ 2611003608 PARSEDPhysGWM_ECGtoPSCM 1;
BA_ "U_U55X_MY2022_Rx" SG_ 2611003608 PARSEDPhysGWM_ECGtoPSCM 1;
BA_ "U_CD764_MY2022_Rx" SG_ 2611003608 PARSEDPhysGWM_ECGtoPSCM 1;
BA_ "ECGUsedTxSignal" SG_ 2611003608 PARSEDPhysGWM_ECGtoPSCM 1;
BA_ "U_CD542_MY2021_Tx" SG_ 2611003608 PARSEDPhysGWM_ECGtoPSCM 1;
BA_ "U_U55X_MY2022_Tx" SG_ 2611003608 PARSEDPhysGWM_ECGtoPSCM 1;
BA_ "U_CD764_MY2022_Tx" SG_ 2611003608 PARSEDPhysGWM_ECGtoPSCM 1;
BA_ "GenSigSendType" SG_ 2612224048 PARSEDPushPSCMtoGWM_ECG 3;
BA_ "ECGUsedRxSignal" SG_ 2612224048 PARSEDPushPSCMtoGWM_ECG 1;
BA_ "U_CD542_MY2021_Rx" SG_ 2612224048 PARSEDPushPSCMtoGWM_ECG 1;
BA_ "U_U55X_MY2022_Rx" SG_ 2612224048 PARSEDPushPSCMtoGWM_ECG 1;
BA_ "U_CD764_MY2022_Rx" SG_ 2612224048 PARSEDPushPSCMtoGWM_ECG 1;
BA_ "U_CD542_MY2021_Tx" SG_ 2612224048 PARSEDPushPSCMtoGWM_ECG 1;
BA_ "U_U55X_MY2022_Tx" SG_ 2612224048 PARSEDPushPSCMtoGWM_ECG 1;
BA_ "U_CD764_MY2022_Tx" SG_ 2612224048 PARSEDPushPSCMtoGWM_ECG 1;
BA_ "GenSigSendType" SG_ 2611175472 PARSEDPhysPSCMtoGWM_ECG 3;
BA_ "ECGUsedRxSignal" SG_ 2611175472 PARSEDPhysPSCMtoGWM_ECG 1;
BA_ "U_CD542_MY2021_Rx" SG_ 2611175472 PARSEDPhysPSCMtoGWM_ECG 1;
BA_ "U_U55X_MY2022_Rx" SG_ 2611175472 PARSEDPhysPSCMtoGWM_ECG 1;
BA_ "U_CD764_MY2022_Rx" SG_ 2611175472 PARSEDPhysPSCMtoGWM_ECG 1;
BA_ "U_CD542_MY2021_Tx" SG_ 2611175472 PARSEDPhysPSCMtoGWM_ECG 1;
BA_ "U_U55X_MY2022_Tx" SG_ 2611175472 PARSEDPhysPSCMtoGWM_ECG 1;
BA_ "U_CD764_MY2022_Tx" SG_ 2611175472 PARSEDPhysPSCMtoGWM_ECG 1;
BA_ "U_CX727_MY2021_Rx" SG_ 1150 LocationServices_1 1;
BA_ "U_T6_MCA_MY2020_Rx" SG_ 1150 LocationServices_1 1;
BA_ "U_CD542_MY2021_Rx" SG_ 1150 LocationServices_1 1;
BA_ "U_U55X_MY2022_Rx" SG_ 1150 LocationServices_1 1;
BA_ "GenSigSendType" SG_ 2612224033 PARSEDPushIPMAtoGWM_ECG 3;
BA_ "U_T6_MCA_MY2020_Rx" SG_ 2612224033 PARSEDPushIPMAtoGWM_ECG 1;
BA_ "ECGUsedRxSignal" SG_ 2612224033 PARSEDPushIPMAtoGWM_ECG 1;
BA_ "U_CD542_MY2021_Rx" SG_ 2612224033 PARSEDPushIPMAtoGWM_ECG 1;
BA_ "U_U55X_MY2022_Rx" SG_ 2612224033 PARSEDPushIPMAtoGWM_ECG 1;
BA_ "U_CD764_MY2022_Rx" SG_ 2612224033 PARSEDPushIPMAtoGWM_ECG 1;
BA_ "U_T6_MCA_MY2020_Tx" SG_ 2612224033 PARSEDPushIPMAtoGWM_ECG 1;
BA_ "U_CD542_MY2021_Tx" SG_ 2612224033 PARSEDPushIPMAtoGWM_ECG 1;
BA_ "U_U55X_MY2022_Tx" SG_ 2612224033 PARSEDPushIPMAtoGWM_ECG 1;
BA_ "U_CD764_MY2022_Tx" SG_ 2612224033 PARSEDPushIPMAtoGWM_ECG 1;
BA_ "GenSigSendType" SG_ 2609939672 OTAPhysGWM_ECGtoIPMA 3;
BA_ "U_T6_MCA_MY2020_Rx" SG_ 2609939672 OTAPhysGWM_ECGtoIPMA 1;
BA_ "U_CD542_MY2021_Rx" SG_ 2609939672 OTAPhysGWM_ECGtoIPMA 1;
BA_ "U_U55X_MY2022_Rx" SG_ 2609939672 OTAPhysGWM_ECGtoIPMA 1;
BA_ "U_CD764_MY2022_Rx" SG_ 2609939672 OTAPhysGWM_ECGtoIPMA 1;
BA_ "U_T6_MCA_MY2020_Tx" SG_ 2609939672 OTAPhysGWM_ECGtoIPMA 1;
BA_ "ECGUsedTxSignal" SG_ 2609939672 OTAPhysGWM_ECGtoIPMA 1;
BA_ "U_CD542_MY2021_Tx" SG_ 2609939672 OTAPhysGWM_ECGtoIPMA 1;
BA_ "U_U55X_MY2022_Tx" SG_ 2609939672 OTAPhysGWM_ECGtoIPMA 1;
BA_ "U_CD764_MY2022_Tx" SG_ 2609939672 OTAPhysGWM_ECGtoIPMA 1;
BA_ "GenSigSendType" SG_ 2610126881 OTAPhysIPMAtoGWM_ECG 3;
BA_ "U_T6_MCA_MY2020_Rx" SG_ 2610126881 OTAPhysIPMAtoGWM_ECG 1;
BA_ "ECGUsedRxSignal" SG_ 2610126881 OTAPhysIPMAtoGWM_ECG 1;
BA_ "U_CD542_MY2021_Rx" SG_ 2610126881 OTAPhysIPMAtoGWM_ECG 1;
BA_ "U_U55X_MY2022_Rx" SG_ 2610126881 OTAPhysIPMAtoGWM_ECG 1;
BA_ "U_CD764_MY2022_Rx" SG_ 2610126881 OTAPhysIPMAtoGWM_ECG 1;
BA_ "U_T6_MCA_MY2020_Tx" SG_ 2610126881 OTAPhysIPMAtoGWM_ECG 1;
BA_ "U_CD542_MY2021_Tx" SG_ 2610126881 OTAPhysIPMAtoGWM_ECG 1;
BA_ "U_U55X_MY2022_Tx" SG_ 2610126881 OTAPhysIPMAtoGWM_ECG 1;
BA_ "U_CD764_MY2022_Tx" SG_ 2610126881 OTAPhysIPMAtoGWM_ECG 1;
BA_ "GenSigSendType" SG_ 2612043992 PARSEDPushFcGWM_ECGtoABS 3;
BA_ "U_T6_MCA_MY2020_Rx" SG_ 2612043992 PARSEDPushFcGWM_ECGtoABS 1;
BA_ "U_CD542_MY2021_Rx" SG_ 2612043992 PARSEDPushFcGWM_ECGtoABS 1;
BA_ "U_U55X_MY2022_Rx" SG_ 2612043992 PARSEDPushFcGWM_ECGtoABS 1;
BA_ "U_CD764_MY2022_Rx" SG_ 2612043992 PARSEDPushFcGWM_ECGtoABS 1;
BA_ "U_T6_MCA_MY2020_Tx" SG_ 2612043992 PARSEDPushFcGWM_ECGtoABS 1;
BA_ "ECGUsedTxSignal" SG_ 2612043992 PARSEDPushFcGWM_ECGtoABS 1;
BA_ "U_CD542_MY2021_Tx" SG_ 2612043992 PARSEDPushFcGWM_ECGtoABS 1;
BA_ "U_U55X_MY2022_Tx" SG_ 2612043992 PARSEDPushFcGWM_ECGtoABS 1;
BA_ "U_CD764_MY2022_Tx" SG_ 2612043992 PARSEDPushFcGWM_ECGtoABS 1;
BA_ "GenSigSendType" SG_ 2610995416 PARSEDPhysGWM_ECGtoABS 3;
BA_ "U_T6_MCA_MY2020_Rx" SG_ 2610995416 PARSEDPhysGWM_ECGtoABS 1;
BA_ "U_CD542_MY2021_Rx" SG_ 2610995416 PARSEDPhysGWM_ECGtoABS 1;
BA_ "U_U55X_MY2022_Rx" SG_ 2610995416 PARSEDPhysGWM_ECGtoABS 1;
BA_ "U_CD764_MY2022_Rx" SG_ 2610995416 PARSEDPhysGWM_ECGtoABS 1;
BA_ "U_T6_MCA_MY2020_Tx" SG_ 2610995416 PARSEDPhysGWM_ECGtoABS 1;
BA_ "ECGUsedTxSignal" SG_ 2610995416 PARSEDPhysGWM_ECGtoABS 1;
BA_ "U_CD542_MY2021_Tx" SG_ 2610995416 PARSEDPhysGWM_ECGtoABS 1;
BA_ "U_U55X_MY2022_Tx" SG_ 2610995416 PARSEDPhysGWM_ECGtoABS 1;
BA_ "U_CD764_MY2022_Tx" SG_ 2610995416 PARSEDPhysGWM_ECGtoABS 1;
BA_ "GenSigSendType" SG_ 2612224040 PARSEDPushABStoGWM_ECG 3;
BA_ "U_T6_MCA_MY2020_Rx" SG_ 2612224040 PARSEDPushABStoGWM_ECG 1;
BA_ "ECGUsedRxSignal" SG_ 2612224040 PARSEDPushABStoGWM_ECG 1;
BA_ "U_CD542_MY2021_Rx" SG_ 2612224040 PARSEDPushABStoGWM_ECG 1;
BA_ "U_U55X_MY2022_Rx" SG_ 2612224040 PARSEDPushABStoGWM_ECG 1;
BA_ "U_CD764_MY2022_Rx" SG_ 2612224040 PARSEDPushABStoGWM_ECG 1;
BA_ "U_T6_MCA_MY2020_Tx" SG_ 2612224040 PARSEDPushABStoGWM_ECG 1;
BA_ "U_CD542_MY2021_Tx" SG_ 2612224040 PARSEDPushABStoGWM_ECG 1;
BA_ "U_U55X_MY2022_Tx" SG_ 2612224040 PARSEDPushABStoGWM_ECG 1;
BA_ "U_CD764_MY2022_Tx" SG_ 2612224040 PARSEDPushABStoGWM_ECG 1;
BA_ "GenSigSendType" SG_ 2611175464 PARSEDPhysABStoGWM_ECG 3;
BA_ "U_T6_MCA_MY2020_Rx" SG_ 2611175464 PARSEDPhysABStoGWM_ECG 1;
BA_ "ECGUsedRxSignal" SG_ 2611175464 PARSEDPhysABStoGWM_ECG 1;
BA_ "U_CD542_MY2021_Rx" SG_ 2611175464 PARSEDPhysABStoGWM_ECG 1;
BA_ "U_U55X_MY2022_Rx" SG_ 2611175464 PARSEDPhysABStoGWM_ECG 1;
BA_ "U_CD764_MY2022_Rx" SG_ 2611175464 PARSEDPhysABStoGWM_ECG 1;
BA_ "U_T6_MCA_MY2020_Tx" SG_ 2611175464 PARSEDPhysABStoGWM_ECG 1;
BA_ "U_CD542_MY2021_Tx" SG_ 2611175464 PARSEDPhysABStoGWM_ECG 1;
BA_ "U_U55X_MY2022_Tx" SG_ 2611175464 PARSEDPhysABStoGWM_ECG 1;
BA_ "U_CD764_MY2022_Tx" SG_ 2611175464 PARSEDPhysABStoGWM_ECG 1;
BA_ "U_CX727_MY2021_Rx" SG_ 529 OnbChrgToPcWknd_D_Actl 1;
BA_ "U_P702_MY2021_Rx" SG_ 529 OnbChrgToPcWknd_D_Actl 1;
BA_ "U_CD542_MY2021_Rx" SG_ 529 OnbChrgToPcWknd_D_Actl 1;
BA_ "U_CX727_MY2021_Rx" SG_ 529 OnbChrgToPcWkdy_D_Actl 1;
BA_ "U_P702_MY2021_Rx" SG_ 529 OnbChrgToPcWkdy_D_Actl 1;
BA_ "U_CD542_MY2021_Rx" SG_ 529 OnbChrgToPcWkdy_D_Actl 1;
BA_ "U_CX727_MY2021_Rx" SG_ 529 OnbChrgSetNow_D_Rq 1;
BA_ "U_P702_MY2021_Rx" SG_ 529 OnbChrgSetNow_D_Rq 1;
BA_ "U_CD542_MY2021_Rx" SG_ 529 OnbChrgSetNow_D_Rq 1;
BA_ "U_CX727_MY2021_Rx" SG_ 529 OnbChrgSetDelete_B_Rq 1;
BA_ "U_P702_MY2021_Rx" SG_ 529 OnbChrgSetDelete_B_Rq 1;
BA_ "U_CD542_MY2021_Rx" SG_ 529 OnbChrgSetDelete_B_Rq 1;
BA_ "U_CX727_MY2021_Rx" SG_ 529 OnbChrgPrflWknd_No_Rq 1;
BA_ "U_P702_MY2021_Rx" SG_ 529 OnbChrgPrflWknd_No_Rq 1;
BA_ "U_CD542_MY2021_Rx" SG_ 529 OnbChrgPrflWknd_No_Rq 1;
BA_ "U_CX727_MY2021_Rx" SG_ 529 OnbChrgPrflWkdy_No_Rq 1;
BA_ "U_P702_MY2021_Rx" SG_ 529 OnbChrgPrflWkdy_No_Rq 1;
BA_ "U_CD542_MY2021_Rx" SG_ 529 OnbChrgPrflWkdy_No_Rq 1;
BA_ "U_CX727_MY2021_Rx" SG_ 529 OnbChrgPrflUpdate_B_Rq 1;
BA_ "U_P702_MY2021_Rx" SG_ 529 OnbChrgPrflUpdate_B_Rq 1;
BA_ "U_CD542_MY2021_Rx" SG_ 529 OnbChrgPrflUpdate_B_Rq 1;
BA_ "U_CX727_MY2021_Rx" SG_ 529 OnbChrgLocIdUns_B_Rq 1;
BA_ "U_P702_MY2021_Rx" SG_ 529 OnbChrgLocIdUns_B_Rq 1;
BA_ "U_CD542_MY2021_Rx" SG_ 529 OnbChrgLocIdUns_B_Rq 1;
BA_ "U_CX727_MY2021_Rx" SG_ 529 OnbChrgLocIdTrgt_No_Rq 1;
BA_ "U_P702_MY2021_Rx" SG_ 529 OnbChrgLocIdTrgt_No_Rq 1;
BA_ "U_CD542_MY2021_Rx" SG_ 529 OnbChrgLocIdTrgt_No_Rq 1;
BA_ "GenSigSendType" SG_ 1679 UUDTSOBDMCResponse4 3;
BA_ "U_CX727_MY2021_Tx" SG_ 1679 UUDTSOBDMCResponse4 1;
BA_ "U_P702_MY2021_Tx" SG_ 1679 UUDTSOBDMCResponse4 1;
BA_ "U_CD542_MY2021_Tx" SG_ 1679 UUDTSOBDMCResponse4 1;
BA_ "GenSigSendType" SG_ 1678 UUDTSOBDMCResponse3 3;
BA_ "U_CX727_MY2021_Tx" SG_ 1678 UUDTSOBDMCResponse3 1;
BA_ "U_P702_MY2021_Tx" SG_ 1678 UUDTSOBDMCResponse3 1;
BA_ "U_CD542_MY2021_Tx" SG_ 1678 UUDTSOBDMCResponse3 1;
BA_ "GenSigSendType" SG_ 1677 UUDTSOBDMCResponse2 3;
BA_ "U_CX727_MY2021_Tx" SG_ 1677 UUDTSOBDMCResponse2 1;
BA_ "U_P702_MY2021_Tx" SG_ 1677 UUDTSOBDMCResponse2 1;
BA_ "U_CD542_MY2021_Tx" SG_ 1677 UUDTSOBDMCResponse2 1;
BA_ "GenSigSendType" SG_ 1676 UUDTSOBDMCResponse1 3;
BA_ "U_CX727_MY2021_Tx" SG_ 1676 UUDTSOBDMCResponse1 1;
BA_ "U_P702_MY2021_Tx" SG_ 1676 UUDTSOBDMCResponse1 1;
BA_ "U_CD542_MY2021_Tx" SG_ 1676 UUDTSOBDMCResponse1 1;
BA_ "GenSigStartValueInteger" SG_ 1445 SOBDMC_AutoSarNMReserved4 255;
BA_ "ContentDependant" SG_ 1445 SOBDMC_AutoSarNMReserved4 1;
BA_ "GenSigStartValue" SG_ 1445 SOBDMC_AutoSarNMReserved4 255;
BA_ "U_CX727_MY2021_Rx" SG_ 1445 SOBDMC_AutoSarNMReserved4 1;
BA_ "U_CD542_MY2021_Rx" SG_ 1445 SOBDMC_AutoSarNMReserved4 1;
BA_ "U_CX727_MY2021_Tx" SG_ 1445 SOBDMC_AutoSarNMReserved4 1;
BA_ "U_P702_MY2021_Tx" SG_ 1445 SOBDMC_AutoSarNMReserved4 1;
BA_ "U_CD542_MY2021_Tx" SG_ 1445 SOBDMC_AutoSarNMReserved4 1;
BA_ "GenSigStartValueInteger" SG_ 1445 SOBDMC_AutoSarNMReserved3 255;
BA_ "ContentDependant" SG_ 1445 SOBDMC_AutoSarNMReserved3 1;
BA_ "GenSigStartValue" SG_ 1445 SOBDMC_AutoSarNMReserved3 255;
BA_ "U_CX727_MY2021_Rx" SG_ 1445 SOBDMC_AutoSarNMReserved3 1;
BA_ "U_CD542_MY2021_Rx" SG_ 1445 SOBDMC_AutoSarNMReserved3 1;
BA_ "U_CX727_MY2021_Tx" SG_ 1445 SOBDMC_AutoSarNMReserved3 1;
BA_ "U_P702_MY2021_Tx" SG_ 1445 SOBDMC_AutoSarNMReserved3 1;
BA_ "U_CD542_MY2021_Tx" SG_ 1445 SOBDMC_AutoSarNMReserved3 1;
BA_ "GenSigStartValueInteger" SG_ 1445 SOBDMC_AutoSarNMReserved2 255;
BA_ "ContentDependant" SG_ 1445 SOBDMC_AutoSarNMReserved2 1;
BA_ "GenSigStartValue" SG_ 1445 SOBDMC_AutoSarNMReserved2 255;
BA_ "U_CX727_MY2021_Rx" SG_ 1445 SOBDMC_AutoSarNMReserved2 1;
BA_ "U_CD542_MY2021_Rx" SG_ 1445 SOBDMC_AutoSarNMReserved2 1;
BA_ "U_CX727_MY2021_Tx" SG_ 1445 SOBDMC_AutoSarNMReserved2 1;
BA_ "U_P702_MY2021_Tx" SG_ 1445 SOBDMC_AutoSarNMReserved2 1;
BA_ "U_CD542_MY2021_Tx" SG_ 1445 SOBDMC_AutoSarNMReserved2 1;
BA_ "GenSigStartValueInteger" SG_ 1445 SOBDMC_AutoSarNMReserved1 255;
BA_ "ContentDependant" SG_ 1445 SOBDMC_AutoSarNMReserved1 1;
BA_ "GenSigStartValue" SG_ 1445 SOBDMC_AutoSarNMReserved1 255;
BA_ "U_CX727_MY2021_Rx" SG_ 1445 SOBDMC_AutoSarNMReserved1 1;
BA_ "U_CD542_MY2021_Rx" SG_ 1445 SOBDMC_AutoSarNMReserved1 1;
BA_ "U_CX727_MY2021_Tx" SG_ 1445 SOBDMC_AutoSarNMReserved1 1;
BA_ "U_P702_MY2021_Tx" SG_ 1445 SOBDMC_AutoSarNMReserved1 1;
BA_ "U_CD542_MY2021_Tx" SG_ 1445 SOBDMC_AutoSarNMReserved1 1;
BA_ "GenSigStartValueInteger" SG_ 1445 SOBDMC_AutoSarNMNodeId 165;
BA_ "ContentDependant" SG_ 1445 SOBDMC_AutoSarNMNodeId 1;
BA_ "GenSigStartValue" SG_ 1445 SOBDMC_AutoSarNMNodeId 165;
BA_ "U_CX727_MY2021_Rx" SG_ 1445 SOBDMC_AutoSarNMNodeId 1;
BA_ "U_CD542_MY2021_Rx" SG_ 1445 SOBDMC_AutoSarNMNodeId 1;
BA_ "U_CX727_MY2021_Tx" SG_ 1445 SOBDMC_AutoSarNMNodeId 1;
BA_ "U_P702_MY2021_Tx" SG_ 1445 SOBDMC_AutoSarNMNodeId 1;
BA_ "U_CD542_MY2021_Tx" SG_ 1445 SOBDMC_AutoSarNMNodeId 1;
BA_ "ContentDependant" SG_ 1445 SOBDMC_AutoSarNMControl 1;
BA_ "U_CX727_MY2021_Rx" SG_ 1445 SOBDMC_AutoSarNMControl 1;
BA_ "U_CD542_MY2021_Rx" SG_ 1445 SOBDMC_AutoSarNMControl 1;
BA_ "U_CX727_MY2021_Tx" SG_ 1445 SOBDMC_AutoSarNMControl 1;
BA_ "U_P702_MY2021_Tx" SG_ 1445 SOBDMC_AutoSarNMControl 1;
BA_ "U_CD542_MY2021_Tx" SG_ 1445 SOBDMC_AutoSarNMControl 1;
BA_ "GenSigStartValueInteger" SG_ 1445 SOBDMC_GWOnBoardTester 255;
BA_ "ContentDependant" SG_ 1445 SOBDMC_GWOnBoardTester 1;
BA_ "GenSigStartValue" SG_ 1445 SOBDMC_GWOnBoardTester 255;
BA_ "U_CX727_MY2021_Rx" SG_ 1445 SOBDMC_GWOnBoardTester 1;
BA_ "U_CD542_MY2021_Rx" SG_ 1445 SOBDMC_GWOnBoardTester 1;
BA_ "U_CX727_MY2021_Tx" SG_ 1445 SOBDMC_GWOnBoardTester 1;
BA_ "U_P702_MY2021_Tx" SG_ 1445 SOBDMC_GWOnBoardTester 1;
BA_ "U_CD542_MY2021_Tx" SG_ 1445 SOBDMC_GWOnBoardTester 1;
BA_ "GenSigStartValueInteger" SG_ 1445 SOBDMC_GWNMProxy 255;
BA_ "ContentDependant" SG_ 1445 SOBDMC_GWNMProxy 1;
BA_ "GenSigStartValue" SG_ 1445 SOBDMC_GWNMProxy 255;
BA_ "U_CX727_MY2021_Rx" SG_ 1445 SOBDMC_GWNMProxy 1;
BA_ "U_CD542_MY2021_Rx" SG_ 1445 SOBDMC_GWNMProxy 1;
BA_ "U_CX727_MY2021_Tx" SG_ 1445 SOBDMC_GWNMProxy 1;
BA_ "U_P702_MY2021_Tx" SG_ 1445 SOBDMC_GWNMProxy 1;
BA_ "U_CD542_MY2021_Tx" SG_ 1445 SOBDMC_GWNMProxy 1;
BA_ "U_CX727_MY2021_Tx" SG_ 1143 EffAvgChrg_Pc_Dsply 1;
BA_ "U_CD542_MY2021_Tx" SG_ 1143 EffAvgChrg_Pc_Dsply 1;
BA_ "ECGUsedRxSignal" SG_ 1143 ConsTipUnitPt_D_Dsply 1;
BA_ "U_CD542_MY2021_Rx" SG_ 1143 ConsTipUnitPt_D_Dsply 1;
BA_ "U_U55X_MY2022_Rx" SG_ 1143 ConsTipUnitPt_D_Dsply 1;
BA_ "U_CX727_MY2021_Tx" SG_ 1143 ConsTipUnitPt_D_Dsply 1;
BA_ "U_CD542_MY2021_Tx" SG_ 1143 ConsTipUnitPt_D_Dsply 1;
BA_ "GenSigStartValueInteger" SG_ 1143 ConsTipTot_Pc_Dsply 1022;
BA_ "GenSigStartValue" SG_ 1143 ConsTipTot_Pc_Dsply 1022;
BA_ "ECGUsedRxSignal" SG_ 1143 ConsTipTot_Pc_Dsply 1;
BA_ "U_CD542_MY2021_Rx" SG_ 1143 ConsTipTot_Pc_Dsply 1;
BA_ "U_U55X_MY2022_Rx" SG_ 1143 ConsTipTot_Pc_Dsply 1;
BA_ "U_CX727_MY2021_Tx" SG_ 1143 ConsTipTot_Pc_Dsply 1;
BA_ "U_CD542_MY2021_Tx" SG_ 1143 ConsTipTot_Pc_Dsply 1;
BA_ "U_CX727_MY2021_Tx" SG_ 1143 ChrgCompltMsgTxt_D_Rq 1;
BA_ "U_CD542_MY2021_Tx" SG_ 1143 ChrgCompltMsgTxt_D_Rq 1;
BA_ "ECGUsedRxSignal" SG_ 1142 ConsTipV_No_Dsply 1;
BA_ "U_CD542_MY2021_Rx" SG_ 1142 ConsTipV_No_Dsply 1;
BA_ "U_U55X_MY2022_Rx" SG_ 1142 ConsTipV_No_Dsply 1;
BA_ "U_CX727_MY2021_Tx" SG_ 1142 ConsTipV_No_Dsply 1;
BA_ "U_CD542_MY2021_Tx" SG_ 1142 ConsTipV_No_Dsply 1;
BA_ "U_CX727_MY2021_Tx" SG_ 1142 ConsTipMsg3_D_Dsply 1;
BA_ "U_CD542_MY2021_Tx" SG_ 1142 ConsTipMsg3_D_Dsply 1;
BA_ "U_CX727_MY2021_Tx" SG_ 1142 ConsTipMsg2_D_Dsply 1;
BA_ "U_CD542_MY2021_Tx" SG_ 1142 ConsTipMsg2_D_Dsply 1;
BA_ "U_CX727_MY2021_Tx" SG_ 1142 ConsTipMsg1_D_Dsply 1;
BA_ "U_CD542_MY2021_Tx" SG_ 1142 ConsTipMsg1_D_Dsply 1;
BA_ "ECGUsedRxSignal" SG_ 1142 ConsTipDecel_No_Dsply 1;
BA_ "U_CD542_MY2021_Rx" SG_ 1142 ConsTipDecel_No_Dsply 1;
BA_ "U_U55X_MY2022_Rx" SG_ 1142 ConsTipDecel_No_Dsply 1;
BA_ "U_CX727_MY2021_Tx" SG_ 1142 ConsTipDecel_No_Dsply 1;
BA_ "U_CD542_MY2021_Tx" SG_ 1142 ConsTipDecel_No_Dsply 1;
BA_ "ECGUsedRxSignal" SG_ 1142 ConsTipA_No_Dsply 1;
BA_ "U_CD542_MY2021_Rx" SG_ 1142 ConsTipA_No_Dsply 1;
BA_ "U_U55X_MY2022_Rx" SG_ 1142 ConsTipA_No_Dsply 1;
BA_ "U_CX727_MY2021_Tx" SG_ 1142 ConsTipA_No_Dsply 1;
BA_ "U_CD542_MY2021_Tx" SG_ 1142 ConsTipA_No_Dsply 1;
BA_ "GenSigStartValue" SG_ 1141 WhlPwRear_Pc_Dsply 511;
BA_ "GenSigStartValue" SG_ 1141 WhlPwFront_Pc_Dsply 511;
BA_ "U_CX727_MY2021_Tx" SG_ 1141 AirAmbTePlgIn_D_Dsply 1;
BA_ "U_CD542_MY2021_Tx" SG_ 1141 AirAmbTePlgIn_D_Dsply 1;
BA_ "ECGUsedRxSignal" SG_ 1141 OfbChrgSetSync_D_Stat 1;
BA_ "U_CD542_MY2021_Rx" SG_ 1141 OfbChrgSetSync_D_Stat 1;
BA_ "U_U55X_MY2022_Rx" SG_ 1141 OfbChrgSetSync_D_Stat 1;
BA_ "U_CX727_MY2021_Tx" SG_ 1141 OfbChrgSetSync_D_Stat 1;
BA_ "U_CD542_MY2021_Tx" SG_ 1141 OfbChrgSetSync_D_Stat 1;
BA_ "GenSigStartValueInteger" SG_ 1141 MtrTrac2_Tq_Actl 4095;
BA_ "GenSigStartValue" SG_ 1141 MtrTrac2_Tq_Actl 4095;
BA_ "ECGUsedRxSignal" SG_ 1141 MtrTrac2_Tq_Actl 1;
BA_ "U_CD542_MY2021_Rx" SG_ 1141 MtrTrac2_Tq_Actl 1;
BA_ "U_U55X_MY2022_Rx" SG_ 1141 MtrTrac2_Tq_Actl 1;
BA_ "U_CX727_MY2021_Tx" SG_ 1141 MtrTrac2_Tq_Actl 1;
BA_ "U_P702_MY2021_Tx" SG_ 1141 MtrTrac2_Tq_Actl 1;
BA_ "U_CD542_MY2021_Tx" SG_ 1141 MtrTrac2_Tq_Actl 1;
BA_ "WakeupSignal" SG_ 1141 PtRmtRprt_D_Rq 1;
BA_ "ECGUsedRxSignal" SG_ 1141 PtRmtRprt_D_Rq 1;
BA_ "U_CD542_MY2021_Rx" SG_ 1141 PtRmtRprt_D_Rq 1;
BA_ "U_U55X_MY2022_Rx" SG_ 1141 PtRmtRprt_D_Rq 1;
BA_ "U_CX727_MY2021_Tx" SG_ 1141 PtRmtRprt_D_Rq 1;
BA_ "U_CD542_MY2021_Tx" SG_ 1141 PtRmtRprt_D_Rq 1;
BA_ "U_CX727_MY2021_Tx" SG_ 1141 PreCondID_No_Rq 1;
BA_ "U_CD542_MY2021_Tx" SG_ 1141 PreCondID_No_Rq 1;
BA_ "U_CX727_MY2021_Tx" SG_ 1141 NxtUsg_D_Rq 1;
BA_ "U_CD542_MY2021_Tx" SG_ 1141 NxtUsg_D_Rq 1;
BA_ "ECGUsedRxSignal" SG_ 1141 NtfctnConflict1_D_Rq 1;
BA_ "U_CD542_MY2021_Rx" SG_ 1141 NtfctnConflict1_D_Rq 1;
BA_ "U_U55X_MY2022_Rx" SG_ 1141 NtfctnConflict1_D_Rq 1;
BA_ "U_CX727_MY2021_Tx" SG_ 1141 NtfctnConflict1_D_Rq 1;
BA_ "U_P702_MY2021_Tx" SG_ 1141 NtfctnConflict1_D_Rq 1;
BA_ "U_CD542_MY2021_Tx" SG_ 1141 NtfctnConflict1_D_Rq 1;
BA_ "ECGUsedRxSignal" SG_ 1141 ChrgLocID_No_Rq 1;
BA_ "U_CD542_MY2021_Rx" SG_ 1141 ChrgLocID_No_Rq 1;
BA_ "U_U55X_MY2022_Rx" SG_ 1141 ChrgLocID_No_Rq 1;
BA_ "U_CX727_MY2021_Tx" SG_ 1141 ChrgLocID_No_Rq 1;
BA_ "U_CD542_MY2021_Tx" SG_ 1141 ChrgLocID_No_Rq 1;
BA_ "U_CX727_MY2021_Tx" SG_ 1141 ChrgLocGPS_D_Rq 1;
BA_ "U_CD542_MY2021_Tx" SG_ 1141 ChrgLocGPS_D_Rq 1;
BA_ "ECGUsedRxSignal" SG_ 1140 RgenLongTerm_L_Dsply 1;
BA_ "U_CD542_MY2021_Rx" SG_ 1140 RgenLongTerm_L_Dsply 1;
BA_ "U_U55X_MY2022_Rx" SG_ 1140 RgenLongTerm_L_Dsply 1;
BA_ "U_CX727_MY2021_Tx" SG_ 1140 RgenLongTerm_L_Dsply 1;
BA_ "U_CD542_MY2021_Tx" SG_ 1140 RgenLongTerm_L_Dsply 1;
BA_ "ECGUsedRxSignal" SG_ 1140 PreCondStat_D_Dsply 1;
BA_ "U_CD542_MY2021_Rx" SG_ 1140 PreCondStat_D_Dsply 1;
BA_ "U_U55X_MY2022_Rx" SG_ 1140 PreCondStat_D_Dsply 1;
BA_ "U_CX727_MY2021_Tx" SG_ 1140 PreCondStat_D_Dsply 1;
BA_ "U_P702_MY2021_Tx" SG_ 1140 PreCondStat_D_Dsply 1;
BA_ "U_CD542_MY2021_Tx" SG_ 1140 PreCondStat_D_Dsply 1;
BA_ "ECGUsedRxSignal" SG_ 1140 RgenLongTerm_Pc_Dsply 1;
BA_ "U_CD542_MY2021_Rx" SG_ 1140 RgenLongTerm_Pc_Dsply 1;
BA_ "U_U55X_MY2022_Rx" SG_ 1140 RgenLongTerm_Pc_Dsply 1;
BA_ "U_CX727_MY2021_Tx" SG_ 1140 RgenLongTerm_Pc_Dsply 1;
BA_ "U_CD542_MY2021_Tx" SG_ 1140 RgenLongTerm_Pc_Dsply 1;
BA_ "GenSigStartValueInteger" SG_ 1140 RgenEvntLvl_Pc_Dsply 1023;
BA_ "GenSigStartValue" SG_ 1140 RgenEvntLvl_Pc_Dsply 1022;
BA_ "U_CX727_MY2021_Tx" SG_ 1140 RgenEvntLvl_Pc_Dsply 1;
BA_ "U_CD542_MY2021_Tx" SG_ 1140 RgenEvntLvl_Pc_Dsply 1;
BA_ "U_CX727_MY2021_Tx" SG_ 1140 BrkEvntComplt_B_Dsply 1;
BA_ "U_CD542_MY2021_Tx" SG_ 1140 BrkEvntComplt_B_Dsply 1;
BA_ "U_CX727_MY2021_Tx" SG_ 1140 ExtChrgrFalt_B_Dsply 1;
BA_ "U_CD542_MY2021_Tx" SG_ 1140 ExtChrgrFalt_B_Dsply 1;
BA_ "U_CX727_MY2021_Tx" SG_ 1139 BattChrgTrgtLMax_T_Est 1;
BA_ "U_P702_MY2021_Tx" SG_ 1139 BattChrgTrgtLMax_T_Est 1;
BA_ "U_CD542_MY2021_Tx" SG_ 1139 BattChrgTrgtLMax_T_Est 1;
BA_ "ECGUsedRxSignal" SG_ 1139 ActChrgStrtYr_No_Actl 1;
BA_ "U_CD542_MY2021_Rx" SG_ 1139 ActChrgStrtYr_No_Actl 1;
BA_ "U_U55X_MY2022_Rx" SG_ 1139 ActChrgStrtYr_No_Actl 1;
BA_ "U_CX727_MY2021_Tx" SG_ 1139 ActChrgStrtYr_No_Actl 1;
BA_ "U_P702_MY2021_Tx" SG_ 1139 ActChrgStrtYr_No_Actl 1;
BA_ "U_CD542_MY2021_Tx" SG_ 1139 ActChrgStrtYr_No_Actl 1;
BA_ "ECGUsedRxSignal" SG_ 1139 ActChrgStrtMin_No_Actl 1;
BA_ "U_CD542_MY2021_Rx" SG_ 1139 ActChrgStrtMin_No_Actl 1;
BA_ "U_U55X_MY2022_Rx" SG_ 1139 ActChrgStrtMin_No_Actl 1;
BA_ "U_CX727_MY2021_Tx" SG_ 1139 ActChrgStrtMin_No_Actl 1;
BA_ "U_P702_MY2021_Tx" SG_ 1139 ActChrgStrtMin_No_Actl 1;
BA_ "U_CD542_MY2021_Tx" SG_ 1139 ActChrgStrtMin_No_Actl 1;
BA_ "ECGUsedRxSignal" SG_ 1139 ActChrgStrtHr_No_Actl 1;
BA_ "U_CD542_MY2021_Rx" SG_ 1139 ActChrgStrtHr_No_Actl 1;
BA_ "U_U55X_MY2022_Rx" SG_ 1139 ActChrgStrtHr_No_Actl 1;
BA_ "U_CX727_MY2021_Tx" SG_ 1139 ActChrgStrtHr_No_Actl 1;
BA_ "U_P702_MY2021_Tx" SG_ 1139 ActChrgStrtHr_No_Actl 1;
BA_ "U_CD542_MY2021_Tx" SG_ 1139 ActChrgStrtHr_No_Actl 1;
BA_ "GenSigStartValueInteger" SG_ 1139 ActChrgStrtDay_No_Actl 1;
BA_ "GenSigStartValue" SG_ 1139 ActChrgStrtDay_No_Actl 1;
BA_ "ECGUsedRxSignal" SG_ 1139 ActChrgStrtDay_No_Actl 1;
BA_ "U_CD542_MY2021_Rx" SG_ 1139 ActChrgStrtDay_No_Actl 1;
BA_ "U_U55X_MY2022_Rx" SG_ 1139 ActChrgStrtDay_No_Actl 1;
BA_ "U_CX727_MY2021_Tx" SG_ 1139 ActChrgStrtDay_No_Actl 1;
BA_ "U_P702_MY2021_Tx" SG_ 1139 ActChrgStrtDay_No_Actl 1;
BA_ "U_CD542_MY2021_Tx" SG_ 1139 ActChrgStrtDay_No_Actl 1;
BA_ "GenSigStartValueInteger" SG_ 1139 ActChrgStrMnth_No_Actl 1;
BA_ "GenSigStartValue" SG_ 1139 ActChrgStrMnth_No_Actl 1;
BA_ "ECGUsedRxSignal" SG_ 1139 ActChrgStrMnth_No_Actl 1;
BA_ "U_CD542_MY2021_Rx" SG_ 1139 ActChrgStrMnth_No_Actl 1;
BA_ "U_U55X_MY2022_Rx" SG_ 1139 ActChrgStrMnth_No_Actl 1;
BA_ "U_CX727_MY2021_Tx" SG_ 1139 ActChrgStrMnth_No_Actl 1;
BA_ "U_P702_MY2021_Tx" SG_ 1139 ActChrgStrMnth_No_Actl 1;
BA_ "U_CD542_MY2021_Tx" SG_ 1139 ActChrgStrMnth_No_Actl 1;
BA_ "ECGUsedRxSignal" SG_ 1139 ActChrgStrtYr_No2_Actl 1;
BA_ "U_CD542_MY2021_Rx" SG_ 1139 ActChrgStrtYr_No2_Actl 1;
BA_ "U_U55X_MY2022_Rx" SG_ 1139 ActChrgStrtYr_No2_Actl 1;
BA_ "U_CX727_MY2021_Tx" SG_ 1139 ActChrgStrtYr_No2_Actl 1;
BA_ "U_CD542_MY2021_Tx" SG_ 1139 ActChrgStrtYr_No2_Actl 1;
BA_ "U_CX727_MY2021_Tx" SG_ 1138 BattChrgTrgtLMin_T_Est 1;
BA_ "U_P702_MY2021_Tx" SG_ 1138 BattChrgTrgtLMin_T_Est 1;
BA_ "U_CD542_MY2021_Tx" SG_ 1138 BattChrgTrgtLMin_T_Est 1;
BA_ "ECGUsedRxSignal" SG_ 1138 ActChrgEndYr_No_Actl 1;
BA_ "U_CD542_MY2021_Rx" SG_ 1138 ActChrgEndYr_No_Actl 1;
BA_ "U_U55X_MY2022_Rx" SG_ 1138 ActChrgEndYr_No_Actl 1;
BA_ "U_CX727_MY2021_Tx" SG_ 1138 ActChrgEndYr_No_Actl 1;
BA_ "U_P702_MY2021_Tx" SG_ 1138 ActChrgEndYr_No_Actl 1;
BA_ "U_CD542_MY2021_Tx" SG_ 1138 ActChrgEndYr_No_Actl 1;
BA_ "GenSigStartValueInteger" SG_ 1138 ActChrgEndMnth_No_Actl 1;
BA_ "GenSigStartValue" SG_ 1138 ActChrgEndMnth_No_Actl 1;
BA_ "ECGUsedRxSignal" SG_ 1138 ActChrgEndMnth_No_Actl 1;
BA_ "U_CD542_MY2021_Rx" SG_ 1138 ActChrgEndMnth_No_Actl 1;
BA_ "U_U55X_MY2022_Rx" SG_ 1138 ActChrgEndMnth_No_Actl 1;
BA_ "U_CX727_MY2021_Tx" SG_ 1138 ActChrgEndMnth_No_Actl 1;
BA_ "U_P702_MY2021_Tx" SG_ 1138 ActChrgEndMnth_No_Actl 1;
BA_ "U_CD542_MY2021_Tx" SG_ 1138 ActChrgEndMnth_No_Actl 1;
BA_ "ECGUsedRxSignal" SG_ 1138 ActChrgEndMin_No_Actl 1;
BA_ "U_CD542_MY2021_Rx" SG_ 1138 ActChrgEndMin_No_Actl 1;
BA_ "U_U55X_MY2022_Rx" SG_ 1138 ActChrgEndMin_No_Actl 1;
BA_ "U_CX727_MY2021_Tx" SG_ 1138 ActChrgEndMin_No_Actl 1;
BA_ "U_P702_MY2021_Tx" SG_ 1138 ActChrgEndMin_No_Actl 1;
BA_ "U_CD542_MY2021_Tx" SG_ 1138 ActChrgEndMin_No_Actl 1;
BA_ "ECGUsedRxSignal" SG_ 1138 ActChrgEndHr_No_Actl 1;
BA_ "U_CD542_MY2021_Rx" SG_ 1138 ActChrgEndHr_No_Actl 1;
BA_ "U_U55X_MY2022_Rx" SG_ 1138 ActChrgEndHr_No_Actl 1;
BA_ "U_CX727_MY2021_Tx" SG_ 1138 ActChrgEndHr_No_Actl 1;
BA_ "U_P702_MY2021_Tx" SG_ 1138 ActChrgEndHr_No_Actl 1;
BA_ "U_CD542_MY2021_Tx" SG_ 1138 ActChrgEndHr_No_Actl 1;
BA_ "GenSigStartValueInteger" SG_ 1138 ActChrgEndDay_No_Actl 1;
BA_ "GenSigStartValue" SG_ 1138 ActChrgEndDay_No_Actl 1;
BA_ "ECGUsedRxSignal" SG_ 1138 ActChrgEndDay_No_Actl 1;
BA_ "U_CD542_MY2021_Rx" SG_ 1138 ActChrgEndDay_No_Actl 1;
BA_ "U_U55X_MY2022_Rx" SG_ 1138 ActChrgEndDay_No_Actl 1;
BA_ "U_CX727_MY2021_Tx" SG_ 1138 ActChrgEndDay_No_Actl 1;
BA_ "U_P702_MY2021_Tx" SG_ 1138 ActChrgEndDay_No_Actl 1;
BA_ "U_CD542_MY2021_Tx" SG_ 1138 ActChrgEndDay_No_Actl 1;
BA_ "ECGUsedRxSignal" SG_ 1138 ActChrgEndYr_No2_Actl 1;
BA_ "U_CD542_MY2021_Rx" SG_ 1138 ActChrgEndYr_No2_Actl 1;
BA_ "U_U55X_MY2022_Rx" SG_ 1138 ActChrgEndYr_No2_Actl 1;
BA_ "U_CX727_MY2021_Tx" SG_ 1138 ActChrgEndYr_No2_Actl 1;
BA_ "U_CD542_MY2021_Tx" SG_ 1138 ActChrgEndYr_No2_Actl 1;
BA_ "GenSigSendType" SG_ 1016 ChrgGoTElement_B_Dsply 3;
BA_ "ECGUsedRxSignal" SG_ 1016 ChrgGoTElement_B_Dsply 1;
BA_ "U_CD542_MY2021_Rx" SG_ 1016 ChrgGoTElement_B_Dsply 1;
BA_ "U_U55X_MY2022_Rx" SG_ 1016 ChrgGoTElement_B_Dsply 1;
BA_ "U_CX727_MY2021_Tx" SG_ 1016 ChrgGoTElement_B_Dsply 1;
BA_ "U_CD542_MY2021_Tx" SG_ 1016 ChrgGoTElement_B_Dsply 1;
BA_ "GenSigSendType" SG_ 1016 ChrgLocIdCurnt_D_Uns 3;
BA_ "ECGUsedRxSignal" SG_ 1016 ChrgLocIdCurnt_D_Uns 1;
BA_ "U_CD542_MY2021_Rx" SG_ 1016 ChrgLocIdCurnt_D_Uns 1;
BA_ "U_U55X_MY2022_Rx" SG_ 1016 ChrgLocIdCurnt_D_Uns 1;
BA_ "U_CX727_MY2021_Tx" SG_ 1016 ChrgLocIdCurnt_D_Uns 1;
BA_ "U_P702_MY2021_Tx" SG_ 1016 ChrgLocIdCurnt_D_Uns 1;
BA_ "U_CD542_MY2021_Tx" SG_ 1016 ChrgLocIdCurnt_D_Uns 1;
BA_ "GenSigSendType" SG_ 1016 ChrgGoTTouchEnbl_B_Rq 3;
BA_ "U_CX727_MY2021_Tx" SG_ 1016 ChrgGoTTouchEnbl_B_Rq 1;
BA_ "U_P702_MY2021_Tx" SG_ 1016 ChrgGoTTouchEnbl_B_Rq 1;
BA_ "U_CD542_MY2021_Tx" SG_ 1016 ChrgGoTTouchEnbl_B_Rq 1;
BA_ "GenSigSendType" SG_ 1016 ChrgGoTTouch_B_Stat 3;
BA_ "ECGUsedRxSignal" SG_ 1016 ChrgGoTTouch_B_Stat 1;
BA_ "U_CD542_MY2021_Rx" SG_ 1016 ChrgGoTTouch_B_Stat 1;
BA_ "U_U55X_MY2022_Rx" SG_ 1016 ChrgGoTTouch_B_Stat 1;
BA_ "U_CX727_MY2021_Tx" SG_ 1016 ChrgGoTTouch_B_Stat 1;
BA_ "U_P702_MY2021_Tx" SG_ 1016 ChrgGoTTouch_B_Stat 1;
BA_ "U_CD542_MY2021_Tx" SG_ 1016 ChrgGoTTouch_B_Stat 1;
BA_ "ECGUsedRxSignal" SG_ 1016 ChrgGoTPrcond_D_Stat 1;
BA_ "U_CD542_MY2021_Rx" SG_ 1016 ChrgGoTPrcond_D_Stat 1;
BA_ "U_U55X_MY2022_Rx" SG_ 1016 ChrgGoTPrcond_D_Stat 1;
BA_ "U_CX727_MY2021_Tx" SG_ 1016 ChrgGoTPrcond_D_Stat 1;
BA_ "U_P702_MY2021_Tx" SG_ 1016 ChrgGoTPrcond_D_Stat 1;
BA_ "U_CD542_MY2021_Tx" SG_ 1016 ChrgGoTPrcond_D_Stat 1;
BA_ "GenSigSendType" SG_ 1016 ChrgGoTNext_D_Stat 3;
BA_ "ECGUsedRxSignal" SG_ 1016 ChrgGoTNext_D_Stat 1;
BA_ "U_CD542_MY2021_Rx" SG_ 1016 ChrgGoTNext_D_Stat 1;
BA_ "U_U55X_MY2022_Rx" SG_ 1016 ChrgGoTNext_D_Stat 1;
BA_ "U_CX727_MY2021_Tx" SG_ 1016 ChrgGoTNext_D_Stat 1;
BA_ "U_P702_MY2021_Tx" SG_ 1016 ChrgGoTNext_D_Stat 1;
BA_ "U_CD542_MY2021_Tx" SG_ 1016 ChrgGoTNext_D_Stat 1;
BA_ "ECGUsedRxSignal" SG_ 1016 ChrgGoTMnte_D_Stat 1;
BA_ "U_CD542_MY2021_Rx" SG_ 1016 ChrgGoTMnte_D_Stat 1;
BA_ "U_U55X_MY2022_Rx" SG_ 1016 ChrgGoTMnte_D_Stat 1;
BA_ "U_CX727_MY2021_Tx" SG_ 1016 ChrgGoTMnte_D_Stat 1;
BA_ "U_P702_MY2021_Tx" SG_ 1016 ChrgGoTMnte_D_Stat 1;
BA_ "U_CD542_MY2021_Tx" SG_ 1016 ChrgGoTMnte_D_Stat 1;
BA_ "GenSigStartValueInteger" SG_ 1016 ChrgGoTHr_T_Stat 30;
BA_ "GenSigStartValue" SG_ 1016 ChrgGoTHr_T_Stat 30;
BA_ "ECGUsedRxSignal" SG_ 1016 ChrgGoTHr_T_Stat 1;
BA_ "U_CD542_MY2021_Rx" SG_ 1016 ChrgGoTHr_T_Stat 1;
BA_ "U_U55X_MY2022_Rx" SG_ 1016 ChrgGoTHr_T_Stat 1;
BA_ "U_CX727_MY2021_Tx" SG_ 1016 ChrgGoTHr_T_Stat 1;
BA_ "U_P702_MY2021_Tx" SG_ 1016 ChrgGoTHr_T_Stat 1;
BA_ "U_CD542_MY2021_Tx" SG_ 1016 ChrgGoTHr_T_Stat 1;
BA_ "GenSigSendType" SG_ 1016 ChrgGoTExtHtrEnbl_B_Rq 3;
BA_ "U_CX727_MY2021_Tx" SG_ 1016 ChrgGoTExtHtrEnbl_B_Rq 1;
BA_ "U_P702_MY2021_Tx" SG_ 1016 ChrgGoTExtHtrEnbl_B_Rq 1;
BA_ "U_CD542_MY2021_Tx" SG_ 1016 ChrgGoTExtHtrEnbl_B_Rq 1;
BA_ "GenSigSendType" SG_ 1016 ChrgGoTExtHtr_B_Stat 3;
BA_ "ECGUsedRxSignal" SG_ 1016 ChrgGoTExtHtr_B_Stat 1;
BA_ "U_CD542_MY2021_Rx" SG_ 1016 ChrgGoTExtHtr_B_Stat 1;
BA_ "U_U55X_MY2022_Rx" SG_ 1016 ChrgGoTExtHtr_B_Stat 1;
BA_ "U_CX727_MY2021_Tx" SG_ 1016 ChrgGoTExtHtr_B_Stat 1;
BA_ "U_P702_MY2021_Tx" SG_ 1016 ChrgGoTExtHtr_B_Stat 1;
BA_ "U_CD542_MY2021_Tx" SG_ 1016 ChrgGoTExtHtr_B_Stat 1;
BA_ "GenSigSendType" SG_ 1016 ChrgGoTElement_D_Stat 3;
BA_ "ECGUsedRxSignal" SG_ 1016 ChrgGoTElement_D_Stat 1;
BA_ "U_CD542_MY2021_Rx" SG_ 1016 ChrgGoTElement_D_Stat 1;
BA_ "U_U55X_MY2022_Rx" SG_ 1016 ChrgGoTElement_D_Stat 1;
BA_ "U_CX727_MY2021_Tx" SG_ 1016 ChrgGoTElement_D_Stat 1;
BA_ "U_P702_MY2021_Tx" SG_ 1016 ChrgGoTElement_D_Stat 1;
BA_ "U_CD542_MY2021_Tx" SG_ 1016 ChrgGoTElement_D_Stat 1;
BA_ "GenSigSendType" SG_ 1016 ChrgGoTAllOn_B_Stat 3;
BA_ "ECGUsedRxSignal" SG_ 1016 ChrgGoTAllOn_B_Stat 1;
BA_ "U_CD542_MY2021_Rx" SG_ 1016 ChrgGoTAllOn_B_Stat 1;
BA_ "U_U55X_MY2022_Rx" SG_ 1016 ChrgGoTAllOn_B_Stat 1;
BA_ "U_CX727_MY2021_Tx" SG_ 1016 ChrgGoTAllOn_B_Stat 1;
BA_ "U_P702_MY2021_Tx" SG_ 1016 ChrgGoTAllOn_B_Stat 1;
BA_ "U_CD542_MY2021_Tx" SG_ 1016 ChrgGoTAllOn_B_Stat 1;
BA_ "ECGUsedRxSignal" SG_ 1013 ChrgToPcWkndSav_D_Stat 1;
BA_ "U_CD542_MY2021_Rx" SG_ 1013 ChrgToPcWkndSav_D_Stat 1;
BA_ "U_U55X_MY2022_Rx" SG_ 1013 ChrgToPcWkndSav_D_Stat 1;
BA_ "U_CX727_MY2021_Tx" SG_ 1013 ChrgToPcWkndSav_D_Stat 1;
BA_ "U_P702_MY2021_Tx" SG_ 1013 ChrgToPcWkndSav_D_Stat 1;
BA_ "U_CD542_MY2021_Tx" SG_ 1013 ChrgToPcWkndSav_D_Stat 1;
BA_ "ECGUsedRxSignal" SG_ 1013 ChrgToPcWkdySav_D_Stat 1;
BA_ "U_CD542_MY2021_Rx" SG_ 1013 ChrgToPcWkdySav_D_Stat 1;
BA_ "U_U55X_MY2022_Rx" SG_ 1013 ChrgToPcWkdySav_D_Stat 1;
BA_ "U_CX727_MY2021_Tx" SG_ 1013 ChrgToPcWkdySav_D_Stat 1;
BA_ "U_P702_MY2021_Tx" SG_ 1013 ChrgToPcWkdySav_D_Stat 1;
BA_ "U_CD542_MY2021_Tx" SG_ 1013 ChrgToPcWkdySav_D_Stat 1;
BA_ "GenSigSendType" SG_ 1013 ChrgProgIdSaved_D_Stat 3;
BA_ "ECGUsedRxSignal" SG_ 1013 ChrgProgIdSaved_D_Stat 1;
BA_ "U_CD542_MY2021_Rx" SG_ 1013 ChrgProgIdSaved_D_Stat 1;
BA_ "U_U55X_MY2022_Rx" SG_ 1013 ChrgProgIdSaved_D_Stat 1;
BA_ "U_CX727_MY2021_Tx" SG_ 1013 ChrgProgIdSaved_D_Stat 1;
BA_ "U_P702_MY2021_Tx" SG_ 1013 ChrgProgIdSaved_D_Stat 1;
BA_ "U_CD542_MY2021_Tx" SG_ 1013 ChrgProgIdSaved_D_Stat 1;
BA_ "ECGUsedRxSignal" SG_ 1013 ChrgNowEnbl_B_Saved 1;
BA_ "U_CD542_MY2021_Rx" SG_ 1013 ChrgNowEnbl_B_Saved 1;
BA_ "U_U55X_MY2022_Rx" SG_ 1013 ChrgNowEnbl_B_Saved 1;
BA_ "U_CX727_MY2021_Tx" SG_ 1013 ChrgNowEnbl_B_Saved 1;
BA_ "U_P702_MY2021_Tx" SG_ 1013 ChrgNowEnbl_B_Saved 1;
BA_ "U_CD542_MY2021_Tx" SG_ 1013 ChrgNowEnbl_B_Saved 1;
BA_ "GenSigSendType" SG_ 1013 ChrgLocIdUnsAck_B_Stat 3;
BA_ "ECGUsedRxSignal" SG_ 1013 ChrgLocIdUnsAck_B_Stat 1;
BA_ "U_CD542_MY2021_Rx" SG_ 1013 ChrgLocIdUnsAck_B_Stat 1;
BA_ "U_U55X_MY2022_Rx" SG_ 1013 ChrgLocIdUnsAck_B_Stat 1;
BA_ "U_CX727_MY2021_Tx" SG_ 1013 ChrgLocIdUnsAck_B_Stat 1;
BA_ "U_P702_MY2021_Tx" SG_ 1013 ChrgLocIdUnsAck_B_Stat 1;
BA_ "U_CD542_MY2021_Tx" SG_ 1013 ChrgLocIdUnsAck_B_Stat 1;
BA_ "GenSigSendType" SG_ 1013 ChrgLocIdCurnt_D_Sav 3;
BA_ "ECGUsedRxSignal" SG_ 1013 ChrgLocIdCurnt_D_Sav 1;
BA_ "U_CD542_MY2021_Rx" SG_ 1013 ChrgLocIdCurnt_D_Sav 1;
BA_ "U_U55X_MY2022_Rx" SG_ 1013 ChrgLocIdCurnt_D_Sav 1;
BA_ "U_CX727_MY2021_Tx" SG_ 1013 ChrgLocIdCurnt_D_Sav 1;
BA_ "U_P702_MY2021_Tx" SG_ 1013 ChrgLocIdCurnt_D_Sav 1;
BA_ "U_CD542_MY2021_Tx" SG_ 1013 ChrgLocIdCurnt_D_Sav 1;
BA_ "ECGUsedRxSignal" SG_ 1013 ChrgPrflWknd_No_Actl 1;
BA_ "U_CD542_MY2021_Rx" SG_ 1013 ChrgPrflWknd_No_Actl 1;
BA_ "U_U55X_MY2022_Rx" SG_ 1013 ChrgPrflWknd_No_Actl 1;
BA_ "U_CX727_MY2021_Tx" SG_ 1013 ChrgPrflWknd_No_Actl 1;
BA_ "U_P702_MY2021_Tx" SG_ 1013 ChrgPrflWknd_No_Actl 1;
BA_ "U_CD542_MY2021_Tx" SG_ 1013 ChrgPrflWknd_No_Actl 1;
BA_ "ECGUsedRxSignal" SG_ 1013 ChrgPrflWkdy_No_Actl 1;
BA_ "U_CD542_MY2021_Rx" SG_ 1013 ChrgPrflWkdy_No_Actl 1;
BA_ "U_U55X_MY2022_Rx" SG_ 1013 ChrgPrflWkdy_No_Actl 1;
BA_ "U_CX727_MY2021_Tx" SG_ 1013 ChrgPrflWkdy_No_Actl 1;
BA_ "U_P702_MY2021_Tx" SG_ 1013 ChrgPrflWkdy_No_Actl 1;
BA_ "U_CD542_MY2021_Tx" SG_ 1013 ChrgPrflWkdy_No_Actl 1;
BA_ "GenSigSendType" SG_ 1012 ChrgLocSaved_B_Dsply 3;
BA_ "ECGUsedRxSignal" SG_ 1012 ChrgLocSaved_B_Dsply 1;
BA_ "U_CD542_MY2021_Rx" SG_ 1012 ChrgLocSaved_B_Dsply 1;
BA_ "U_U55X_MY2022_Rx" SG_ 1012 ChrgLocSaved_B_Dsply 1;
BA_ "U_CX727_MY2021_Tx" SG_ 1012 ChrgLocSaved_B_Dsply 1;
BA_ "U_P702_MY2021_Tx" SG_ 1012 ChrgLocSaved_B_Dsply 1;
BA_ "U_CD542_MY2021_Tx" SG_ 1012 ChrgLocSaved_B_Dsply 1;
BA_ "ECGUsedRxSignal" SG_ 1012 ChrgLocLongPostv_B_Sav 1;
BA_ "U_CD542_MY2021_Rx" SG_ 1012 ChrgLocLongPostv_B_Sav 1;
BA_ "U_U55X_MY2022_Rx" SG_ 1012 ChrgLocLongPostv_B_Sav 1;
BA_ "U_CX727_MY2021_Tx" SG_ 1012 ChrgLocLongPostv_B_Sav 1;
BA_ "U_P702_MY2021_Tx" SG_ 1012 ChrgLocLongPostv_B_Sav 1;
BA_ "U_CD542_MY2021_Tx" SG_ 1012 ChrgLocLongPostv_B_Sav 1;
BA_ "GenSigStartValueInteger" SG_ 1012 ChrgLocLongFrct_An_Sav 1048575;
BA_ "GenSigStartValue" SG_ 1012 ChrgLocLongFrct_An_Sav 1048575;
BA_ "ECGUsedRxSignal" SG_ 1012 ChrgLocLongFrct_An_Sav 1;
BA_ "U_CD542_MY2021_Rx" SG_ 1012 ChrgLocLongFrct_An_Sav 1;
BA_ "U_U55X_MY2022_Rx" SG_ 1012 ChrgLocLongFrct_An_Sav 1;
BA_ "U_CX727_MY2021_Tx" SG_ 1012 ChrgLocLongFrct_An_Sav 1;
BA_ "U_P702_MY2021_Tx" SG_ 1012 ChrgLocLongFrct_An_Sav 1;
BA_ "U_CD542_MY2021_Tx" SG_ 1012 ChrgLocLongFrct_An_Sav 1;
BA_ "ECGUsedRxSignal" SG_ 1012 ChrgLocLongDeg_An_Sav 1;
BA_ "U_CD542_MY2021_Rx" SG_ 1012 ChrgLocLongDeg_An_Sav 1;
BA_ "U_U55X_MY2022_Rx" SG_ 1012 ChrgLocLongDeg_An_Sav 1;
BA_ "U_CX727_MY2021_Tx" SG_ 1012 ChrgLocLongDeg_An_Sav 1;
BA_ "U_P702_MY2021_Tx" SG_ 1012 ChrgLocLongDeg_An_Sav 1;
BA_ "U_CD542_MY2021_Tx" SG_ 1012 ChrgLocLongDeg_An_Sav 1;
BA_ "ECGUsedRxSignal" SG_ 1012 ChrgLocLattPostv_B_Sav 1;
BA_ "U_CD542_MY2021_Rx" SG_ 1012 ChrgLocLattPostv_B_Sav 1;
BA_ "U_U55X_MY2022_Rx" SG_ 1012 ChrgLocLattPostv_B_Sav 1;
BA_ "U_CX727_MY2021_Tx" SG_ 1012 ChrgLocLattPostv_B_Sav 1;
BA_ "U_P702_MY2021_Tx" SG_ 1012 ChrgLocLattPostv_B_Sav 1;
BA_ "U_CD542_MY2021_Tx" SG_ 1012 ChrgLocLattPostv_B_Sav 1;
BA_ "GenSigStartValueInteger" SG_ 1012 ChrgLocLattFrct_An_Sav 1048575;
BA_ "GenSigStartValue" SG_ 1012 ChrgLocLattFrct_An_Sav 1048575;
BA_ "ECGUsedRxSignal" SG_ 1012 ChrgLocLattFrct_An_Sav 1;
BA_ "U_CD542_MY2021_Rx" SG_ 1012 ChrgLocLattFrct_An_Sav 1;
BA_ "U_U55X_MY2022_Rx" SG_ 1012 ChrgLocLattFrct_An_Sav 1;
BA_ "U_CX727_MY2021_Tx" SG_ 1012 ChrgLocLattFrct_An_Sav 1;
BA_ "U_P702_MY2021_Tx" SG_ 1012 ChrgLocLattFrct_An_Sav 1;
BA_ "U_CD542_MY2021_Tx" SG_ 1012 ChrgLocLattFrct_An_Sav 1;
BA_ "ECGUsedRxSignal" SG_ 1012 ChrgLocLattDeg_An_Sav 1;
BA_ "U_CD542_MY2021_Rx" SG_ 1012 ChrgLocLattDeg_An_Sav 1;
BA_ "U_U55X_MY2022_Rx" SG_ 1012 ChrgLocLattDeg_An_Sav 1;
BA_ "U_CX727_MY2021_Tx" SG_ 1012 ChrgLocLattDeg_An_Sav 1;
BA_ "U_P702_MY2021_Tx" SG_ 1012 ChrgLocLattDeg_An_Sav 1;
BA_ "U_CD542_MY2021_Tx" SG_ 1012 ChrgLocLattDeg_An_Sav 1;
BA_ "GenSigSendType" SG_ 1012 ChrgLocId_D_Sav 3;
BA_ "ECGUsedRxSignal" SG_ 1012 ChrgLocId_D_Sav 1;
BA_ "U_CD542_MY2021_Rx" SG_ 1012 ChrgLocId_D_Sav 1;
BA_ "U_U55X_MY2022_Rx" SG_ 1012 ChrgLocId_D_Sav 1;
BA_ "U_CX727_MY2021_Tx" SG_ 1012 ChrgLocId_D_Sav 1;
BA_ "U_P702_MY2021_Tx" SG_ 1012 ChrgLocId_D_Sav 1;
BA_ "U_CD542_MY2021_Tx" SG_ 1012 ChrgLocId_D_Sav 1;
BA_ "GenSigSendType" SG_ 1012 ChrgNowCurnt_B_Dsply 3;
BA_ "ECGUsedRxSignal" SG_ 1012 ChrgNowCurnt_B_Dsply 1;
BA_ "U_CD542_MY2021_Rx" SG_ 1012 ChrgNowCurnt_B_Dsply 1;
BA_ "U_U55X_MY2022_Rx" SG_ 1012 ChrgNowCurnt_B_Dsply 1;
BA_ "U_CX727_MY2021_Tx" SG_ 1012 ChrgNowCurnt_B_Dsply 1;
BA_ "U_P702_MY2021_Tx" SG_ 1012 ChrgNowCurnt_B_Dsply 1;
BA_ "U_CD542_MY2021_Tx" SG_ 1012 ChrgNowCurnt_B_Dsply 1;
BA_ "ECGUsedRxSignal" SG_ 1011 ChrgLocLongPostv_B_Uns 1;
BA_ "U_CD542_MY2021_Rx" SG_ 1011 ChrgLocLongPostv_B_Uns 1;
BA_ "U_U55X_MY2022_Rx" SG_ 1011 ChrgLocLongPostv_B_Uns 1;
BA_ "U_CX727_MY2021_Tx" SG_ 1011 ChrgLocLongPostv_B_Uns 1;
BA_ "U_P702_MY2021_Tx" SG_ 1011 ChrgLocLongPostv_B_Uns 1;
BA_ "U_CD542_MY2021_Tx" SG_ 1011 ChrgLocLongPostv_B_Uns 1;
BA_ "GenSigStartValueInteger" SG_ 1011 ChrgLocLongFrct_An_Uns 1048575;
BA_ "GenSigStartValue" SG_ 1011 ChrgLocLongFrct_An_Uns 1048575;
BA_ "ECGUsedRxSignal" SG_ 1011 ChrgLocLongFrct_An_Uns 1;
BA_ "U_CD542_MY2021_Rx" SG_ 1011 ChrgLocLongFrct_An_Uns 1;
BA_ "U_U55X_MY2022_Rx" SG_ 1011 ChrgLocLongFrct_An_Uns 1;
BA_ "U_CX727_MY2021_Tx" SG_ 1011 ChrgLocLongFrct_An_Uns 1;
BA_ "U_P702_MY2021_Tx" SG_ 1011 ChrgLocLongFrct_An_Uns 1;
BA_ "U_CD542_MY2021_Tx" SG_ 1011 ChrgLocLongFrct_An_Uns 1;
BA_ "ECGUsedRxSignal" SG_ 1011 ChrgLocLongDeg_An_Uns 1;
BA_ "U_CD542_MY2021_Rx" SG_ 1011 ChrgLocLongDeg_An_Uns 1;
BA_ "U_U55X_MY2022_Rx" SG_ 1011 ChrgLocLongDeg_An_Uns 1;
BA_ "U_CX727_MY2021_Tx" SG_ 1011 ChrgLocLongDeg_An_Uns 1;
BA_ "U_P702_MY2021_Tx" SG_ 1011 ChrgLocLongDeg_An_Uns 1;
BA_ "U_CD542_MY2021_Tx" SG_ 1011 ChrgLocLongDeg_An_Uns 1;
BA_ "ECGUsedRxSignal" SG_ 1011 ChrgLocLattPostv_B_Uns 1;
BA_ "U_CD542_MY2021_Rx" SG_ 1011 ChrgLocLattPostv_B_Uns 1;
BA_ "U_U55X_MY2022_Rx" SG_ 1011 ChrgLocLattPostv_B_Uns 1;
BA_ "U_CX727_MY2021_Tx" SG_ 1011 ChrgLocLattPostv_B_Uns 1;
BA_ "U_P702_MY2021_Tx" SG_ 1011 ChrgLocLattPostv_B_Uns 1;
BA_ "U_CD542_MY2021_Tx" SG_ 1011 ChrgLocLattPostv_B_Uns 1;
BA_ "GenSigStartValueInteger" SG_ 1011 ChrgLocLattFrct_An_Uns 1048575;
BA_ "GenSigStartValue" SG_ 1011 ChrgLocLattFrct_An_Uns 1048575;
BA_ "ECGUsedRxSignal" SG_ 1011 ChrgLocLattFrct_An_Uns 1;
BA_ "U_CD542_MY2021_Rx" SG_ 1011 ChrgLocLattFrct_An_Uns 1;
BA_ "U_U55X_MY2022_Rx" SG_ 1011 ChrgLocLattFrct_An_Uns 1;
BA_ "U_CX727_MY2021_Tx" SG_ 1011 ChrgLocLattFrct_An_Uns 1;
BA_ "U_P702_MY2021_Tx" SG_ 1011 ChrgLocLattFrct_An_Uns 1;
BA_ "U_CD542_MY2021_Tx" SG_ 1011 ChrgLocLattFrct_An_Uns 1;
BA_ "ECGUsedRxSignal" SG_ 1011 ChrgLocLattDeg_An_Uns 1;
BA_ "U_CD542_MY2021_Rx" SG_ 1011 ChrgLocLattDeg_An_Uns 1;
BA_ "U_U55X_MY2022_Rx" SG_ 1011 ChrgLocLattDeg_An_Uns 1;
BA_ "U_CX727_MY2021_Tx" SG_ 1011 ChrgLocLattDeg_An_Uns 1;
BA_ "U_P702_MY2021_Tx" SG_ 1011 ChrgLocLattDeg_An_Uns 1;
BA_ "U_CD542_MY2021_Tx" SG_ 1011 ChrgLocLattDeg_An_Uns 1;
BA_ "GenSigSendType" SG_ 1011 ChrgLocId_D_Uns 3;
BA_ "ECGUsedRxSignal" SG_ 1011 ChrgLocId_D_Uns 1;
BA_ "U_CD542_MY2021_Rx" SG_ 1011 ChrgLocId_D_Uns 1;
BA_ "U_U55X_MY2022_Rx" SG_ 1011 ChrgLocId_D_Uns 1;
BA_ "U_CX727_MY2021_Tx" SG_ 1011 ChrgLocId_D_Uns 1;
BA_ "U_P702_MY2021_Tx" SG_ 1011 ChrgLocId_D_Uns 1;
BA_ "U_CD542_MY2021_Tx" SG_ 1011 ChrgLocId_D_Uns 1;
BA_ "GenSigStartValueInteger" SG_ 1049 FrontDiffLck_D_RqDrv3 2;
BA_ "GenSigStartValue" SG_ 1049 FrontDiffLck_D_RqDrv3 2;
BA_ "GenSigStartValueInteger" SG_ 1049 RearDiffLck_D_RqDrv3 2;
BA_ "GenSigStartValue" SG_ 1049 RearDiffLck_D_RqDrv3 2;
BA_ "U_CD764_MY2022_Rx" SG_ 1049 CamraFrnt_B_RqMnu 1;
BA_ "U_T6_MCA_MY2020_Rx" SG_ 1049 SelDrvMdeTxtRst_B_Rq2 1;
BA_ "U_CD542_MY2021_Rx" SG_ 1049 SelDrvMdeTxtRst_B_Rq2 1;
BA_ "U_CD764_MY2022_Rx" SG_ 1049 SelDrvMdeTxtRst_B_Rq2 1;
BA_ "U_T6_MCA_MY2020_Rx" SG_ 1049 SelDrvMdePage_B_Stat 1;
BA_ "U_CD542_MY2021_Rx" SG_ 1049 SelDrvMdePage_B_Stat 1;
BA_ "U_CD764_MY2022_Rx" SG_ 1049 SelDrvMdePage_B_Stat 1;
BA_ "U_T6_MCA_MY2020_Rx" SG_ 1049 SelDrvMdeCnfm_D_Stat2 1;
BA_ "U_CD542_MY2021_Rx" SG_ 1049 SelDrvMdeCnfm_D_Stat2 1;
BA_ "U_CD764_MY2022_Rx" SG_ 1049 SelDrvMdeCnfm_D_Stat2 1;
BA_ "GenSigStartValue" SG_ 1049 SelDrvMde_D_RqDrv 31;
BA_ "U_T6_MCA_MY2020_Rx" SG_ 1049 SelDrvMde_D_RqDrv 1;
BA_ "U_CD542_MY2021_Rx" SG_ 1049 SelDrvMde_D_RqDrv 1;
BA_ "U_CD764_MY2022_Rx" SG_ 1049 SelDrvMde_D_RqDrv 1;
BA_ "GenSigSendType" SG_ 2611175457 PARSEDPhysIPMAtoGWM_ECG 3;
BA_ "U_T6_MCA_MY2020_Rx" SG_ 2611175457 PARSEDPhysIPMAtoGWM_ECG 1;
BA_ "ECGUsedRxSignal" SG_ 2611175457 PARSEDPhysIPMAtoGWM_ECG 1;
BA_ "U_CD542_MY2021_Rx" SG_ 2611175457 PARSEDPhysIPMAtoGWM_ECG 1;
BA_ "U_U55X_MY2022_Rx" SG_ 2611175457 PARSEDPhysIPMAtoGWM_ECG 1;
BA_ "U_CD764_MY2022_Rx" SG_ 2611175457 PARSEDPhysIPMAtoGWM_ECG 1;
BA_ "U_T6_MCA_MY2020_Tx" SG_ 2611175457 PARSEDPhysIPMAtoGWM_ECG 1;
BA_ "U_CD542_MY2021_Tx" SG_ 2611175457 PARSEDPhysIPMAtoGWM_ECG 1;
BA_ "U_U55X_MY2022_Tx" SG_ 2611175457 PARSEDPhysIPMAtoGWM_ECG 1;
BA_ "U_CD764_MY2022_Tx" SG_ 2611175457 PARSEDPhysIPMAtoGWM_ECG 1;
BA_ "GenSigSendType" SG_ 2609946840 OTAPhysGWM_ECGtoABS 3;
BA_ "U_T6_MCA_MY2020_Rx" SG_ 2609946840 OTAPhysGWM_ECGtoABS 1;
BA_ "U_CD542_MY2021_Rx" SG_ 2609946840 OTAPhysGWM_ECGtoABS 1;
BA_ "U_U55X_MY2022_Rx" SG_ 2609946840 OTAPhysGWM_ECGtoABS 1;
BA_ "U_CD764_MY2022_Rx" SG_ 2609946840 OTAPhysGWM_ECGtoABS 1;
BA_ "U_T6_MCA_MY2020_Tx" SG_ 2609946840 OTAPhysGWM_ECGtoABS 1;
BA_ "ECGUsedTxSignal" SG_ 2609946840 OTAPhysGWM_ECGtoABS 1;
BA_ "U_CD542_MY2021_Tx" SG_ 2609946840 OTAPhysGWM_ECGtoABS 1;
BA_ "U_U55X_MY2022_Tx" SG_ 2609946840 OTAPhysGWM_ECGtoABS 1;
BA_ "U_CD764_MY2022_Tx" SG_ 2609946840 OTAPhysGWM_ECGtoABS 1;
BA_ "GenSigSendType" SG_ 2610126888 OTAPhysABStoGWM_ECG 3;
BA_ "U_T6_MCA_MY2020_Rx" SG_ 2610126888 OTAPhysABStoGWM_ECG 1;
BA_ "ECGUsedRxSignal" SG_ 2610126888 OTAPhysABStoGWM_ECG 1;
BA_ "U_CD542_MY2021_Rx" SG_ 2610126888 OTAPhysABStoGWM_ECG 1;
BA_ "U_U55X_MY2022_Rx" SG_ 2610126888 OTAPhysABStoGWM_ECG 1;
BA_ "U_CD764_MY2022_Rx" SG_ 2610126888 OTAPhysABStoGWM_ECG 1;
BA_ "U_T6_MCA_MY2020_Tx" SG_ 2610126888 OTAPhysABStoGWM_ECG 1;
BA_ "U_CD542_MY2021_Tx" SG_ 2610126888 OTAPhysABStoGWM_ECG 1;
BA_ "U_U55X_MY2022_Tx" SG_ 2610126888 OTAPhysABStoGWM_ECG 1;
BA_ "U_CD764_MY2022_Tx" SG_ 2610126888 OTAPhysABStoGWM_ECG 1;
BA_ "GenSigSendType" SG_ 2611175440 PARSEDPhysPCMtoGWM_ECG 3;
BA_ "U_T6_MCA_MY2020_Rx" SG_ 2611175440 PARSEDPhysPCMtoGWM_ECG 1;
BA_ "ECGUsedRxSignal" SG_ 2611175440 PARSEDPhysPCMtoGWM_ECG 1;
BA_ "U_U55X_MY2022_Rx" SG_ 2611175440 PARSEDPhysPCMtoGWM_ECG 1;
BA_ "U_CD764_MY2022_Rx" SG_ 2611175440 PARSEDPhysPCMtoGWM_ECG 1;
BA_ "U_P702_MY2021_Tx" SG_ 2611175440 PARSEDPhysPCMtoGWM_ECG 1;
BA_ "U_T6_MCA_MY2020_Tx" SG_ 2611175440 PARSEDPhysPCMtoGWM_ECG 1;
BA_ "U_CD542_MY2021_Tx" SG_ 2611175440 PARSEDPhysPCMtoGWM_ECG 1;
BA_ "U_U55X_MY2022_Tx" SG_ 2611175440 PARSEDPhysPCMtoGWM_ECG 1;
BA_ "U_CD764_MY2022_Tx" SG_ 2611175440 PARSEDPhysPCMtoGWM_ECG 1;
BA_ "GenSigSendType" SG_ 2609922264 OTAPhysGWM_ECGtoPCM 3;
BA_ "U_P702_MY2021_Rx" SG_ 2609922264 OTAPhysGWM_ECGtoPCM 1;
BA_ "U_T6_MCA_MY2020_Rx" SG_ 2609922264 OTAPhysGWM_ECGtoPCM 1;
BA_ "U_CD542_MY2021_Rx" SG_ 2609922264 OTAPhysGWM_ECGtoPCM 1;
BA_ "U_U55X_MY2022_Rx" SG_ 2609922264 OTAPhysGWM_ECGtoPCM 1;
BA_ "U_CD764_MY2022_Rx" SG_ 2609922264 OTAPhysGWM_ECGtoPCM 1;
BA_ "U_T6_MCA_MY2020_Tx" SG_ 2609922264 OTAPhysGWM_ECGtoPCM 1;
BA_ "ECGUsedTxSignal" SG_ 2609922264 OTAPhysGWM_ECGtoPCM 1;
BA_ "U_U55X_MY2022_Tx" SG_ 2609922264 OTAPhysGWM_ECGtoPCM 1;
BA_ "U_CD764_MY2022_Tx" SG_ 2609922264 OTAPhysGWM_ECGtoPCM 1;
BA_ "GenSigSendType" SG_ 2610953432 OTAFuncGWM_ECG 3;
BA_ "U_CX727_MY2021_Rx" SG_ 2610953432 OTAFuncGWM_ECG 1;
BA_ "U_P702_MY2021_Rx" SG_ 2610953432 OTAFuncGWM_ECG 1;
BA_ "U_T6_MCA_MY2020_Rx" SG_ 2610953432 OTAFuncGWM_ECG 1;
BA_ "U_CD542_MY2021_Rx" SG_ 2610953432 OTAFuncGWM_ECG 1;
BA_ "U_U55X_MY2022_Rx" SG_ 2610953432 OTAFuncGWM_ECG 1;
BA_ "U_CD764_MY2022_Rx" SG_ 2610953432 OTAFuncGWM_ECG 1;
BA_ "U_T6_MCA_MY2020_Tx" SG_ 2610953432 OTAFuncGWM_ECG 1;
BA_ "ECGUsedTxSignal" SG_ 2610953432 OTAFuncGWM_ECG 1;
BA_ "U_CD542_MY2021_Tx" SG_ 2610953432 OTAFuncGWM_ECG 1;
BA_ "U_U55X_MY2022_Tx" SG_ 2610953432 OTAFuncGWM_ECG 1;
BA_ "U_CD764_MY2022_Tx" SG_ 2610953432 OTAFuncGWM_ECG 1;
BA_ "GenSigSendType" SG_ 2610126864 OTAPhysPCMtoGWM_ECG 3;
BA_ "U_T6_MCA_MY2020_Rx" SG_ 2610126864 OTAPhysPCMtoGWM_ECG 1;
BA_ "ECGUsedRxSignal" SG_ 2610126864 OTAPhysPCMtoGWM_ECG 1;
BA_ "U_U55X_MY2022_Rx" SG_ 2610126864 OTAPhysPCMtoGWM_ECG 1;
BA_ "U_CD764_MY2022_Rx" SG_ 2610126864 OTAPhysPCMtoGWM_ECG 1;
BA_ "U_P702_MY2021_Tx" SG_ 2610126864 OTAPhysPCMtoGWM_ECG 1;
BA_ "U_T6_MCA_MY2020_Tx" SG_ 2610126864 OTAPhysPCMtoGWM_ECG 1;
BA_ "U_CD542_MY2021_Tx" SG_ 2610126864 OTAPhysPCMtoGWM_ECG 1;
BA_ "U_U55X_MY2022_Tx" SG_ 2610126864 OTAPhysPCMtoGWM_ECG 1;
BA_ "U_CD764_MY2022_Tx" SG_ 2610126864 OTAPhysPCMtoGWM_ECG 1;
BA_ "GenSigSendType" SG_ 2612002008 PARSEDFuncGWM_ECG 3;
BA_ "U_P702_MY2021_Rx" SG_ 2612002008 PARSEDFuncGWM_ECG 1;
BA_ "U_T6_MCA_MY2020_Rx" SG_ 2612002008 PARSEDFuncGWM_ECG 1;
BA_ "U_CD542_MY2021_Rx" SG_ 2612002008 PARSEDFuncGWM_ECG 1;
BA_ "U_U55X_MY2022_Rx" SG_ 2612002008 PARSEDFuncGWM_ECG 1;
BA_ "U_CD764_MY2022_Rx" SG_ 2612002008 PARSEDFuncGWM_ECG 1;
BA_ "U_T6_MCA_MY2020_Tx" SG_ 2612002008 PARSEDFuncGWM_ECG 1;
BA_ "ECGUsedTxSignal" SG_ 2612002008 PARSEDFuncGWM_ECG 1;
BA_ "U_CD542_MY2021_Tx" SG_ 2612002008 PARSEDFuncGWM_ECG 1;
BA_ "U_U55X_MY2022_Tx" SG_ 2612002008 PARSEDFuncGWM_ECG 1;
BA_ "U_CD764_MY2022_Tx" SG_ 2612002008 PARSEDFuncGWM_ECG 1;
BA_ "GenSigSendType" SG_ 2610970840 PARSEDPhysGWM_ECGtoPCM 3;
BA_ "U_P702_MY2021_Rx" SG_ 2610970840 PARSEDPhysGWM_ECGtoPCM 1;
BA_ "U_T6_MCA_MY2020_Rx" SG_ 2610970840 PARSEDPhysGWM_ECGtoPCM 1;
BA_ "U_CD542_MY2021_Rx" SG_ 2610970840 PARSEDPhysGWM_ECGtoPCM 1;
BA_ "U_U55X_MY2022_Rx" SG_ 2610970840 PARSEDPhysGWM_ECGtoPCM 1;
BA_ "U_CD764_MY2022_Rx" SG_ 2610970840 PARSEDPhysGWM_ECGtoPCM 1;
BA_ "U_T6_MCA_MY2020_Tx" SG_ 2610970840 PARSEDPhysGWM_ECGtoPCM 1;
BA_ "ECGUsedTxSignal" SG_ 2610970840 PARSEDPhysGWM_ECGtoPCM 1;
BA_ "U_U55X_MY2022_Tx" SG_ 2610970840 PARSEDPhysGWM_ECGtoPCM 1;
BA_ "U_CD764_MY2022_Tx" SG_ 2610970840 PARSEDPhysGWM_ECGtoPCM 1;
BA_ "GenSigSendType" SG_ 2612224016 PARSEDPushPCMtoGWM_ECG 3;
BA_ "U_T6_MCA_MY2020_Rx" SG_ 2612224016 PARSEDPushPCMtoGWM_ECG 1;
BA_ "ECGUsedRxSignal" SG_ 2612224016 PARSEDPushPCMtoGWM_ECG 1;
BA_ "U_U55X_MY2022_Rx" SG_ 2612224016 PARSEDPushPCMtoGWM_ECG 1;
BA_ "U_CD764_MY2022_Rx" SG_ 2612224016 PARSEDPushPCMtoGWM_ECG 1;
BA_ "U_P702_MY2021_Tx" SG_ 2612224016 PARSEDPushPCMtoGWM_ECG 1;
BA_ "U_T6_MCA_MY2020_Tx" SG_ 2612224016 PARSEDPushPCMtoGWM_ECG 1;
BA_ "U_CD542_MY2021_Tx" SG_ 2612224016 PARSEDPushPCMtoGWM_ECG 1;
BA_ "U_U55X_MY2022_Tx" SG_ 2612224016 PARSEDPushPCMtoGWM_ECG 1;
BA_ "U_CD764_MY2022_Tx" SG_ 2612224016 PARSEDPushPCMtoGWM_ECG 1;
BA_ "GenSigSendType" SG_ 775 ScDayOfWeekId_D_RqCld 3;
BA_ "GenSigStartValue" SG_ 775 ScDayOfWeekId_D_RqCld 1;
BA_ "ECGUsedTxSignal" SG_ 775 ScDayOfWeekId_D_RqCld 1;
BA_ "U_CD542_MY2021_Tx" SG_ 775 ScDayOfWeekId_D_RqCld 1;
BA_ "U_U55X_MY2022_Tx" SG_ 775 ScDayOfWeekId_D_RqCld 1;
BA_ "GenSigSendType" SG_ 775 ScLocSetId_No_RqCld 3;
BA_ "ECGUsedTxSignal" SG_ 775 ScLocSetId_No_RqCld 1;
BA_ "U_CD542_MY2021_Tx" SG_ 775 ScLocSetId_No_RqCld 1;
BA_ "U_U55X_MY2022_Tx" SG_ 775 ScLocSetId_No_RqCld 1;
BA_ "GenSigStartValue" SG_ 775 ScLocRdius_L_RqCld 1;
BA_ "ECGUsedTxSignal" SG_ 775 ScLocRdius_L_RqCld 1;
BA_ "U_CD542_MY2021_Tx" SG_ 775 ScLocRdius_L_RqCld 1;
BA_ "U_U55X_MY2022_Tx" SG_ 775 ScLocRdius_L_RqCld 1;
BA_ "GenSigStartValue" SG_ 775 ScChrgToPc_Pc_RqCld 100;
BA_ "ECGUsedTxSignal" SG_ 775 ScChrgToPc_Pc_RqCld 1;
BA_ "U_CD542_MY2021_Tx" SG_ 775 ScChrgToPc_Pc_RqCld 1;
BA_ "U_U55X_MY2022_Tx" SG_ 775 ScChrgToPc_Pc_RqCld 1;
BA_ "ECGUsedTxSignal" SG_ 775 ScChrgPrfl_No_RqCld 1;
BA_ "U_CD542_MY2021_Tx" SG_ 775 ScChrgPrfl_No_RqCld 1;
BA_ "U_U55X_MY2022_Tx" SG_ 775 ScChrgPrfl_No_RqCld 1;
BA_ "GenSigStartValue" SG_ 775 ScChrgDurSet_D_RqCld 1;
BA_ "ECGUsedTxSignal" SG_ 775 ScChrgDurSet_D_RqCld 1;
BA_ "U_CD542_MY2021_Tx" SG_ 775 ScChrgDurSet_D_RqCld 1;
BA_ "U_U55X_MY2022_Tx" SG_ 775 ScChrgDurSet_D_RqCld 1;
BA_ "ECGUsedTxSignal" SG_ 775 ScChrgDur_T_RqCld 1;
BA_ "U_CD542_MY2021_Tx" SG_ 775 ScChrgDur_T_RqCld 1;
BA_ "U_U55X_MY2022_Tx" SG_ 775 ScChrgDur_T_RqCld 1;
BA_ "ECGUsedTxSignal" SG_ 774 ScLocLongPostv_B_RqCld 1;
BA_ "U_CD542_MY2021_Tx" SG_ 774 ScLocLongPostv_B_RqCld 1;
BA_ "U_U55X_MY2022_Tx" SG_ 774 ScLocLongPostv_B_RqCld 1;
BA_ "GenSigStartValue" SG_ 774 ScLocLongFrct_An_RqCld 1048575;
BA_ "ECGUsedTxSignal" SG_ 774 ScLocLongFrct_An_RqCld 1;
BA_ "U_CD542_MY2021_Tx" SG_ 774 ScLocLongFrct_An_RqCld 1;
BA_ "U_U55X_MY2022_Tx" SG_ 774 ScLocLongFrct_An_RqCld 1;
BA_ "ECGUsedTxSignal" SG_ 774 ScLocLongDeg_An_RqCld 1;
BA_ "U_CD542_MY2021_Tx" SG_ 774 ScLocLongDeg_An_RqCld 1;
BA_ "U_U55X_MY2022_Tx" SG_ 774 ScLocLongDeg_An_RqCld 1;
BA_ "ECGUsedTxSignal" SG_ 774 ScLocLattPostv_B_RqCld 1;
BA_ "U_CD542_MY2021_Tx" SG_ 774 ScLocLattPostv_B_RqCld 1;
BA_ "U_U55X_MY2022_Tx" SG_ 774 ScLocLattPostv_B_RqCld 1;
BA_ "GenSigStartValue" SG_ 774 ScLocLattFrct_An_RqCld 1048575;
BA_ "ECGUsedTxSignal" SG_ 774 ScLocLattFrct_An_RqCld 1;
BA_ "U_CD542_MY2021_Tx" SG_ 774 ScLocLattFrct_An_RqCld 1;
BA_ "U_U55X_MY2022_Tx" SG_ 774 ScLocLattFrct_An_RqCld 1;
BA_ "ECGUsedTxSignal" SG_ 774 ScLocLattDeg_An_RqCld 1;
BA_ "U_CD542_MY2021_Tx" SG_ 774 ScLocLattDeg_An_RqCld 1;
BA_ "U_U55X_MY2022_Tx" SG_ 774 ScLocLattDeg_An_RqCld 1;
BA_ "GenSigSendType" SG_ 774 ScLocId_No_RqCld 3;
BA_ "ECGUsedTxSignal" SG_ 774 ScLocId_No_RqCld 1;
BA_ "U_CD542_MY2021_Tx" SG_ 774 ScLocId_No_RqCld 1;
BA_ "U_U55X_MY2022_Tx" SG_ 774 ScLocId_No_RqCld 1;
BA_ "GenSigSendType" SG_ 774 ScLocDelete_B_RqCld 3;
BA_ "ECGUsedTxSignal" SG_ 774 ScLocDelete_B_RqCld 1;
BA_ "U_CD542_MY2021_Tx" SG_ 774 ScLocDelete_B_RqCld 1;
BA_ "U_U55X_MY2022_Tx" SG_ 774 ScLocDelete_B_RqCld 1;
BA_ "GenSigStartValueInteger" SG_ 943 VehVActlAdas_D_Qf 1;
BA_ "MetaData" SG_ 943 VehVActlAdas_D_Qf 1;
BA_ "GenSigStartValue" SG_ 943 VehVActlAdas_D_Qf 1;
BA_ "U_T6_MCA_MY2020_Rx" SG_ 943 VehVActlAdas_D_Qf 1;
BA_ "U_CD764_MY2022_Rx" SG_ 943 VehVActlAdas_D_Qf 1;
BA_ "U_T6_MCA_MY2020_Tx" SG_ 943 VehVActlAdas_D_Qf 1;
BA_ "U_CD542_MY2021_Tx" SG_ 943 VehVActlAdas_D_Qf 1;
BA_ "U_U55X_MY2022_Tx" SG_ 943 VehVActlAdas_D_Qf 1;
BA_ "U_CD764_MY2022_Tx" SG_ 943 VehVActlAdas_D_Qf 1;
BA_ "U_T6_MCA_MY2020_Rx" SG_ 943 Veh_V_RqLsc 1;
BA_ "U_CD764_MY2022_Rx" SG_ 943 Veh_V_RqLsc 1;
BA_ "U_T6_MCA_MY2020_Tx" SG_ 943 Veh_V_RqLsc 1;
BA_ "U_CD542_MY2021_Tx" SG_ 943 Veh_V_RqLsc 1;
BA_ "U_U55X_MY2022_Tx" SG_ 943 Veh_V_RqLsc 1;
BA_ "U_CD764_MY2022_Tx" SG_ 943 Veh_V_RqLsc 1;
BA_ "U_T6_MCA_MY2020_Rx" SG_ 943 Veh_V_ActlAdas 1;
BA_ "U_CD764_MY2022_Rx" SG_ 943 Veh_V_ActlAdas 1;
BA_ "U_T6_MCA_MY2020_Tx" SG_ 943 Veh_V_ActlAdas 1;
BA_ "U_CD542_MY2021_Tx" SG_ 943 Veh_V_ActlAdas 1;
BA_ "U_U55X_MY2022_Tx" SG_ 943 Veh_V_ActlAdas 1;
BA_ "U_CD764_MY2022_Tx" SG_ 943 Veh_V_ActlAdas 1;
BA_ "GenSigStartValue" SG_ 943 AdasLcDistToObj_L_Actl 4094;
BA_ "U_T6_MCA_MY2020_Rx" SG_ 943 AdasLcDistToObj_L_Actl 1;
BA_ "U_CD764_MY2022_Rx" SG_ 943 AdasLcDistToObj_L_Actl 1;
BA_ "U_T6_MCA_MY2020_Tx" SG_ 943 AdasLcDistToObj_L_Actl 1;
BA_ "U_CD542_MY2021_Tx" SG_ 943 AdasLcDistToObj_L_Actl 1;
BA_ "U_U55X_MY2022_Tx" SG_ 943 AdasLcDistToObj_L_Actl 1;
BA_ "U_CD764_MY2022_Tx" SG_ 943 AdasLcDistToObj_L_Actl 1;
BA_ "GenSigSendType" SG_ 930 BalrWndwRight_B_Stat 3;
BA_ "U_T6_MCA_MY2020_Tx" SG_ 930 BalrWndwRight_B_Stat 1;
BA_ "U_CD542_MY2021_Tx" SG_ 930 BalrWndwRight_B_Stat 1;
BA_ "U_U55X_MY2022_Tx" SG_ 930 BalrWndwRight_B_Stat 1;
BA_ "U_CD764_MY2022_Tx" SG_ 930 BalrWndwRight_B_Stat 1;
BA_ "GenSigSendType" SG_ 930 BalrSnsRight_D_Falt 3;
BA_ "U_T6_MCA_MY2020_Tx" SG_ 930 BalrSnsRight_D_Falt 1;
BA_ "U_CD542_MY2021_Tx" SG_ 930 BalrSnsRight_D_Falt 1;
BA_ "U_U55X_MY2022_Tx" SG_ 930 BalrSnsRight_D_Falt 1;
BA_ "U_CD764_MY2022_Tx" SG_ 930 BalrSnsRight_D_Falt 1;
BA_ "GenSigSendType" SG_ 930 WndwPsngrRear_D_RqBalrr 3;
BA_ "U_T6_MCA_MY2020_Tx" SG_ 930 WndwPsngrRear_D_RqBalrr 1;
BA_ "U_CD542_MY2021_Tx" SG_ 930 WndwPsngrRear_D_RqBalrr 1;
BA_ "U_U55X_MY2022_Tx" SG_ 930 WndwPsngrRear_D_RqBalrr 1;
BA_ "U_CD764_MY2022_Tx" SG_ 930 WndwPsngrRear_D_RqBalrr 1;
BA_ "GenSigSendType" SG_ 930 WndwPsngr_D_RqBalrr 3;
BA_ "U_T6_MCA_MY2020_Tx" SG_ 930 WndwPsngr_D_RqBalrr 1;
BA_ "U_CD542_MY2021_Tx" SG_ 930 WndwPsngr_D_RqBalrr 1;
BA_ "U_U55X_MY2022_Tx" SG_ 930 WndwPsngr_D_RqBalrr 1;
BA_ "U_CD764_MY2022_Tx" SG_ 930 WndwPsngr_D_RqBalrr 1;
BA_ "GenSigSendType" SG_ 930 WndwDrvRear_D_RqBalrr 3;
BA_ "U_T6_MCA_MY2020_Tx" SG_ 930 WndwDrvRear_D_RqBalrr 1;
BA_ "U_CD542_MY2021_Tx" SG_ 930 WndwDrvRear_D_RqBalrr 1;
BA_ "U_U55X_MY2022_Tx" SG_ 930 WndwDrvRear_D_RqBalrr 1;
BA_ "U_CD764_MY2022_Tx" SG_ 930 WndwDrvRear_D_RqBalrr 1;
BA_ "GenSigSendType" SG_ 930 WndwDrv_D_RqBalrr 3;
BA_ "U_T6_MCA_MY2020_Tx" SG_ 930 WndwDrv_D_RqBalrr 1;
BA_ "U_CD542_MY2021_Tx" SG_ 930 WndwDrv_D_RqBalrr 1;
BA_ "U_U55X_MY2022_Tx" SG_ 930 WndwDrv_D_RqBalrr 1;
BA_ "U_CD764_MY2022_Tx" SG_ 930 WndwDrv_D_RqBalrr 1;
BA_ "GenSigSendType" SG_ 930 BalrRight_D_Stat 3;
BA_ "GenSigStartValueInteger" SG_ 930 BalrRight_D_Stat 2;
BA_ "GenSigStartValue" SG_ 930 BalrRight_D_Stat 2;
BA_ "U_T6_MCA_MY2020_Tx" SG_ 930 BalrRight_D_Stat 1;
BA_ "U_CD542_MY2021_Tx" SG_ 930 BalrRight_D_Stat 1;
BA_ "U_U55X_MY2022_Tx" SG_ 930 BalrRight_D_Stat 1;
BA_ "U_CD764_MY2022_Tx" SG_ 930 BalrRight_D_Stat 1;
BA_ "GenSigSendType" SG_ 930 BalrMdeSelRight_B_Stat 3;
BA_ "U_T6_MCA_MY2020_Tx" SG_ 930 BalrMdeSelRight_B_Stat 1;
BA_ "U_CD542_MY2021_Tx" SG_ 930 BalrMdeSelRight_B_Stat 1;
BA_ "U_U55X_MY2022_Tx" SG_ 930 BalrMdeSelRight_B_Stat 1;
BA_ "U_CD764_MY2022_Tx" SG_ 930 BalrMdeSelRight_B_Stat 1;
BA_ "GenSigSendType" SG_ 930 BalrMdeRight_D_Stat 3;
BA_ "GenSigStartValueInteger" SG_ 930 BalrMdeRight_D_Stat 1;
BA_ "GenSigStartValue" SG_ 930 BalrMdeRight_D_Stat 1;
BA_ "U_T6_MCA_MY2020_Tx" SG_ 930 BalrMdeRight_D_Stat 1;
BA_ "U_CD542_MY2021_Tx" SG_ 930 BalrMdeRight_D_Stat 1;
BA_ "U_U55X_MY2022_Tx" SG_ 930 BalrMdeRight_D_Stat 1;
BA_ "U_CD764_MY2022_Tx" SG_ 930 BalrMdeRight_D_Stat 1;
BA_ "GenSigSendType" SG_ 930 BalrLckRight_B_Stat 3;
BA_ "U_T6_MCA_MY2020_Tx" SG_ 930 BalrLckRight_B_Stat 1;
BA_ "U_CD542_MY2021_Tx" SG_ 930 BalrLckRight_B_Stat 1;
BA_ "U_U55X_MY2022_Tx" SG_ 930 BalrLckRight_B_Stat 1;
BA_ "U_CD764_MY2022_Tx" SG_ 930 BalrLckRight_B_Stat 1;
BA_ "GenSigSendType" SG_ 930 BalrChimeRight_D_Rq 3;
BA_ "U_T6_MCA_MY2020_Tx" SG_ 930 BalrChimeRight_D_Rq 1;
BA_ "U_CD542_MY2021_Tx" SG_ 930 BalrChimeRight_D_Rq 1;
BA_ "U_U55X_MY2022_Tx" SG_ 930 BalrChimeRight_D_Rq 1;
BA_ "U_CD764_MY2022_Tx" SG_ 930 BalrChimeRight_D_Rq 1;
BA_ "GenSigSendType" SG_ 930 CamraRearOn_B_RqBalrr 3;
BA_ "U_T6_MCA_MY2020_Tx" SG_ 930 CamraRearOn_B_RqBalrr 1;
BA_ "U_CD542_MY2021_Tx" SG_ 930 CamraRearOn_B_RqBalrr 1;
BA_ "U_U55X_MY2022_Tx" SG_ 930 CamraRearOn_B_RqBalrr 1;
BA_ "U_CD764_MY2022_Tx" SG_ 930 CamraRearOn_B_RqBalrr 1;
BA_ "GenSigSendType" SG_ 930 DrLckCnt_No_ActlBalrr 3;
BA_ "U_T6_MCA_MY2020_Tx" SG_ 930 DrLckCnt_No_ActlBalrr 1;
BA_ "U_CD542_MY2021_Tx" SG_ 930 DrLckCnt_No_ActlBalrr 1;
BA_ "U_U55X_MY2022_Tx" SG_ 930 DrLckCnt_No_ActlBalrr 1;
BA_ "U_CD764_MY2022_Tx" SG_ 930 DrLckCnt_No_ActlBalrr 1;
BA_ "GenSigSendType" SG_ 930 DrLckActv_B_RqBalrr 3;
BA_ "U_T6_MCA_MY2020_Tx" SG_ 930 DrLckActv_B_RqBalrr 1;
BA_ "U_CD542_MY2021_Tx" SG_ 930 DrLckActv_B_RqBalrr 1;
BA_ "U_U55X_MY2022_Tx" SG_ 930 DrLckActv_B_RqBalrr 1;
BA_ "U_CD764_MY2022_Tx" SG_ 930 DrLckActv_B_RqBalrr 1;
BA_ "GenSigSendType" SG_ 929 BalrChimeLeft_D_Rq 3;
BA_ "U_T6_MCA_MY2020_Tx" SG_ 929 BalrChimeLeft_D_Rq 1;
BA_ "U_CD542_MY2021_Tx" SG_ 929 BalrChimeLeft_D_Rq 1;
BA_ "U_U55X_MY2022_Tx" SG_ 929 BalrChimeLeft_D_Rq 1;
BA_ "U_CD764_MY2022_Tx" SG_ 929 BalrChimeLeft_D_Rq 1;
BA_ "GenSigSendType" SG_ 929 BalrLeft_D_Stat 3;
BA_ "GenSigStartValueInteger" SG_ 929 BalrLeft_D_Stat 2;
BA_ "GenSigStartValue" SG_ 929 BalrLeft_D_Stat 2;
BA_ "U_T6_MCA_MY2020_Tx" SG_ 929 BalrLeft_D_Stat 1;
BA_ "U_CD542_MY2021_Tx" SG_ 929 BalrLeft_D_Stat 1;
BA_ "U_U55X_MY2022_Tx" SG_ 929 BalrLeft_D_Stat 1;
BA_ "U_CD764_MY2022_Tx" SG_ 929 BalrLeft_D_Stat 1;
BA_ "GenSigSendType" SG_ 929 WndwPsngrRear_D_RqBalrl 3;
BA_ "U_T6_MCA_MY2020_Tx" SG_ 929 WndwPsngrRear_D_RqBalrl 1;
BA_ "U_CD542_MY2021_Tx" SG_ 929 WndwPsngrRear_D_RqBalrl 1;
BA_ "U_U55X_MY2022_Tx" SG_ 929 WndwPsngrRear_D_RqBalrl 1;
BA_ "U_CD764_MY2022_Tx" SG_ 929 WndwPsngrRear_D_RqBalrl 1;
BA_ "GenSigSendType" SG_ 929 WndwPsngr_D_RqBalrl 3;
BA_ "U_T6_MCA_MY2020_Tx" SG_ 929 WndwPsngr_D_RqBalrl 1;
BA_ "U_CD542_MY2021_Tx" SG_ 929 WndwPsngr_D_RqBalrl 1;
BA_ "U_U55X_MY2022_Tx" SG_ 929 WndwPsngr_D_RqBalrl 1;
BA_ "U_CD764_MY2022_Tx" SG_ 929 WndwPsngr_D_RqBalrl 1;
BA_ "GenSigSendType" SG_ 929 WndwDrvRear_D_RqBalrl 3;
BA_ "U_T6_MCA_MY2020_Tx" SG_ 929 WndwDrvRear_D_RqBalrl 1;
BA_ "U_CD542_MY2021_Tx" SG_ 929 WndwDrvRear_D_RqBalrl 1;
BA_ "U_U55X_MY2022_Tx" SG_ 929 WndwDrvRear_D_RqBalrl 1;
BA_ "U_CD764_MY2022_Tx" SG_ 929 WndwDrvRear_D_RqBalrl 1;
BA_ "GenSigSendType" SG_ 929 WndwDrv_D_RqBalrl 3;
BA_ "U_T6_MCA_MY2020_Tx" SG_ 929 WndwDrv_D_RqBalrl 1;
BA_ "U_CD542_MY2021_Tx" SG_ 929 WndwDrv_D_RqBalrl 1;
BA_ "U_U55X_MY2022_Tx" SG_ 929 WndwDrv_D_RqBalrl 1;
BA_ "U_CD764_MY2022_Tx" SG_ 929 WndwDrv_D_RqBalrl 1;
BA_ "GenSigSendType" SG_ 929 BalrSnsLeft_D_Falt 3;
BA_ "U_T6_MCA_MY2020_Tx" SG_ 929 BalrSnsLeft_D_Falt 1;
BA_ "U_CD542_MY2021_Tx" SG_ 929 BalrSnsLeft_D_Falt 1;
BA_ "U_U55X_MY2022_Tx" SG_ 929 BalrSnsLeft_D_Falt 1;
BA_ "U_CD764_MY2022_Tx" SG_ 929 BalrSnsLeft_D_Falt 1;
BA_ "GenSigSendType" SG_ 929 BalrMdeSelLeft_B_Stat 3;
BA_ "U_T6_MCA_MY2020_Tx" SG_ 929 BalrMdeSelLeft_B_Stat 1;
BA_ "U_CD542_MY2021_Tx" SG_ 929 BalrMdeSelLeft_B_Stat 1;
BA_ "U_U55X_MY2022_Tx" SG_ 929 BalrMdeSelLeft_B_Stat 1;
BA_ "U_CD764_MY2022_Tx" SG_ 929 BalrMdeSelLeft_B_Stat 1;
BA_ "GenSigSendType" SG_ 929 BalrMdeLeft_D_Stat 3;
BA_ "GenSigStartValueInteger" SG_ 929 BalrMdeLeft_D_Stat 1;
BA_ "GenSigStartValue" SG_ 929 BalrMdeLeft_D_Stat 1;
BA_ "U_T6_MCA_MY2020_Tx" SG_ 929 BalrMdeLeft_D_Stat 1;
BA_ "U_CD542_MY2021_Tx" SG_ 929 BalrMdeLeft_D_Stat 1;
BA_ "U_U55X_MY2022_Tx" SG_ 929 BalrMdeLeft_D_Stat 1;
BA_ "U_CD764_MY2022_Tx" SG_ 929 BalrMdeLeft_D_Stat 1;
BA_ "GenSigSendType" SG_ 929 BalrLckLeft_B_Stat 3;
BA_ "U_T6_MCA_MY2020_Tx" SG_ 929 BalrLckLeft_B_Stat 1;
BA_ "U_CD542_MY2021_Tx" SG_ 929 BalrLckLeft_B_Stat 1;
BA_ "U_U55X_MY2022_Tx" SG_ 929 BalrLckLeft_B_Stat 1;
BA_ "U_CD764_MY2022_Tx" SG_ 929 BalrLckLeft_B_Stat 1;
BA_ "GenSigSendType" SG_ 929 CamraRearOn_B_RqBalrl 3;
BA_ "U_T6_MCA_MY2020_Tx" SG_ 929 CamraRearOn_B_RqBalrl 1;
BA_ "U_CD542_MY2021_Tx" SG_ 929 CamraRearOn_B_RqBalrl 1;
BA_ "U_U55X_MY2022_Tx" SG_ 929 CamraRearOn_B_RqBalrl 1;
BA_ "U_CD764_MY2022_Tx" SG_ 929 CamraRearOn_B_RqBalrl 1;
BA_ "GenSigSendType" SG_ 929 DrLckCnt_No_ActlBalrl 3;
BA_ "U_T6_MCA_MY2020_Tx" SG_ 929 DrLckCnt_No_ActlBalrl 1;
BA_ "U_CD542_MY2021_Tx" SG_ 929 DrLckCnt_No_ActlBalrl 1;
BA_ "U_U55X_MY2022_Tx" SG_ 929 DrLckCnt_No_ActlBalrl 1;
BA_ "U_CD764_MY2022_Tx" SG_ 929 DrLckCnt_No_ActlBalrl 1;
BA_ "GenSigSendType" SG_ 929 DrLckActv_B_RqBalrl 3;
BA_ "U_T6_MCA_MY2020_Tx" SG_ 929 DrLckActv_B_RqBalrl 1;
BA_ "U_CD542_MY2021_Tx" SG_ 929 DrLckActv_B_RqBalrl 1;
BA_ "U_U55X_MY2022_Tx" SG_ 929 DrLckActv_B_RqBalrl 1;
BA_ "U_CD764_MY2022_Tx" SG_ 929 DrLckActv_B_RqBalrl 1;
BA_ "GenSigSendType" SG_ 929 BalrWndwLeft_B_Stat 3;
BA_ "U_T6_MCA_MY2020_Tx" SG_ 929 BalrWndwLeft_B_Stat 1;
BA_ "U_U55X_MY2022_Tx" SG_ 929 BalrWndwLeft_B_Stat 1;
BA_ "U_CD764_MY2022_Tx" SG_ 929 BalrWndwLeft_B_Stat 1;
BA_ "GenSigSendType" SG_ 1783 TesterPhysicalReqLDCMB 3;
BA_ "GenSigSendType" SG_ 2612194520 PARSEDPushFcGWM_ECGtoCMR 3;
BA_ "U_T6_MCA_MY2020_Rx" SG_ 2612194520 PARSEDPushFcGWM_ECGtoCMR 1;
BA_ "U_CD542_MY2021_Rx" SG_ 2612194520 PARSEDPushFcGWM_ECGtoCMR 1;
BA_ "U_U55X_MY2022_Rx" SG_ 2612194520 PARSEDPushFcGWM_ECGtoCMR 1;
BA_ "U_CD764_MY2022_Rx" SG_ 2612194520 PARSEDPushFcGWM_ECGtoCMR 1;
BA_ "U_T6_MCA_MY2020_Tx" SG_ 2612194520 PARSEDPushFcGWM_ECGtoCMR 1;
BA_ "ECGUsedTxSignal" SG_ 2612194520 PARSEDPushFcGWM_ECGtoCMR 1;
BA_ "U_CD542_MY2021_Tx" SG_ 2612194520 PARSEDPushFcGWM_ECGtoCMR 1;
BA_ "U_U55X_MY2022_Tx" SG_ 2612194520 PARSEDPushFcGWM_ECGtoCMR 1;
BA_ "GenSigSendType" SG_ 2610127035 OTAPhysCMRtoGWM_ECG 3;
BA_ "U_T6_MCA_MY2020_Rx" SG_ 2610127035 OTAPhysCMRtoGWM_ECG 1;
BA_ "ECGUsedRxSignal" SG_ 2610127035 OTAPhysCMRtoGWM_ECG 1;
BA_ "U_CD542_MY2021_Rx" SG_ 2610127035 OTAPhysCMRtoGWM_ECG 1;
BA_ "U_U55X_MY2022_Rx" SG_ 2610127035 OTAPhysCMRtoGWM_ECG 1;
BA_ "U_T6_MCA_MY2020_Tx" SG_ 2610127035 OTAPhysCMRtoGWM_ECG 1;
BA_ "U_CD542_MY2021_Tx" SG_ 2610127035 OTAPhysCMRtoGWM_ECG 1;
BA_ "U_U55X_MY2022_Tx" SG_ 2610127035 OTAPhysCMRtoGWM_ECG 1;
BA_ "U_CD764_MY2022_Tx" SG_ 2610127035 OTAPhysCMRtoGWM_ECG 1;
BA_ "GenSigSendType" SG_ 2610097368 OTAPhysGWM_ECGtoCMR 3;
BA_ "U_T6_MCA_MY2020_Rx" SG_ 2610097368 OTAPhysGWM_ECGtoCMR 1;
BA_ "U_CD542_MY2021_Rx" SG_ 2610097368 OTAPhysGWM_ECGtoCMR 1;
BA_ "U_U55X_MY2022_Rx" SG_ 2610097368 OTAPhysGWM_ECGtoCMR 1;
BA_ "U_CD764_MY2022_Rx" SG_ 2610097368 OTAPhysGWM_ECGtoCMR 1;
BA_ "U_T6_MCA_MY2020_Tx" SG_ 2610097368 OTAPhysGWM_ECGtoCMR 1;
BA_ "ECGUsedTxSignal" SG_ 2610097368 OTAPhysGWM_ECGtoCMR 1;
BA_ "U_CD542_MY2021_Tx" SG_ 2610097368 OTAPhysGWM_ECGtoCMR 1;
BA_ "U_U55X_MY2022_Tx" SG_ 2610097368 OTAPhysGWM_ECGtoCMR 1;
BA_ "U_U55X_MY2022_Rx" SG_ 402 ApaSlotAlrtSet_D_RqDrv 1;
BA_ "U_U55X_MY2022_Rx" SG_ 402 ApaFeat_D_RqDrv 1;
BA_ "U_U55X_MY2022_Rx" SG_ 402 ApaSlotTrgt_D_RqDrv 1;
BA_ "U_U55X_MY2022_Rx" SG_ 402 ApaFeatChange_B_RqDrv 1;
BA_ "U_T6_MCA_MY2020_Rx" SG_ 402 CamraFrntBttn_D_Stat3 1;
BA_ "U_CD542_MY2021_Rx" SG_ 402 CamraFrntBttn_D_Stat3 1;
BA_ "U_U55X_MY2022_Rx" SG_ 402 CamraFrntBttn_D_Stat3 1;
BA_ "U_CD764_MY2022_Rx" SG_ 402 CamraFrntBttn_D_Stat3 1;
BA_ "U_T6_MCA_MY2020_Rx" SG_ 402 PrkAidSwtch_D_RqMnu 1;
BA_ "U_CD542_MY2021_Rx" SG_ 402 PrkAidSwtch_D_RqMnu 1;
BA_ "U_U55X_MY2022_Rx" SG_ 402 PrkAidSwtch_D_RqMnu 1;
BA_ "U_CD764_MY2022_Rx" SG_ 402 PrkAidSwtch_D_RqMnu 1;
BA_ "U_T6_MCA_MY2020_Rx" SG_ 402 ApaSwtch_D_RqMnu 1;
BA_ "U_CD542_MY2021_Rx" SG_ 402 ApaSwtch_D_RqMnu 1;
BA_ "U_U55X_MY2022_Rx" SG_ 402 ApaSwtch_D_RqMnu 1;
BA_ "U_CD764_MY2022_Rx" SG_ 402 ApaSwtch_D_RqMnu 1;
BA_ "U_T6_MCA_MY2020_Rx" SG_ 402 ApaMdeStat_D_RqDrv 1;
BA_ "U_CD542_MY2021_Rx" SG_ 402 ApaMdeStat_D_RqDrv 1;
BA_ "U_U55X_MY2022_Rx" SG_ 402 ApaMdeStat_D_RqDrv 1;
BA_ "U_CD764_MY2022_Rx" SG_ 402 ApaMdeStat_D_RqDrv 1;
BA_ "GenSigSendType" SG_ 2611145944 PARSEDPhysGWM_ECGtoCMR 3;
BA_ "U_T6_MCA_MY2020_Rx" SG_ 2611145944 PARSEDPhysGWM_ECGtoCMR 1;
BA_ "U_CD542_MY2021_Rx" SG_ 2611145944 PARSEDPhysGWM_ECGtoCMR 1;
BA_ "U_U55X_MY2022_Rx" SG_ 2611145944 PARSEDPhysGWM_ECGtoCMR 1;
BA_ "U_CD764_MY2022_Rx" SG_ 2611145944 PARSEDPhysGWM_ECGtoCMR 1;
BA_ "U_T6_MCA_MY2020_Tx" SG_ 2611145944 PARSEDPhysGWM_ECGtoCMR 1;
BA_ "ECGUsedTxSignal" SG_ 2611145944 PARSEDPhysGWM_ECGtoCMR 1;
BA_ "U_CD542_MY2021_Tx" SG_ 2611145944 PARSEDPhysGWM_ECGtoCMR 1;
BA_ "U_U55X_MY2022_Tx" SG_ 2611145944 PARSEDPhysGWM_ECGtoCMR 1;
BA_ "GenSigSendType" SG_ 2611175611 PARSEDPhysCMRtoGWM_ECG 3;
BA_ "U_T6_MCA_MY2020_Rx" SG_ 2611175611 PARSEDPhysCMRtoGWM_ECG 1;
BA_ "ECGUsedRxSignal" SG_ 2611175611 PARSEDPhysCMRtoGWM_ECG 1;
BA_ "U_CD542_MY2021_Rx" SG_ 2611175611 PARSEDPhysCMRtoGWM_ECG 1;
BA_ "U_U55X_MY2022_Rx" SG_ 2611175611 PARSEDPhysCMRtoGWM_ECG 1;
BA_ "U_T6_MCA_MY2020_Tx" SG_ 2611175611 PARSEDPhysCMRtoGWM_ECG 1;
BA_ "U_CD542_MY2021_Tx" SG_ 2611175611 PARSEDPhysCMRtoGWM_ECG 1;
BA_ "U_U55X_MY2022_Tx" SG_ 2611175611 PARSEDPhysCMRtoGWM_ECG 1;
BA_ "U_CD764_MY2022_Tx" SG_ 2611175611 PARSEDPhysCMRtoGWM_ECG 1;
BA_ "GenSigSendType" SG_ 1782 TesterPhysicalReqLDCMA 3;
BA_ "GenSigSendType" SG_ 1791 TesterPhysicalResLDCMB 3;
BA_ "GenSigSendType" SG_ 1790 TesterPhysicalResLDCMA 3;
BA_ "GenSigStartValue" SG_ 553 DistToChrgrBynd_L_Actl 510;
BA_ "U_T6_MCA_MY2020_Rx" SG_ 553 ResetTrip2_B_Rq 1;
BA_ "U_CD764_MY2022_Rx" SG_ 553 ResetTrip2_B_Rq 1;
BA_ "U_T6_MCA_MY2020_Rx" SG_ 553 ResetTrip1_B_Rq 1;
BA_ "U_CD764_MY2022_Rx" SG_ 553 ResetTrip1_B_Rq 1;
BA_ "GenSigSendType" SG_ 1998 TesterPhysicalResSODR 3;
BA_ "U_T6_MCA_MY2020_Tx" SG_ 1998 TesterPhysicalResSODR 1;
BA_ "U_CD542_MY2021_Tx" SG_ 1998 TesterPhysicalResSODR 1;
BA_ "U_U55X_MY2022_Tx" SG_ 1998 TesterPhysicalResSODR 1;
BA_ "U_CD764_MY2022_Tx" SG_ 1998 TesterPhysicalResSODR 1;
BA_ "GenSigSendType" SG_ 1990 TesterPhysicalReqSODR 3;
BA_ "U_T6_MCA_MY2020_Rx" SG_ 1990 TesterPhysicalReqSODR 1;
BA_ "U_CD542_MY2021_Rx" SG_ 1990 TesterPhysicalReqSODR 1;
BA_ "U_U55X_MY2022_Rx" SG_ 1990 TesterPhysicalReqSODR 1;
BA_ "U_CD764_MY2022_Rx" SG_ 1990 TesterPhysicalReqSODR 1;
BA_ "GenSigSendType" SG_ 1996 TesterPhysicalResSODL 3;
BA_ "U_T6_MCA_MY2020_Tx" SG_ 1996 TesterPhysicalResSODL 1;
BA_ "U_CD542_MY2021_Tx" SG_ 1996 TesterPhysicalResSODL 1;
BA_ "U_U55X_MY2022_Tx" SG_ 1996 TesterPhysicalResSODL 1;
BA_ "U_CD764_MY2022_Tx" SG_ 1996 TesterPhysicalResSODL 1;
BA_ "GenSigSendType" SG_ 1988 TesterPhysicalReqSODL 3;
BA_ "U_T6_MCA_MY2020_Rx" SG_ 1988 TesterPhysicalReqSODL 1;
BA_ "U_CD542_MY2021_Rx" SG_ 1988 TesterPhysicalReqSODL 1;
BA_ "U_U55X_MY2022_Rx" SG_ 1988 TesterPhysicalReqSODL 1;
BA_ "U_CD764_MY2022_Rx" SG_ 1988 TesterPhysicalReqSODL 1;
VAL_ 1089 Mtr2Aout_W_ActlMntr 1023 "Faulty" ;
VAL_ 1089 Inv1_Te_Actl 255 "Faulty" 254 "NoDataExists" ;
VAL_ 1089 MtrTrac2Coil_Te_Actl 255 "Faulty" 254 "NoDataExists" ;
VAL_ 1089 MtrTrac2Falt_B_Stat 1 "Active" 0 "Inactive" ;
VAL_ 1089 MtrTrac2TeAlrm_B_Stat 1 "Active" 0 "Inactive" ;
VAL_ 1089 Mtr2CntlTeAlrm_B_Stat 1 "Active" 0 "Inactive" ;
VAL_ 1089 MtrTrac2Inv_Te_Actl 255 "Faulty" 254 "NoDataExists" ;
VAL_ 1089 MtrTrac2_I_Actl 65535 "Faulty" ;
VAL_ 776 ScChrgrPwMax_Pw_RqCld 4095 "Faulty" ;
VAL_ 776 PrcondEdit_D_RqCld 7 "NotUsed_3" 6 "NotUsed_2" 5 "NotUsed_1" 4 "High" 3 "Medium" 2 "Low" 1 "Off" 0 "Null" ;
VAL_ 776 GoTEditMnte_T_RqCld 15 "Faulty" 14 "NoDataExists" 13 "NotUsed_2" 12 "NotUsed_1" 11 "Minute_55" 10 "Minute_50" 9 "Minute_45" 8 "Minute_40" 7 "Minute_35" 6 "Minute_30" 5 "Minute_25" 4 "Minute_20" 3 "Minute_15" 2 "Minute_10" 1 "Minute_5" 0 "Minute_0" ;
VAL_ 776 GoTEditHr_T_RqCld 31 "Faulty" 30 "NoDataExists" ;
VAL_ 776 ChrgToPcEdit_Pc_RqCld 127 "Faulty" 126 "NoDataExists" ;
VAL_ 776 ScFreshDataEnbl_B_Rq 1 "Yes" 0 "No" ;
VAL_ 776 ScEnbl_D_RqCld 3 "NotUsed" 2 "On" 1 "Off" 0 "Null" ;
VAL_ 1088 TrlrRng_L_Dsply 8191 "Faulty" 8190 "NoDataExists" ;
VAL_ 1088 BattDcChrgRms_I_Lim 32767 "Faulty" 32766 "NoDataExists" ;
VAL_ 1088 ChrgStat_D2_Dsply 15 "ChargeStopCommanded" 14 "ChargeStartCommanded" 13 "ChargeTargetReached" 12 "DriveConditioning" 11 "CabinPreconditioning" 10 "ChargingSystemMaintain" 9 "ChargingInductive" 8 "ChargingDCFastCharge" 7 "ChargingAC" 6 "ChargeScheduled" 5 "EvsePaused" 4 "EvseNotDetected" 3 "EvseNotCompatible" 2 "FaultOutsideCar" 1 "FaultInsideCar" 0 "NotReady" ;
VAL_ 1088 ChrgTMatch_B_Stat 1 "True" 0 "False" ;
VAL_ 1088 HvacPrecondRecirc_D_Rq 3 "Last_User_Setting" 2 "Auto" 1 "Recirc" 0 "Outside" ;
VAL_ 1088 HvacPrecondMode2_D_Rq 15 "NotUsed4" 14 "NotUsed3" 13 "NotUsed2" 12 "NotUsed1" 11 "Last_User_Settings" 10 "Auto" 9 "Max_Defrost" 8 "Windshield_Panel_Floor" 7 "Windshield_Panel" 6 "Windshield" 5 "Windshield_Floor" 4 "Floor" 3 "Panel_Floor" 2 "Panel" 1 "MAX_AC" 0 "Off" ;
VAL_ 1088 HvacPrecondBlwr2_D_Rq 15 "NotUsed6" 14 "NotUsed5" 13 "NotUsed4" 12 "NotUsed3" 11 "NotUsed2" 10 "NotUsed1" 9 "Last_User_Setting" 8 "Auto" 7 "Speed7" 6 "Speed6" 5 "Speed5" 4 "Speed4" 3 "Speed3" 2 "Speed2" 1 "Speed1" 0 "Off" ;
VAL_ 1088 HvacPrecondAC_D_Rq 3 "Last_User_Setting" 2 "Auto" 1 "On" 0 "Off" ;
VAL_ 1088 BattChrgInhbt_D_Rq 3 "MaintainTargetSoc" 2 "NotUsed" 1 "InhibitChargingThermal" 0 "Enable_Charging" ;
VAL_ 850 VehElRngeNut_L2_Dsply 8191 "Faulty" 8190 "NoDataExists" ;
VAL_ 850 VehElRngeNut_L_Dsply 4095 "Faulty" 4094 "NoDataExists" ;
VAL_ 850 NxtUsgSocEst_Pc_Dsply 255 "Faulty" 254 "NoDataExists" ;
VAL_ 850 EstmChrgTimeLP_St 255 "Invalid" ;
VAL_ 850 EstmChrgTimeHP_St 255 "Invalid" ;
VAL_ 850 ChargeNowDuration_St 255 "Invalid" ;
VAL_ 981 AdbBrdrTop_An_Rq 255 "Faulty" 254 "NoDataExists" ;
VAL_ 981 AdbBrdrRight_L_Stat 511 "Faulty" 510 "NoDataExists" ;
VAL_ 981 AdbBrdrRight_An_Rq 1023 "Faulty" 1022 "NoDataExists" ;
VAL_ 981 AdbBrdrLeft_L_Stat 511 "Faulty" 510 "NoDataExists" ;
VAL_ 981 AdbBrdrLeft_An_Rq 1023 "Faulty" 1022 "NoDataExists" ;
VAL_ 981 AdbBrdrBottom_An_Rq 63 "Faulty" 62 "NoDataExists" ;
VAL_ 981 AdbBeam_D_Rq 7 "NotUsed_3" 6 "NotUsed_2" 5 "NotUsed_1" 4 "FullHighBeam" 3 "Spot_BothSide" 2 "Spot_OnlyRightSide" 1 "Spot_OnlyLeftSide" 0 "NoHighBeam" ;
VAL_ 810 VehHorn_B_RqOccAlrt 1 "On" 0 "Off" ;
VAL_ 810 RmtViewMde_B_Rq 1 "On" 0 "Off" ;
VAL_ 810 DteCldAcceptData_B_Rq 1 "Yes" 0 "No" ;
VAL_ 810 DteCldCnclRoute_B_Rq 1 "Yes" 0 "No" ;
VAL_ 810 PtRmtRprt_D_Stat 15 "NotUsed_4" 14 "NotUsed_3" 13 "NotUsed_2" 12 "PlugInToMaintain12vBattery" 11 "SettingUpdated" 10 "FastChargeComplete" 9 "ChargeNotOccurring" 8 "OneTimeSocReached" 7 "BatteryTemperatureRemind" 6 "ReducedPerformance" 5 "LimitedPerformance" 4 "ChargeFault" 3 "ChargeComplete" 2 "VehiclePreconditioned" 1 "TripDistanceAchieved" 0 "NoReportRequest" ;
VAL_ 810 ChrgrPncEnbl_D_Rq 3 "NotUsed" 2 "Enable" 1 "Disable" 0 "Null" ;
VAL_ 810 OneTEditActv_B_RqCld 1 "Yes" 0 "No" ;
VAL_ 810 OBCCSerial_D_Rq 3 "PresentAndProvisioned" 2 "PresentAndProvAlertAck" 1 "PresentAndUnprovisioned" 0 "NotPresent" ;
VAL_ 810 ExtLghtDsply_B_StatArb 1 "On" 0 "Off" ;
VAL_ 810 ExtLghtRight_D_RqOta 7 "NotUsed" 6 "PressToOn3" 5 "PressToOff3" 4 "PressToOn2" 3 "PressToOff2" 2 "PressToOn1" 1 "PressToOff1" 0 "Reset" ;
VAL_ 810 ExtLghtRear_D_RqOta 7 "NotUsed" 6 "PressToOn3" 5 "PressToOff3" 4 "PressToOn2" 3 "PressToOff2" 2 "PressToOn1" 1 "PressToOff1" 0 "Reset" ;
VAL_ 810 ExtLghtLeft_D_RqOta 7 "NotUsed" 6 "PressToOn3" 5 "PressToOff3" 4 "PressToOn2" 3 "PressToOff2" 2 "PressToOn1" 1 "PressToOff1" 0 "Reset" ;
VAL_ 810 ExtLghtFront_D_RqOta 7 "NotUsed" 6 "PressToOn3" 5 "PressToOff3" 4 "PressToOn2" 3 "PressToOff2" 2 "PressToOn1" 1 "PressToOff1" 0 "Reset" ;
VAL_ 810 TlghtTest_D_RqArb 3 "TestEndAcknowledge" 2 "StartTest" 1 "StopTest" 0 "Null" ;
VAL_ 810 ChrgrPncSustn_B_Rq 1 "Active" 0 "Inactive" ;
VAL_ 563 BattChrgStrtStop_D2_Rq 15 "NotUsed_8" 14 "NotUsed_7" 13 "NotUsed_6" 12 "NotUsed_5" 11 "NotUsed_4" 10 "NotUsed_3" 9 "NotUsed_2" 8 "NotUsed_1" 7 "GridStopChargingPartial" 6 "GridStopChargingMandatory" 5 "GridStartChargingFree" 4 "GridStartChargingPreferred" 3 "ReturnToSettings" 2 "StopCharge" 1 "StartCharge" 0 "NoNewRequest" ;
VAL_ 563 DrvBhavAudioAlrt_D_Rq 58 "NotUsed_51" 57 "NotUsed_50" 56 "NotUsed_49" 55 "NotUsed_48" 54 "NotUsed_47" 53 "NotUsed_46" 52 "NotUsed_45" 25 "NotUsed_18" 24 "NotUsed_17" 23 "NotUsed_16" 22 "NotUsed_15" 21 "NotUsed_14" 20 "NotUsed_13" 19 "NotUsed_12" 18 "NotUsed_11" 17 "NotUsed_10" 16 "NotUsed_9" 15 "NotUsed_8" 14 "NotUsed_7" 13 "NotUsed_6" 12 "NotUsed_5" 11 "NotUsed_4" 10 "NotUsed_3" 9 "NotUsed_2" 8 "NotUsed_1" 7 "ExcessiveIdleAndUnbuckled" 6 "ExcessiveSpeedAndUnbuckled" 5 "SeatbeltUnbuckled" 4 "HardBrakingBegin" 3 "HardAccelerationBegin" 2 "ExcessiveSpeedBegin" 1 "ExcessiveIdleBegin" 0 "NoMessage" 63 "NotUsed_56" 62 "NotUsed_55" 61 "NotUsed_54" 60 "NotUsed_53" 59 "NotUsed_52" ;
VAL_ 563 NtfyDrvTrgtDist_L2_Rq 8191 "Faulty" 8190 "NoDataExists" ;
VAL_ 563 BattChrgStrtStop_D_Rq 3 "ReturnToSettings" 2 "StopCharge" 1 "StartCharge" 0 "NoNewRequest" ;
VAL_ 563 DrvBhavWarn_B_Rq 1 "On" 0 "Off" ;
VAL_ 563 OfbChrgSetSync_D_Rq 3 "Fail" 2 "Success" 1 "InProgress" 0 "NoSyncInProgress" ;
VAL_ 563 KeyOffPwMde_D_Stat 7 "NotUsed_6" 6 "NotUsed_5" 5 "NotUsed_4" 4 "NotUsed_3" 0 "Inactive" 1 "On" 2 "NotUsed_1" 3 "NotUsed_2" ;
VAL_ 563 ModemReset_D_Stat 15 "NotUsed_10" 14 "NotUsed_9" 13 "NotUsed_8" 12 "NotUsed_7" 11 "NotUsed_6" 10 "NotUsed_5" 9 "NotUsed_4" 8 "NotUsed_3" 7 "NotUsed_2" 6 "NotUsed_1" 5 "WifiHotSpotResetComplete" 4 "CcsResetComplete" 3 "OnlineTrafficResetComplete" 2 "PaakResetComplete" 1 "ResetNotComplete" 0 "Null" ;
VAL_ 563 FactoryReset_St 3 "NotUsed_2" 2 "NotUsed_1" 1 "FactoryDefaultsRestored" 0 "Null" ;
VAL_ 1119 CoolFanDcdc_D_Rq 3 "High" 2 "Medium" 1 "Low" 0 "Off" ;
VAL_ 1119 DcdcClntFlw_D_Rq 3 "High" 2 "Medium" 1 "Low" 0 "Off" ;
VAL_ 1119 PwrSrcULo_Te_Actl 1023 "Faulty" 1022 "NoDataExists" ;
VAL_ 1119 PtLatchActv_B_RqDcdc 1 "On" 0 "Off" ;
VAL_ 912 GearPrkMtr_D_Stat 7 "NotUsed_1" 6 "FetLifeLimitReached" 5 "FetOpenCircuit" 4 "FetOutputShortToPower" 3 "FetOutputShortToGround" 2 "FetNotControlled" 1 "OnPowerToLoad" 0 "OffNoPowerToLoad" ;
VAL_ 912 GearPrkLck_D_Stat 7 "NotUsed_1" 6 "FetLifeLimitReached" 5 "FetOpenCircuit" 4 "FetOutputShortToPower" 3 "FetOutputShortToGround" 2 "FetNotControlled" 1 "OnPowerToLoad" 0 "OffNoPowerToLoad" ;
VAL_ 912 HeatCoreSovRear_D_Stat 7 "FetLowSideOpenOrShort" 6 "FetLifeLimitReached" 5 "FetOpenCircuit" 4 "FetOutputShortToPower" 3 "FetOutputShortToGround" 2 "FetNotControlled" 1 "OnPowerToLoad" 0 "OffNoPowerToLoad" ;
VAL_ 912 CabnEvapSovRear_D_Stat 7 "NotUsed_1" 6 "FetLifeLimitReached" 5 "FetOpenCircuit" 4 "FetOutputShortToPower" 3 "FetOutputShortToGround" 2 "FetNotControlled" 1 "OnPowerToLoad" 0 "OffNoPowerToLoad" ;
VAL_ 912 CabnEvapSovFront_D_Stat 7 "NotUsed_1" 6 "FetLifeLimitReached" 5 "FetOpenCircuit" 4 "FetOutputShortToPower" 3 "FetOutputShortToGround" 2 "FetNotControlled" 1 "OnPowerToLoad" 0 "OffNoPowerToLoad" ;
VAL_ 912 BattTracSov_D_Stat 7 "NotUsed_1" 6 "FetLifeLimitReached" 5 "FetOpenCircuit" 4 "FetOutputShortToPower" 3 "FetOutputShortToGround" 2 "FetNotControlled" 1 "OnPowerToLoad" 0 "OffNoPowerToLoad" ;
VAL_ 912 BattChlrSov_D_Stat 7 "NotUsed_1" 6 "FetLifeLimitReached" 5 "FetOpenCircuit" 4 "FetOutputShortToPower" 3 "FetOutputShortToGround" 2 "FetNotControlled" 1 "OnPowerToLoad" 0 "OffNoPowerToLoad" ;
VAL_ 912 BattTracClntVlv_D_Stat 7 "FetLowSideOpenOrShort" 6 "FetLifeLimitReached" 5 "FetOpenCircuit" 4 "FetOutputShortToPower" 3 "FetOutputShortToGround" 2 "FetNotControlled" 1 "OnPowerToLoad" 0 "OffNoPowerToLoad" ;
VAL_ 912 AdasRelay_B_Stat 1 "On" 0 "Off" ;
VAL_ 651 TelematicsSrvc_D_St 7 "NotUsed" 6 "NotifyNotActivatedYet" 5 "NotActivatedYet" 4 "NotifyExpired" 3 "Expired" 2 "ExpiringSoon" 1 "Active" 0 "Null" ;
VAL_ 651 EmgcyCallMute_D_Stat 7 "NotUsed4" 6 "NotUsed3" 5 "NotUsed2" 4 "NotUsed1" 3 "ManualEmergencyCallMute" 2 "AutomaticEmergencyCallMute" 1 "EmergencyCallUnmute" 0 "Null" ;
VAL_ 529 OnbChrgToPcWknd_D_Actl 7 "Percent_50" 6 "Percent_60" 5 "Percent_70" 4 "Percent_80" 3 "Percent_85" 2 "Percent_90" 1 "Percent_95" 0 "Percent_100" ;
VAL_ 529 OnbChrgToPcWkdy_D_Actl 7 "Percent_50" 6 "Percent_60" 5 "Percent_70" 4 "Percent_80" 3 "Percent_85" 2 "Percent_90" 1 "Percent_95" 0 "Percent_100" ;
VAL_ 529 OnbChrgSetNow_D_Rq 3 "NotUsed" 2 "On" 1 "Off" 0 "Null" ;
VAL_ 529 OnbChrgSetDelete_B_Rq 1 "Request" 0 "NoRequest" ;
VAL_ 529 OnbChrgPrflUpdate_B_Rq 1 "Request" 0 "NoRequest" ;
VAL_ 529 OnbChrgLocIdUns_B_Rq 1 "Request" 0 "NoRequest" ;
VAL_ 1143 ConsTipUnitPt_D_Dsply 3 "NotUsed" 2 "FuelEconomy" 1 "Distance" 0 "Percentage" ;
VAL_ 1143 ConsTipTot_Pc_Dsply 1023 "Faulty" 1022 "NoDataExists" ;
VAL_ 1143 ChrgCompltMsgTxt_D_Rq 3 "NotUsed_1" 2 "ChargeToFull" 1 "ChargeToFastChargeLimit" 0 "DefaultLabel" ;
VAL_ 1142 ConsTipV_No_Dsply 1023 "Faulty" 1022 "NoDataExists" ;
VAL_ 1142 ConsTipMsg3_D_Dsply 15 "NotUsed10" 14 "NotUsed9" 13 "NotUsed8" 12 "NotUsed7" 11 "NotUsed6" 10 "NotUsed5" 9 "NotUsed4" 8 "NotUsed3" 7 "NotUsed2" 6 "NotUsed1" 5 "ReduceIdleTime" 4 "ClimateUsage" 3 "VehicleSpeed" 2 "Deceleration" 1 "Acceleration" 0 "NoDisplay" ;
VAL_ 1142 ConsTipMsg2_D_Dsply 15 "NotUsed10" 14 "NotUsed9" 13 "NotUsed8" 12 "NotUsed7" 11 "NotUsed6" 10 "NotUsed5" 9 "NotUsed4" 8 "NotUsed3" 7 "NotUsed2" 6 "NotUsed1" 5 "ReduceIdleTime" 4 "ClimateUsage" 3 "VehicleSpeed" 2 "Deceleration" 1 "Acceleration" 0 "NoDisplay" ;
VAL_ 1142 ConsTipMsg1_D_Dsply 15 "NotUsed10" 14 "NotUsed9" 13 "NotUsed8" 12 "NotUsed7" 11 "NotUsed6" 10 "NotUsed5" 9 "NotUsed4" 8 "NotUsed3" 7 "NotUsed2" 6 "NotUsed1" 5 "ReduceIdleTime" 4 "ClimateUsage" 3 "VehicleSpeed" 2 "Deceleration" 1 "Acceleration" 0 "NoDisplay" ;
VAL_ 1142 ConsTipDecel_No_Dsply 1023 "Faulty" 1022 "NoDataExists" ;
VAL_ 1142 ConsTipA_No_Dsply 1023 "Faulty" 1022 "NoDataExists" ;
VAL_ 1141 AirAmbTePlgIn_D_Dsply 3 "NotUsed" 2 "Hot_Outside_Plg_In_Msg" 1 "Cold_Outside_Plg_In_Msg" 0 "No_Plg_In_Msg" ;
VAL_ 1141 OfbChrgSetSync_D_Stat 3 "Fail" 2 "Success" 1 "InProgress" 0 "NoSyncInProgress" ;
VAL_ 1141 PtRmtRprt_D_Rq 15 "NotUsed_4" 14 "NotUsed_3" 13 "NotUsed_2" 12 "PlugInToMaintain12vBattery" 11 "SettingUpdated" 10 "FastChargeComplete" 9 "ChargeNotOccurring" 8 "OneTimeSocReached" 7 "BatteryTemperatureReminder" 6 "ReducedPerformance" 5 "LimitedPerformance" 4 "ChargeFault" 3 "ChargeComplete" 2 "VehiclePreconditioned" 1 "TripDistanceAchieved" 0 "NoReportRequest" ;
VAL_ 1141 NxtUsg_D_Rq 0 "Invalid" 1 "Not_Requested" 2 "Requested" 3 "NotUsed" ;
VAL_ 1141 NtfctnConflict1_D_Rq 7 "NotUsed_4" 6 "NotUsed_3" 5 "NotUsed_2" 4 "NotUsed_1" 3 "ChargeWindow" 2 "DepartureTime" 1 "NoConflictExists" 0 "Null" ;
VAL_ 1141 ChrgLocGPS_D_Rq 0 "Inactive" 1 "Not_Requested" 2 "Requested" 3 "NotUsed" ;
VAL_ 1140 RgenLongTerm_L_Dsply 16777215 "Faulty" 16777214 "NoDataExists" ;
VAL_ 1140 PreCondStat_D_Dsply 7 "Reserved3" 6 "Reserved2" 5 "Reserved1" 4 "Faulted" 3 "Complete" 2 "In_Progress" 1 "Scheduled" 0 "Not_Scheduled" ;
VAL_ 1140 RgenEvntLvl_Pc_Dsply 1023 "Fault" 1022 "NoDataExists" ;
VAL_ 1140 BrkEvntComplt_B_Dsply 1 "On" 0 "Off" ;
VAL_ 1140 ExtChrgrFalt_B_Dsply 1 "Yes" 0 "No" ;
VAL_ 1139 BattChrgTrgtLMax_T_Est 2047 "Faulty" 2046 "NoDataExists" ;
VAL_ 1139 ActChrgStrtYr_No_Actl 31 "Invalid" ;
VAL_ 1139 ActChrgStrtMin_No_Actl 63 "Invalid" 62 "Unknown" ;
VAL_ 1139 ActChrgStrtHr_No_Actl 31 "Invalid" 30 "Unknown" ;
VAL_ 1139 ActChrgStrtDay_No_Actl 31 "Invalid" ;
VAL_ 1139 ActChrgStrMnth_No_Actl 15 "Invalid" ;
VAL_ 1138 BattChrgTrgtLMin_T_Est 2047 "Faulty" 2046 "NoDataExists" ;
VAL_ 1138 ActChrgEndYr_No_Actl 31 "Invalid" ;
VAL_ 1138 ActChrgEndMnth_No_Actl 15 "Invalid" ;
VAL_ 1138 ActChrgEndMin_No_Actl 63 "Invalid" 62 "Unknown" ;
VAL_ 1138 ActChrgEndHr_No_Actl 31 "Invalid" 30 "Unknown" ;
VAL_ 1138 ActChrgEndDay_No_Actl 31 "Invalid" ;
VAL_ 1016 ChrgGoTElement_B_Dsply 1 "Yes" 0 "No" ;
VAL_ 1016 ChrgGoTTouchEnbl_B_Rq 1 "Request" 0 "NoRequest" ;
VAL_ 1016 ChrgGoTTouch_B_Stat 1 "On" 0 "Off" ;
VAL_ 1016 ChrgGoTPrcond_D_Stat 3 "High" 2 "Medium" 1 "Low" 0 "Off" ;
VAL_ 1016 ChrgGoTMnte_D_Stat 15 "NotUsed_4" 14 "NotUsed_3" 13 "NotUsed_2" 12 "NotUsed_1" 11 "Minute_55" 10 "Minute_50" 9 "Minute_45" 8 "Minute_40" 7 "Minute_35" 6 "Minute_30" 5 "Minute_25" 4 "Minute_20" 3 "Minute_15" 2 "Minute_10" 1 "Minute_5" 0 "Minute_0" ;
VAL_ 1016 ChrgGoTHr_T_Stat 31 "Faulty" 30 "NoDataExists" ;
VAL_ 1016 ChrgGoTExtHtrEnbl_B_Rq 1 "Request" 0 "NoRequest" ;
VAL_ 1016 ChrgGoTExtHtr_B_Stat 1 "On" 0 "Off" ;
VAL_ 1016 ChrgGoTAllOn_B_Stat 1 "On" 0 "Off" ;
VAL_ 1013 ChrgToPcWkndSav_D_Stat 7 "Percent_50" 6 "Percent_60" 5 "Percent_70" 4 "Percent_80" 3 "Percent_85" 2 "Percent_90" 1 "Percent_95" 0 "Percent_100" ;
VAL_ 1013 ChrgToPcWkdySav_D_Stat 7 "Percent_50" 6 "Percent_60" 5 "Percent_70" 4 "Percent_80" 3 "Percent_85" 2 "Percent_90" 1 "Percent_95" 0 "Percent_100" ;
VAL_ 1013 ChrgNowEnbl_B_Saved 1 "On" 0 "Off" ;
VAL_ 1013 ChrgLocIdUnsAck_B_Stat 1 "Yes" 0 "No" ;
VAL_ 1012 ChrgLocSaved_B_Dsply 1 "Yes" 0 "No" ;
VAL_ 1012 ChrgLocLongPostv_B_Sav 1 "Yes" 0 "No" ;
VAL_ 1012 ChrgLocLattPostv_B_Sav 1 "Yes" 0 "No" ;
VAL_ 1012 ChrgNowCurnt_B_Dsply 1 "On" 0 "Off" ;
VAL_ 1011 ChrgLocLongPostv_B_Uns 1 "Yes" 0 "No" ;
VAL_ 1011 ChrgLocLattPostv_B_Uns 1 "Yes" 0 "No" ;
VAL_ 1049 Chrgr_Pw_EstMx 511 "Faulty" 510 "NoDataExists" ;
VAL_ 1049 PersTurnSglView_D_RqMnu 3 "NotUsed" 2 "Enable" 1 "Disable" 0 "Null" ;
VAL_ 1049 FrontDiffLck_D_RqDrv3 3 "Faulty" 2 "NoRequest" 1 "On" 0 "Off" ;
VAL_ 1049 RearDiffLck_D_RqDrv3 3 "Faulty" 2 "NoRequest" 1 "On" 0 "Off" ;
VAL_ 1049 TrailCtlSwtch_B_Stat4 1 "Pressed" 0 "Not_Pressed" ;
VAL_ 1049 CamraFrnt_B_RqMnu 1 "On" 0 "Off" ;
VAL_ 1049 StabBarCnncButtn_D_Sta3 3 "Faulty" 2 "NotUsed" 1 "Pressed" 0 "Not_Pressed" ;
VAL_ 1049 TurnAsstSwtch_D_Stat 3 "Faulty" 2 "NotUsed" 1 "Pressed" 0 "Not_Pressed" ;
VAL_ 1049 SelDrvMdeTxtRst_B_Rq2 1 "Yes" 0 "No" ;
VAL_ 1049 SelDrvMdePage_B_Stat 1 "Active" 0 "Inactive" ;
VAL_ 1049 SelDrvMdeCnfm_D_Stat2 3 "NotUsed" 2 "Accepted" 1 "NotAccepted" 0 "Null" ;
VAL_ 1049 SelDrvMde_D_RqDrv 31 "Faulty" 30 "SelDrvMde31" 29 "SelDrvMde30" 28 "SelDrvMde29" 27 "SelDrvMde28" 26 "SelDrvMde27" 25 "SelDrvMde26" 24 "SelDrvMde25" 23 "SelDrvMde24" 22 "SelDrvMde23" 21 "SelDrvMde22" 20 "SelDrvMde21" 19 "SelDrvMde20" 18 "SelDrvMde19" 17 "SelDrvMde18" 16 "SelDrvMde17" 15 "SelDrvMde16" 14 "SelDrvMde15" 13 "SelDrvMde14" 12 "SelDrvMde13" 11 "SelDrvMde12" 10 "SelDrvMde11" 9 "SelDrvMde10" 8 "SelDrvMde09" 7 "SelDrvMde08" 6 "SelDrvMde07" 5 "SelDrvMde06" 4 "SelDrvMde05" 3 "SelDrvMde04" 2 "SelDrvMde03" 1 "SelDrvMde02" 0 "SelDrvMde01" ;
VAL_ 775 ScDayOfWeekId_D_RqCld 7 "Sunday" 6 "Saturday" 5 "Friday" 4 "Thursday" 3 "Wednesday" 2 "Tuesday" 1 "Monday" 0 "NotUsed" ;
VAL_ 775 ScChrgDurSet_D_RqCld 3 "NotUsed" 2 "On" 1 "Off" 0 "Null" ;
VAL_ 775 ScChrgDur_T_RqCld 2047 "Faulty" 2046 "NoDataExists" ;
VAL_ 774 ScLocLongPostv_B_RqCld 1 "Yes" 0 "No" ;
VAL_ 774 ScLocLattPostv_B_RqCld 1 "Yes" 0 "No" ;
VAL_ 774 ScLocDelete_B_RqCld 1 "Request" 0 "NoRequest" ;
VAL_ 943 VehVActlAdas_D_Qf 3 "OK" 2 "Not_Within_Specifications" 1 "No_Data_Exists" 0 "Faulty" ;
VAL_ 943 AdasLcDistToObj_L_Actl 4095 "Faulty" 4094 "NoDataExists" ;
VAL_ 930 BalrWndwRight_B_Stat 1 "Enable" 0 "Disable" ;
VAL_ 930 BalrSnsRight_D_Falt 3 "Invalid" 2 "SystemFailure" 1 "Blocked" 0 "Clear" ;
VAL_ 930 WndwPsngrRear_D_RqBalrr 3 "NotUsed" 2 "Stop" 1 "AutoUp" 0 "NoRequest" ;
VAL_ 930 WndwPsngr_D_RqBalrr 3 "NotUsed" 2 "Stop" 1 "AutoUp" 0 "NoRequest" ;
VAL_ 930 WndwDrvRear_D_RqBalrr 3 "NotUsed" 2 "Stop" 1 "AutoUp" 0 "NoRequest" ;
VAL_ 930 WndwDrv_D_RqBalrr 3 "NotUsed" 2 "Stop" 1 "AutoUp" 0 "NoRequest" ;
VAL_ 930 BalrRight_D_Stat 3 "Inhibited" 2 "Disabled" 1 "On" 0 "Off" ;
VAL_ 930 BalrMdeSelRight_B_Stat 1 "Enable" 0 "Disable" ;
VAL_ 930 BalrMdeRight_D_Stat 3 "NotUsed" 2 "High" 1 "Medium" 0 "Low" ;
VAL_ 930 BalrLckRight_B_Stat 1 "Enable" 0 "Disable" ;
VAL_ 930 BalrChimeRight_D_Rq 3 "NotUsed" 2 "Soft" 1 "Normal" 0 "Off" ;
VAL_ 930 CamraRearOn_B_RqBalrr 1 "Active" 0 "Inactive" ;
VAL_ 930 DrLckActv_B_RqBalrr 1 "Active" 0 "Null" ;
VAL_ 929 BalrChimeLeft_D_Rq 3 "NotUsed" 2 "Soft" 1 "Normal" 0 "Off" ;
VAL_ 929 BalrLeft_D_Stat 3 "Inhibited" 2 "Disabled" 1 "On" 0 "Off" ;
VAL_ 929 WndwPsngrRear_D_RqBalrl 3 "NotUsed" 2 "Stop" 1 "AutoUp" 0 "NoRequest" ;
VAL_ 929 WndwPsngr_D_RqBalrl 3 "NotUsed" 2 "Stop" 1 "AutoUp" 0 "NoRequest" ;
VAL_ 929 WndwDrvRear_D_RqBalrl 3 "NotUsed" 2 "Stop" 1 "AutoUp" 0 "NoRequest" ;
VAL_ 929 WndwDrv_D_RqBalrl 3 "NotUsed" 2 "Stop" 1 "AutoUp" 0 "NoRequest" ;
VAL_ 929 BalrSnsLeft_D_Falt 3 "Invalid" 2 "SystemFailure" 1 "Blocked" 0 "Clear" ;
VAL_ 929 BalrMdeSelLeft_B_Stat 1 "Enable" 0 "Disable" ;
VAL_ 929 BalrMdeLeft_D_Stat 3 "NotUsed" 2 "High" 1 "Medium" 0 "Low" ;
VAL_ 929 BalrLckLeft_B_Stat 1 "Enable" 0 "Disable" ;
VAL_ 929 CamraRearOn_B_RqBalrl 1 "Active" 0 "Inactive" ;
VAL_ 929 DrLckActv_B_RqBalrl 1 "Active" 0 "Null" ;
VAL_ 929 BalrWndwLeft_B_Stat 1 "Enable" 0 "Disable" ;
VAL_ 402 ApaSlotAlrtSet_D_RqDrv 3 "TemporarySuppression" 2 "Disable" 1 "Enable" 0 "None" ;
VAL_ 402 ApaFeat_D_RqDrv 7 "Faulty" 6 "Off" 5 "RePA" 4 "ParkIn" 3 "POA" 2 "PPA" 1 "SAPP" 0 "Inactive" ;
VAL_ 402 ApaSlotTrgt_D_RqDrv 15 "NotUsed_7" 14 "NotUsed_6" 13 "NotUsed_5" 12 "NotUsed_4" 11 "NotUsed_3" 10 "NotUsed_2" 9 "NotUsed_1" 8 "Front" 7 "Rear" 6 "Right3" 5 "Right2" 4 "Right1" 3 "Left3" 2 "Left2" 1 "Left1" 0 "None" ;
VAL_ 402 ApaFeatChange_B_RqDrv 1 "True" 0 "False" ;
VAL_ 402 CamraFrntBttn_D_Stat3 1 "Pressed" 0 "Not_Pressed" ;
VAL_ 402 PrkAidSwtch_D_RqMnu 1 "Pressed" 0 "Not_Pressed" ;
VAL_ 402 ApaSwtch_D_RqMnu 3 "NotUsed2" 2 "NotUsed1" 1 "Pressed" 0 "Not_Pressed" ;
VAL_ 402 ApaMdeStat_D_RqDrv 7 "Faulty" 6 "Off" 5 "NotUsed2" 4 "NotUsed1" 3 "POA" 2 "PPA" 1 "SAPP" 0 "Inactive" ;
VAL_ 402 CamraViewSplit_B_Rq 1 "On" 0 "Off" ;
VAL_ 402 CamraZoomMan_D_Rq 7 "Unknown" 6 "Invalid" 5 "Zoom_Level_V" 4 "Zoom_Level_IV" 3 "Zoom_Level_III" 2 "Zoom_Level_II" 1 "Zoom_Level_I" 0 "Off" ;
VAL_ 402 CamraOvrlStat_D_Rq 1 "On" 0 "Off" ;
VAL_ 402 CamraOvrlDyn_D_Rq 1 "On" 0 "Off" ;
VAL_ 402 CamAutoTowbarZoom 1 "On" 0 "Off" ;
VAL_ 402 DistanceBarSetting 1 "On" 0 "Off" ;
VAL_ 553 DistToChrgrBynd_L_Actl 511 "Faulty" 510 "NoDataExists" ;
VAL_ 553 CCOI_PolicyClient_St 15 "NotUsed_4" 14 "NotUsed_3" 13 "NotUsed_2" 12 "NotUsed_1" 11 "DataStorageError" 10 "StateMachineInconsistent" 9 "UnrecoverableSyncError" 8 "OnBoardSyncFailed" 7 "OnBoardImplemented" 6 "OnBoardSynchronized" 5 "OnBoardSynchronizing" 4 "OnBoardSyncNeeded" 3 "OffBoardUpdatePending" 2 "OnBoardUpdatePending" 1 "Waiting" 0 "Null" ;
VAL_ 553 ResetAvgFe_B_Rq 1 "Reset" 0 "Null" ;
VAL_ 553 ResetTrip2_B_Rq 1 "Reset" 0 "Null" ;
VAL_ 553 SndImmrsnLvl_D_Rq 255 "NotUsed_127" 254 "NotUsed_126" 253 "NotUsed_125" 252 "NotUsed_124" 251 "NotUsed_123" 250 "NotUsed_122" 249 "NotUsed_121" 248 "NotUsed_120" 247 "NotUsed_119" 246 "NotUsed_118" 245 "NotUsed_117" 244 "NotUsed_116" 243 "NotUsed_115" 242 "NotUsed_114" 241 "NotUsed_113" 240 "NotUsed_112" 239 "NotUsed_111" 238 "NotUsed_110" 237 "NotUsed_109" 236 "NotUsed_108" 235 "NotUsed_107" 234 "NotUsed_106" 233 "NotUsed_105" 232 "NotUsed_104" 231 "NotUsed_103" 230 "NotUsed_102" 229 "NotUsed_101" 228 "NotUsed_100" 227 "NotUsed_99" 226 "NotUsed_98" 225 "NotUsed_97" 224 "NotUsed_96" 223 "NotUsed_95" 222 "NotUsed_94" 221 "NotUsed_93" 220 "NotUsed_92" 219 "NotUsed_91" 218 "NotUsed_90" 217 "NotUsed_89" 216 "NotUsed_88" 215 "NotUsed_87" 214 "NotUsed_86" 213 "NotUsed_85" 212 "NotUsed_84" 211 "NotUsed_83" 210 "NotUsed_82" 209 "NotUsed_81" 208 "NotUsed_80" 207 "NotUsed_79" 206 "NotUsed_78" 205 "NotUsed_77" 204 "NotUsed_76" 203 "NotUsed_75" 202 "NotUsed_74" 201 "NotUsed_73" 200 "NotUsed_72" 199 "NotUsed_71" 198 "NotUsed_70" 197 "NotUsed_69" 196 "NotUsed_68" 195 "NotUsed_67" 194 "NotUsed_66" 193 "NotUsed_65" 192 "NotUsed_64" 191 "NotUsed_63" 190 "NotUsed_62" 189 "NotUsed_61" 188 "NotUsed_60" 187 "NotUsed_59" 186 "NotUsed_58" 185 "NotUsed_57" 184 "NotUsed_56" 183 "NotUsed_55" 182 "NotUsed_54" 181 "NotUsed_53" 180 "NotUsed_52" 179 "NotUsed_51" 178 "NotUsed_50" 177 "NotUsed_49" 176 "NotUsed_48" 175 "NotUsed_47" 174 "NotUsed_46" 173 "NotUsed_45" 172 "NotUsed_44" 171 "NotUsed_43" 170 "NotUsed_42" 169 "NotUsed_41" 168 "NotUsed_40" 167 "NotUsed_39" 166 "NotUsed_38" 165 "NotUsed_37" 164 "NotUsed_36" 163 "NotUsed_35" 162 "NotUsed_34" 161 "NotUsed_33" 160 "NotUsed_32" 159 "NotUsed_31" 158 "NotUsed_30" 157 "NotUsed_29" 156 "NotUsed_28" 155 "NotUsed_27" 154 "NotUsed_26" 153 "NotUsed_25" 152 "NotUsed_24" 151 "NotUsed_23" 150 "NotUsed_22" 149 "NotUsed_21" 148 "NotUsed_20" 147 "NotUsed_19" 146 "NotUsed_18" 145 "NotUsed_17" 144 "NotUsed_16" 143 "NotUsed_15" 142 "NotUsed_14" 141 "NotUsed_13" 140 "NotUsed_12" 139 "NotUsed_11" 138 "NotUsed_10" 137 "NotUsed_9" 136 "NotUsed_8" 135 "NotUsed_7" 134 "NotUsed_6" 133 "NotUsed_5" 132 "NotUsed_4" 131 "NotUsed_3" 130 "NotUsed_2" 129 "NotUsed_1" 128 "Level127" 127 "Level126" 126 "Level125" 125 "Level124" 124 "Level123" 123 "Level122" 122 "Level121" 121 "Level120" 120 "Level119" 119 "Level118" 118 "Level117" 117 "Level116" 116 "Level115" 115 "Level114" 114 "Level113" 113 "Level112" 112 "Level111" 111 "Level110" 110 "Level109" 109 "Level108" 108 "Level107" 107 "Level106" 106 "Level105" 105 "Level104" 104 "Level103" 103 "Level102" 102 "Level101" 101 "Level100" 100 "Level99" 99 "Level98" 98 "Level97" 97 "Level96" 96 "Level95" 95 "Level94" 94 "Level93" 93 "Level92" 92 "Level91" 91 "Level90" 90 "Level89" 89 "Level88" 88 "Level87" 87 "Level86" 86 "Level85" 85 "Level84" 84 "Level83" 83 "Level82" 82 "Level81" 81 "Level80" 80 "Level79" 79 "Level78" 78 "Level77" 77 "Level76" 76 "Level75" 75 "Level74" 74 "Level73" 73 "Level72" 72 "Level71" 71 "Level70" 70 "Level69" 69 "Level68" 68 "Level67" 67 "Level66" 66 "Level65" 65 "Level64" 64 "Level63" 63 "Level62" 62 "Level61" 61 "Level60" 60 "Level59" 59 "Level58" 58 "Level57" 57 "Level56" 56 "Level55" 55 "Level54" 54 "Level53" 53 "Level52" 52 "Level51" 51 "Level50" 50 "Level49" 49 "Level48" 48 "Level47" 47 "Level46" 46 "Level45" 45 "Level44" 44 "Level43" 43 "Level42" 42 "Level41" 41 "Level40" 40 "Level39" 39 "Level38" 38 "Level37" 37 "Level36" 36 "Level35" 35 "Level34" 34 "Level33" 33 "Level32" 32 "Level31" 31 "Level30" 30 "Level29" 29 "Level28" 28 "Level27" 27 "Level26" 26 "Level25" 25 "Level24" 24 "Level23" 23 "Level22" 22 "Level21" 21 "Level20" 20 "Level19" 19 "Level18" 18 "Level17" 17 "Level16" 16 "Level15" 15 "Level14" 14 "Level13" 13 "Level12" 12 "Level11" 11 "Level10" 10 "Level9" 9 "Level8" 8 "Level7" 7 "Level6" 6 "Level5" 5 "Level4" 4 "Level3" 3 "Level2" 2 "Level1" 1 "Level0" 0 "Inactive" ;
VAL_ 553 InfoSysMasterPw_D_Stat 7 "NotUsed_6" 6 "NotUsed_5" 5 "NotUsed_4" 4 "NotUsed_3" 0 "Inactive" 1 "On" 2 "NotUsed_1" 3 "NotUsed_2" ;
VAL_ 553 ResetTrip1_B_Rq 1 "Reset" 0 "Null" ;
VAL_ 553 Disp_LangSel2_St 32 "Indian_English" 31 "Thai" 30 "Slovak" 29 "Arabic" 28 "Taiwanese" 27 "Mandarin_Chinese" 26 "Korean" 25 "AU_English" 24 "Japanese" 23 "Braz_Portuguese" 22 "EU_Portuguese" 21 "Finish" 20 "Norwegian" 19 "Danish" 18 "Swedish" 17 "Hungarian" 16 "Greek" 15 "Czech" 14 "Polish" 13 "Flemish" 12 "Dutch" 11 "Russian" 10 "Turkish" 9 "Mex_Spanish" 8 "EU_Spanish" 7 "Cana_French" 6 "EU_French" 5 "Italian" 4 "German" 3 "NA_English" 2 "UK_English" 1 "Unknown" 0 "Invalid" ;
VAL_ 553 Disp_LangSel_St 31 "Thai" 30 "Slovak" 29 "Arabic" 28 "Taiwanese" 27 "Mandarin_Chinese" 26 "Korean" 25 "AU_English" 24 "Japanese" 23 "Braz_Portuguese" 22 "EU_Portuguese" 21 "Finish" 20 "Norwegian" 19 "Danish" 18 "Swedish" 17 "Hungarian" 16 "Greek" 15 "Czech" 14 "Polish" 13 "Flemish" 12 "Dutch" 11 "Russian" 10 "Turkish" 9 "Mex_Spanish" 8 "EU_Spanish" 7 "Cana_French" 6 "EU_French" 5 "Italian" 4 "German" 3 "NA_English" 2 "UK_English" 1 "Unknown" 0 "Invalid" ;
VAL_ 553 Diagnostic_Operation_Rq 7 "SignalStrength" 6 "SDARSESNNumber" 5 "SpeakerWalkAround" 4 "CalibrationPartNumber" 15 "Reserved" 3 "HardwarePartNumber" 2 "SoftwarePartNumber" 1 "GetAllBackgroundDiagRq" 0 "Inactive" ;
VAL_ 553 Bezel_Diag_Module_Rq 15 "Reserved" 3 "EFP" 2 "DSP_AMP" 1 "AHU" 0 "Inactive" ;
VAL_ 553 Audio_Demo_CMND 2 "On" 1 "Off" 0 "Inactive" ;
VAL_ 553 Audio_Visualizer 2 "On" 1 "Off" 0 "Inactive" ;
VAL_ 553 Surround_Sound_Upmix 2 "Surround" 1 "Stereo" 0 "Inactive" ;
VAL_ 553 Bezel_Diag_State_Rq 1 "Active" 0 "Inactive" ;
VAL_ 553 SurndSndUpmix2_D_Rq 4 "Audience" 3 "On_Stage" 2 "Surround" 1 "Stereo" 0 "Inactive" ;
